VERSION "14.1.0"

NS_ :

BS_:

BU_: CUSTOMER_ECU PACMOD

//////////////////////////////////
//                              //
//  Message Definition Section  //
//                              //
//////////////////////////////////
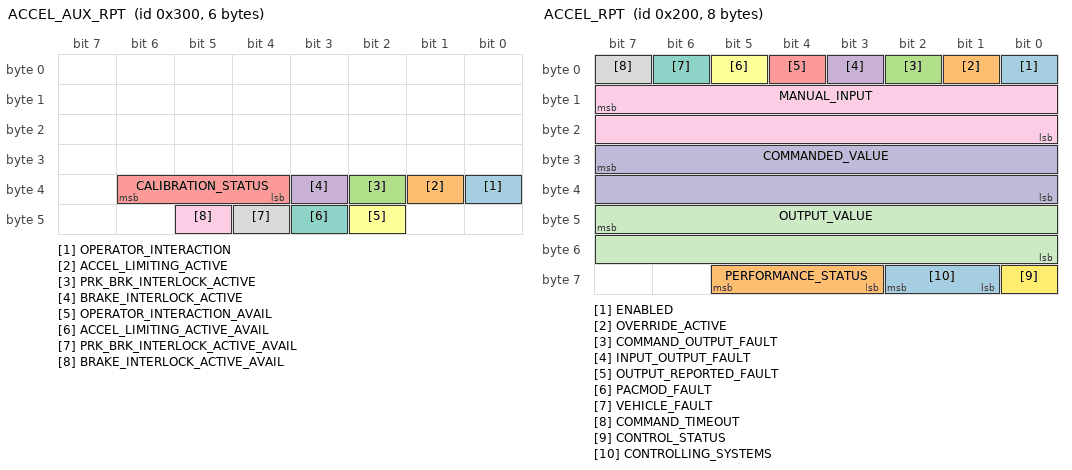
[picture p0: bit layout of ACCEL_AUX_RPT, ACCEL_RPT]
BO_ 768 ACCEL_AUX_RPT: 6 PACMOD
 SG_ OPERATOR_INTERACTION : 32|1@0+ (1,0) [0|1] ""  CUSTOMER_ECU
 SG_ ACCEL_LIMITING_ACTIVE : 33|1@0+ (1,0) [0|1] ""  CUSTOMER_ECU
 SG_ PRK_BRK_INTERLOCK_ACTIVE : 34|1@0+ (1,0) [0|1] ""  CUSTOMER_ECU
 SG_ BRAKE_INTERLOCK_ACTIVE : 35|1@0+ (1,0) [0|1] ""  CUSTOMER_ECU
 SG_ CALIBRATION_STATUS : 38|3@0+ (1,0) [0|3] ""  CUSTOMER_ECU
 SG_ OPERATOR_INTERACTION_AVAIL : 42|1@0+ (1,0) [0|1] ""  CUSTOMER_ECU
 SG_ ACCEL_LIMITING_ACTIVE_AVAIL : 43|1@0+ (1,0) [0|1] ""  CUSTOMER_ECU
 SG_ PRK_BRK_INTERLOCK_ACTIVE_AVAIL : 44|1@0+ (1,0) [0|1] ""  CUSTOMER_ECU
 SG_ BRAKE_INTERLOCK_ACTIVE_AVAIL : 45|1@0+ (1,0) [0|1] ""  CUSTOMER_ECU

BO_ 256 ACCEL_CMD: 3 CUSTOMER_ECU
 SG_ ENABLE : 0|1@0+ (1,0) [0|1] ""  PACMOD
 SG_ IGNORE_OVERRIDES : 1|1@0+ (1,0) [0|1] ""  PACMOD
 SG_ CLEAR_OVERRIDE : 2|1@0+ (1,0) [0|1] ""  PACMOD
 SG_ ACCEL_CMD : 15|16@0+ (0.001,0) [0|1] "ratio"  PACMOD

BO_ 513 ACCEL_CMD_LIMIT_RPT: 4 PACMOD
 SG_ ACCEL_CMD_LIMIT : 7|16@0+ (0.001,0) [0|1] "ratio"  CUSTOMER_ECU
 SG_ LIMITED_ACCEL_CMD : 23|16@0+ (0.001,0) [0|1] "ratio"  CUSTOMER_ECU

BO_ 1090 ACCEL_PEDAL_POSITION_VOLTAGE_RPT: 8 PACMOD
 SG_ PACMOD_VOLTAGE_IN_1 : 7|16@0+ (0.001,0) [0|65] "V"  CUSTOMER_ECU
 SG_ PACMOD_VOLTAGE_IN_2 : 23|16@0+ (0.001,0) [0|65] "V"  CUSTOMER_ECU
 SG_ PACMOD_VOLTAGE_OUT_1 : 39|16@0+ (0.001,0) [0|65] "V"  CUSTOMER_ECU
 SG_ PACMOD_VOLTAGE_OUT_2 : 55|16@0+ (0.001,0) [0|65] "V"  CUSTOMER_ECU

BO_ 512 ACCEL_RPT: 8 PACMOD
 SG_ ENABLED : 0|1@0+ (1,0) [0|1] ""  CUSTOMER_ECU
 SG_ OVERRIDE_ACTIVE : 1|1@0+ (1,0) [0|1] ""  CUSTOMER_ECU
 SG_ COMMAND_OUTPUT_FAULT : 2|1@0+ (1,0) [0|1] ""  CUSTOMER_ECU
 SG_ INPUT_OUTPUT_FAULT : 3|1@0+ (1,0) [0|1] ""  CUSTOMER_ECU
 SG_ OUTPUT_REPORTED_FAULT : 4|1@0+ (1,0) [0|1] ""  CUSTOMER_ECU
 SG_ PACMOD_FAULT : 5|1@0+ (1,0) [0|1] ""  CUSTOMER_ECU
 SG_ VEHICLE_FAULT : 6|1@0+ (1,0) [0|1] ""  CUSTOMER_ECU
 SG_ COMMAND_TIMEOUT : 7|1@0+ (1,0) [0|1] ""  CUSTOMER_ECU
 SG_ MANUAL_INPUT : 15|16@0+ (0.001,0) [0|1] "ratio"  CUSTOMER_ECU
 SG_ COMMANDED_VALUE : 31|16@0+ (0.001,0) [0|1] "ratio"  CUSTOMER_ECU
 SG_ OUTPUT_VALUE : 47|16@0+ (0.001,0) [0|1] "ratio"  CUSTOMER_ECU
 SG_ CONTROL_STATUS : 56|1@0+ (1,0) [0|1] ""  CUSTOMER_ECU
 SG_ CONTROLLING_SYSTEMS : 58|2@0+ (1,0) [0|3] ""  CUSTOMER_ECU
 SG_ PERFORMANCE_STATUS : 61|3@0+ (1,0) [0|4] ""  CUSTOMER_ECU

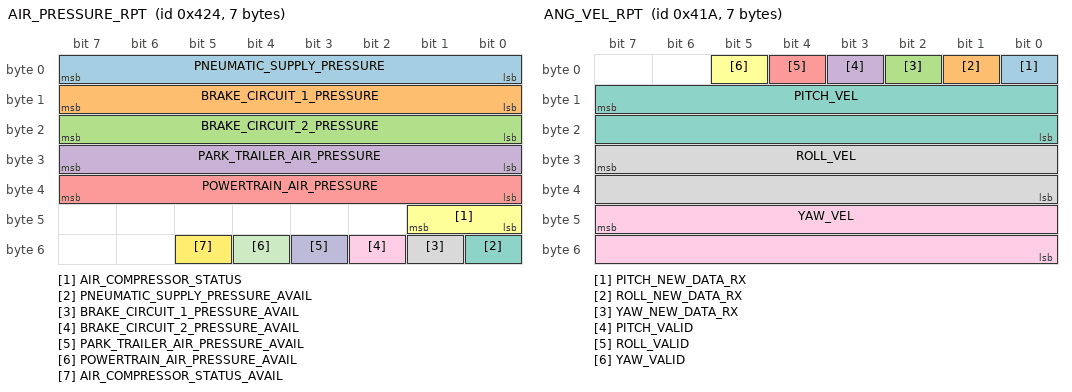
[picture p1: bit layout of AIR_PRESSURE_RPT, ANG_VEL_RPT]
BO_ 1060 AIR_PRESSURE_RPT: 7 PACMOD
 SG_ PNEUMATIC_SUPPLY_PRESSURE : 7|8@0+ (8,0) [0|2000] "kPa"  CUSTOMER_ECU
 SG_ BRAKE_CIRCUIT_1_PRESSURE : 15|8@0+ (8,0) [0|2000] "kPa"  CUSTOMER_ECU
 SG_ BRAKE_CIRCUIT_2_PRESSURE : 23|8@0+ (8,0) [0|2000] "kPa"  CUSTOMER_ECU
 SG_ PARK_TRAILER_AIR_PRESSURE : 31|8@0+ (8,0) [0|2000] "kPa"  CUSTOMER_ECU
 SG_ POWERTRAIN_AIR_PRESSURE : 39|8@0+ (8,0) [0|2000] "kPa"  CUSTOMER_ECU
 SG_ AIR_COMPRESSOR_STATUS : 41|2@0+ (1,0) [0|3] ""  CUSTOMER_ECU
 SG_ PNEUMATIC_SUPPLY_PRESSURE_AVAIL : 48|1@0+ (1,0) [0|1] ""  CUSTOMER_ECU
 SG_ BRAKE_CIRCUIT_1_PRESSURE_AVAIL : 49|1@0+ (1,0) [0|1] ""  CUSTOMER_ECU
 SG_ BRAKE_CIRCUIT_2_PRESSURE_AVAIL : 50|1@0+ (1,0) [0|1] ""  CUSTOMER_ECU
 SG_ PARK_TRAILER_AIR_PRESSURE_AVAIL : 51|1@0+ (1,0) [0|1] ""  CUSTOMER_ECU
 SG_ POWERTRAIN_AIR_PRESSURE_AVAIL : 52|1@0+ (1,0) [0|1] ""  CUSTOMER_ECU
 SG_ AIR_COMPRESSOR_STATUS_AVAIL : 53|1@0+ (1,0) [0|1] ""  CUSTOMER_ECU

BO_ 1094 AMBIENT_CONDITION_RPT: 2 PACMOD
 SG_ INTERIOR_AMBIENT_TEMP : 7|8@0+ (0.5,0) [-40|82.5] "C"  CUSTOMER_ECU
 SG_ INTERIOR_AMBIENT_TEMP_WARNING : 9|2@0+ (1,0) [0|3] ""  CUSTOMER_ECU

BO_ 1050 ANG_VEL_RPT: 7 PACMOD
 SG_ PITCH_NEW_DATA_RX : 0|1@0+ (1,0) [0|1] ""  CUSTOMER_ECU
 SG_ ROLL_NEW_DATA_RX : 1|1@0+ (1,0) [0|1] ""  CUSTOMER_ECU
 SG_ YAW_NEW_DATA_RX : 2|1@0+ (1,0) [0|1] ""  CUSTOMER_ECU
 SG_ PITCH_VALID : 3|1@0+ (1,0) [0|1] ""  CUSTOMER_ECU
 SG_ ROLL_VALID : 4|1@0+ (1,0) [0|1] ""  CUSTOMER_ECU
 SG_ YAW_VALID : 5|1@0+ (1,0) [0|1] ""  CUSTOMER_ECU
 SG_ PITCH_VEL : 15|16@0- (0.001,0) [-32.768|32.767] "rad/s"  CUSTOMER_ECU
 SG_ ROLL_VEL : 31|16@0- (0.001,0) [-32.768|32.767] "rad/s"  CUSTOMER_ECU
 SG_ YAW_VEL : 47|16@0- (0.001,0) [-32.768|32.767] "rad/s"  CUSTOMER_ECU

BO_ 1077 AUTOMS_MAN_SWITCH_RPT: 1 PACMOD
 SG_ AUTOMS_MAN_OPCTRL : 1|2@0+ (1,0) [0|2] ""  CUSTOMER_ECU
 SG_ AUTOMS_MAN_EXTCTRL : 3|2@0+ (1,0) [0|2] ""  CUSTOMER_ECU
 SG_ AUTOMS_MAN_OPCTRL_AVAIL : 4|1@0+ (1,0) [0|1] ""  CUSTOMER_ECU
 SG_ AUTOMS_MAN_EXTCTRL_AVAIL : 5|1@0+ (1,0) [0|1] ""  CUSTOMER_ECU

BO_ 1070 BATTERY_VOLTAGE_LEVEL_RPT_1: 2 PACMOD
 SG_ BATTERY_VOLTAGE_1 : 7|8@0+ (0.2,0) [0|50] "V"  CUSTOMER_ECU
 SG_ BATTERY_VOLTAGE_2 : 15|8@0+ (0.2,0) [0|50] "V"  CUSTOMER_ECU

BO_ 1081 BATTERY_VOLTAGE_LEVEL_RPT_2: 2 PACMOD
 SG_ BATTERY_VOLTAGE_1 : 7|8@0+ (0.2,0) [0|50] "V"  CUSTOMER_ECU
 SG_ BATTERY_VOLTAGE_2 : 15|8@0+ (0.2,0) [0|50] "V"  CUSTOMER_ECU

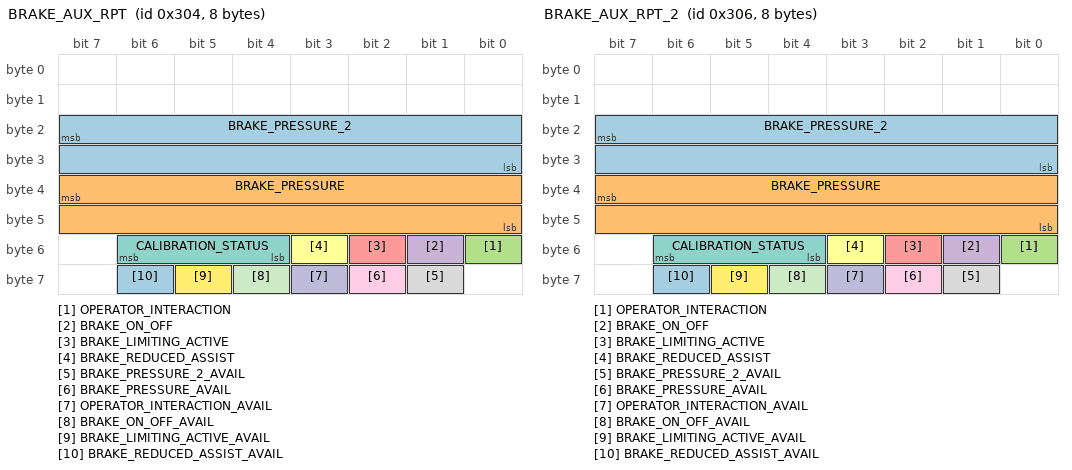
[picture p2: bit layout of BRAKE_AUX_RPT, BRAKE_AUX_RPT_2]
BO_ 772 BRAKE_AUX_RPT: 8 PACMOD
 SG_ BRAKE_PRESSURE_2 : 23|16@0+ (0.0001,0) [0|2] "ratio"  CUSTOMER_ECU
 SG_ BRAKE_PRESSURE : 39|16@0+ (0.0001,0) [0|2] "ratio"  CUSTOMER_ECU
 SG_ OPERATOR_INTERACTION : 48|1@0+ (1,0) [0|1] ""  CUSTOMER_ECU
 SG_ BRAKE_ON_OFF : 49|1@0+ (1,0) [0|1] ""  CUSTOMER_ECU
 SG_ BRAKE_LIMITING_ACTIVE : 50|1@0+ (1,0) [0|1] ""  CUSTOMER_ECU
 SG_ BRAKE_REDUCED_ASSIST : 51|1@0+ (1,0) [0|1] ""  CUSTOMER_ECU
 SG_ CALIBRATION_STATUS : 54|3@0+ (1,0) [0|3] ""  CUSTOMER_ECU
 SG_ BRAKE_PRESSURE_2_AVAIL : 57|1@0+ (1,0) [0|1] ""  CUSTOMER_ECU
 SG_ BRAKE_PRESSURE_AVAIL : 58|1@0+ (1,0) [0|1] ""  CUSTOMER_ECU
 SG_ OPERATOR_INTERACTION_AVAIL : 59|1@0+ (1,0) [0|1] ""  CUSTOMER_ECU
 SG_ BRAKE_ON_OFF_AVAIL : 60|1@0+ (1,0) [0|1] ""  CUSTOMER_ECU
 SG_ BRAKE_LIMITING_ACTIVE_AVAIL : 61|1@0+ (1,0) [0|1] ""  CUSTOMER_ECU
 SG_ BRAKE_REDUCED_ASSIST_AVAIL : 62|1@0+ (1,0) [0|1] ""  CUSTOMER_ECU

BO_ 774 BRAKE_AUX_RPT_2: 8 PACMOD
 SG_ BRAKE_PRESSURE_2 : 23|16@0+ (0.0001,0) [0|2] "ratio"  CUSTOMER_ECU
 SG_ BRAKE_PRESSURE : 39|16@0+ (0.0001,0) [0|2] "ratio"  CUSTOMER_ECU
 SG_ OPERATOR_INTERACTION : 48|1@0+ (1,0) [0|1] ""  CUSTOMER_ECU
 SG_ BRAKE_ON_OFF : 49|1@0+ (1,0) [0|1] ""  CUSTOMER_ECU
 SG_ BRAKE_LIMITING_ACTIVE : 50|1@0+ (1,0) [0|1] ""  CUSTOMER_ECU
 SG_ BRAKE_REDUCED_ASSIST : 51|1@0+ (1,0) [0|1] ""  CUSTOMER_ECU
 SG_ CALIBRATION_STATUS : 54|3@0+ (1,0) [0|3] ""  CUSTOMER_ECU
 SG_ BRAKE_PRESSURE_2_AVAIL : 57|1@0+ (1,0) [0|1] ""  CUSTOMER_ECU
 SG_ BRAKE_PRESSURE_AVAIL : 58|1@0+ (1,0) [0|1] ""  CUSTOMER_ECU
 SG_ OPERATOR_INTERACTION_AVAIL : 59|1@0+ (1,0) [0|1] ""  CUSTOMER_ECU
 SG_ BRAKE_ON_OFF_AVAIL : 60|1@0+ (1,0) [0|1] ""  CUSTOMER_ECU
 SG_ BRAKE_LIMITING_ACTIVE_AVAIL : 61|1@0+ (1,0) [0|1] ""  CUSTOMER_ECU
 SG_ BRAKE_REDUCED_ASSIST_AVAIL : 62|1@0+ (1,0) [0|1] ""  CUSTOMER_ECU

BO_ 260 BRAKE_CMD: 3 CUSTOMER_ECU
 SG_ ENABLE : 0|1@0+ (1,0) [0|1] ""  PACMOD
 SG_ IGNORE_OVERRIDES : 1|1@0+ (1,0) [0|1] ""  PACMOD
 SG_ CLEAR_OVERRIDE : 2|1@0+ (1,0) [0|1] ""  PACMOD
 SG_ BRAKE_CMD : 15|16@0+ (0.001,0) [0|1] "ratio"  PACMOD

BO_ 517 BRAKE_CMD_LIMIT_RPT: 4 PACMOD
 SG_ BRAKE_CMD_LIMIT : 7|16@0+ (0.001,0) [0|1] "ratio"  CUSTOMER_ECU
 SG_ LIMITED_BRAKE_CMD : 23|16@0+ (0.001,0) [0|1] "ratio"  CUSTOMER_ECU

BO_ 824 BRAKE_DECEL_AUX_RPT: 3 PACMOD
 SG_ XBR_ACTIVE_CONTROL_MODE : 3|4@0+ (1,0) [0|2] ""  CUSTOMER_ECU
 SG_ XBR_SYSTEM_STATE : 5|2@0+ (1,0) [0|3] ""  CUSTOMER_ECU
 SG_ FOUNDATION_BRAKE_USE : 7|2@0+ (1,0) [0|2] ""  CUSTOMER_ECU
 SG_ HILL_HOLDER_MODE : 10|3@0+ (1,0) [0|2] ""  CUSTOMER_ECU
 SG_ XBR_ACTIVE_CONTROL_MODE_AVAIL : 16|1@0+ (1,0) [0|1] ""  CUSTOMER_ECU
 SG_ XBR_SYSTEM_STATE_AVAIL : 17|1@0+ (1,0) [0|1] ""  CUSTOMER_ECU
 SG_ FOUNDATION_BRAKE_USE_AVAIL : 18|1@0+ (1,0) [0|1] ""  CUSTOMER_ECU
 SG_ HILL_HOLDER_MODE_AVAIL : 19|1@0+ (1,0) [0|1] ""  CUSTOMER_ECU

BO_ 316 BRAKE_DECEL_CMD: 4 CUSTOMER_ECU
 SG_ ENABLE : 0|1@0+ (1,0) [0|1] ""  PACMOD
 SG_ IGNORE_OVERRIDES : 1|1@0+ (1,0) [0|1] ""  PACMOD
 SG_ CLEAR_OVERRIDE : 2|1@0+ (1,0) [0|1] ""  PACMOD
 SG_ BRAKE_DECEL_CMD : 15|16@0+ (0.001,0) [0|10] "m/s^2"  PACMOD
 SG_ XBR_EBI_MODE : 25|2@0+ (1,0) [0|2] ""  PACMOD
 SG_ XBR_PRIORITY : 27|2@0+ (1,0) [0|3] ""  PACMOD
 SG_ XBR_CONTROL_MODE : 29|2@0+ (1,0) [0|2] ""  PACMOD

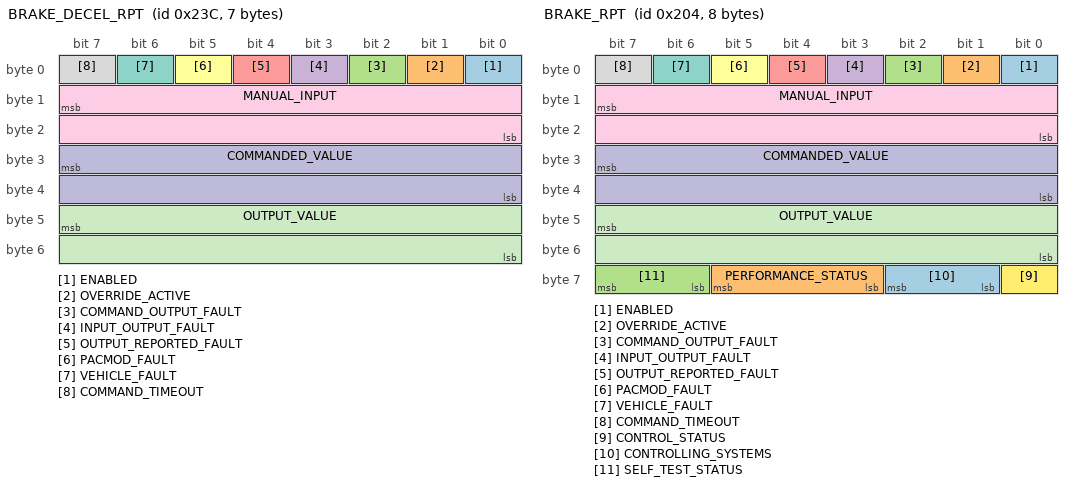
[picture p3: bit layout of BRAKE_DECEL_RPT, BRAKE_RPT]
BO_ 572 BRAKE_DECEL_RPT: 7 PACMOD
 SG_ ENABLED : 0|1@0+ (1,0) [0|1] ""  CUSTOMER_ECU
 SG_ OVERRIDE_ACTIVE : 1|1@0+ (1,0) [0|1] ""  CUSTOMER_ECU
 SG_ COMMAND_OUTPUT_FAULT : 2|1@0+ (1,0) [0|1] ""  CUSTOMER_ECU
 SG_ INPUT_OUTPUT_FAULT : 3|1@0+ (1,0) [0|1] ""  CUSTOMER_ECU
 SG_ OUTPUT_REPORTED_FAULT : 4|1@0+ (1,0) [0|1] ""  CUSTOMER_ECU
 SG_ PACMOD_FAULT : 5|1@0+ (1,0) [0|1] ""  CUSTOMER_ECU
 SG_ VEHICLE_FAULT : 6|1@0+ (1,0) [0|1] ""  CUSTOMER_ECU
 SG_ COMMAND_TIMEOUT : 7|1@0+ (1,0) [0|1] ""  CUSTOMER_ECU
 SG_ MANUAL_INPUT : 15|16@0+ (0.001,0) [0|10] "m/s^2"  CUSTOMER_ECU
 SG_ COMMANDED_VALUE : 31|16@0+ (0.001,0) [0|10] "m/s^2"  CUSTOMER_ECU
 SG_ OUTPUT_VALUE : 47|16@0+ (0.001,0) [0|10] "m/s^2"  CUSTOMER_ECU

BO_ 1091 BRAKE_MC_VOLTAGE_RPT: 8 PACMOD
 SG_ PACMOD_VOLTAGE_IN_1 : 7|16@0+ (0.001,0) [0|65] "V"  CUSTOMER_ECU
 SG_ PACMOD_VOLTAGE_IN_2 : 23|16@0+ (0.001,0) [0|65] "V"  CUSTOMER_ECU
 SG_ PACMOD_VOLTAGE_OUT_1 : 39|16@0+ (0.001,0) [0|65] "V"  CUSTOMER_ECU
 SG_ PACMOD_VOLTAGE_OUT_2 : 55|16@0+ (0.001,0) [0|65] "V"  CUSTOMER_ECU

BO_ 1025 BRAKE_MOTOR_RPT_1: 8 PACMOD
 SG_ MOTOR_CURRENT : 7|32@0- (0.001,0) [-2048.0|2048.0] "amps"  CUSTOMER_ECU
 SG_ SHAFT_POSITION : 39|32@0- (0.001,0) [-2048.0|2048.0] "radians"  CUSTOMER_ECU

BO_ 1026 BRAKE_MOTOR_RPT_2: 8 PACMOD
 SG_ ENCODER_TEMPERATURE : 7|16@0- (1,0) [-40|210] "deg_C"  CUSTOMER_ECU
 SG_ MOTOR_TEMPERATURE : 23|16@0- (1,0) [-40|210] "deg_C"  CUSTOMER_ECU
 SG_ ANGULAR_SPEED : 39|32@0- (0.001,0) [-12868.0|12868.0] "rad/s"  CUSTOMER_ECU

BO_ 1027 BRAKE_MOTOR_RPT_3: 8 PACMOD
 SG_ TORQUE_OUTPUT : 7|32@0- (0.001,0) [-2048.0|2048.0] "N-m"  CUSTOMER_ECU
 SG_ TORQUE_INPUT : 39|32@0- (0.001,0) [-2048.0|2048.0] "N-m"  CUSTOMER_ECU

BO_ 1092 BRAKE_PEDAL_POSITION_VOLTAGE_RPT: 8 PACMOD
 SG_ PACMOD_VOLTAGE_IN_1 : 7|16@0+ (0.001,0) [0|65] "V"  CUSTOMER_ECU
 SG_ PACMOD_VOLTAGE_IN_2 : 23|16@0+ (0.001,0) [0|65] "V"  CUSTOMER_ECU
 SG_ PACMOD_VOLTAGE_OUT_1 : 39|16@0+ (0.001,0) [0|65] "V"  CUSTOMER_ECU
 SG_ PACMOD_VOLTAGE_OUT_2 : 55|16@0+ (0.001,0) [0|65] "V"  CUSTOMER_ECU

BO_ 516 BRAKE_RPT: 8 PACMOD
 SG_ ENABLED : 0|1@0+ (1,0) [0|1] ""  CUSTOMER_ECU
 SG_ OVERRIDE_ACTIVE : 1|1@0+ (1,0) [0|1] ""  CUSTOMER_ECU
 SG_ COMMAND_OUTPUT_FAULT : 2|1@0+ (1,0) [0|1] ""  CUSTOMER_ECU
 SG_ INPUT_OUTPUT_FAULT : 3|1@0+ (1,0) [0|1] ""  CUSTOMER_ECU
 SG_ OUTPUT_REPORTED_FAULT : 4|1@0+ (1,0) [0|1] ""  CUSTOMER_ECU
 SG_ PACMOD_FAULT : 5|1@0+ (1,0) [0|1] ""  CUSTOMER_ECU
 SG_ VEHICLE_FAULT : 6|1@0+ (1,0) [0|1] ""  CUSTOMER_ECU
 SG_ COMMAND_TIMEOUT : 7|1@0+ (1,0) [0|1] ""  CUSTOMER_ECU
 SG_ MANUAL_INPUT : 15|16@0+ (0.001,0) [0|1] "ratio"  CUSTOMER_ECU
 SG_ COMMANDED_VALUE : 31|16@0+ (0.001,0) [0|1] "ratio"  CUSTOMER_ECU
 SG_ OUTPUT_VALUE : 47|16@0+ (0.001,0) [0|1] "ratio"  CUSTOMER_ECU
 SG_ CONTROL_STATUS : 56|1@0+ (1,0) [0|1] ""  CUSTOMER_ECU
 SG_ CONTROLLING_SYSTEMS : 58|2@0+ (1,0) [0|3] ""  CUSTOMER_ECU
 SG_ PERFORMANCE_STATUS : 61|3@0+ (1,0) [0|4] ""  CUSTOMER_ECU
 SG_ SELF_TEST_STATUS : 63|2@0+ (1,0) [0|3] ""  CUSTOMER_ECU

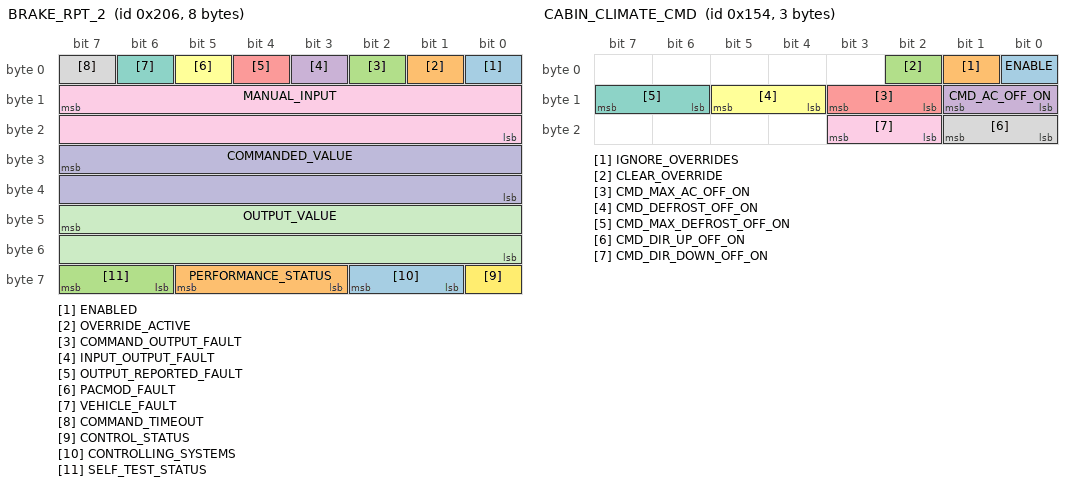
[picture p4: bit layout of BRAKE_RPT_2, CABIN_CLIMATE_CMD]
BO_ 518 BRAKE_RPT_2: 8 PACMOD
 SG_ ENABLED : 0|1@0+ (1,0) [0|1] ""  CUSTOMER_ECU
 SG_ OVERRIDE_ACTIVE : 1|1@0+ (1,0) [0|1] ""  CUSTOMER_ECU
 SG_ COMMAND_OUTPUT_FAULT : 2|1@0+ (1,0) [0|1] ""  CUSTOMER_ECU
 SG_ INPUT_OUTPUT_FAULT : 3|1@0+ (1,0) [0|1] ""  CUSTOMER_ECU
 SG_ OUTPUT_REPORTED_FAULT : 4|1@0+ (1,0) [0|1] ""  CUSTOMER_ECU
 SG_ PACMOD_FAULT : 5|1@0+ (1,0) [0|1] ""  CUSTOMER_ECU
 SG_ VEHICLE_FAULT : 6|1@0+ (1,0) [0|1] ""  CUSTOMER_ECU
 SG_ COMMAND_TIMEOUT : 7|1@0+ (1,0) [0|1] ""  CUSTOMER_ECU
 SG_ MANUAL_INPUT : 15|16@0+ (0.001,0) [0|1] "ratio"  CUSTOMER_ECU
 SG_ COMMANDED_VALUE : 31|16@0+ (0.001,0) [0|1] "ratio"  CUSTOMER_ECU
 SG_ OUTPUT_VALUE : 47|16@0+ (0.001,0) [0|1] "ratio"  CUSTOMER_ECU
 SG_ CONTROL_STATUS : 56|1@0+ (1,0) [0|1] ""  CUSTOMER_ECU
 SG_ CONTROLLING_SYSTEMS : 58|2@0+ (1,0) [0|3] ""  CUSTOMER_ECU
 SG_ PERFORMANCE_STATUS : 61|3@0+ (1,0) [0|4] ""  CUSTOMER_ECU
 SG_ SELF_TEST_STATUS : 63|2@0+ (1,0) [0|3] ""  CUSTOMER_ECU

BO_ 340 CABIN_CLIMATE_CMD: 3 CUSTOMER_ECU
 SG_ ENABLE : 0|1@0+ (1,0) [0|1] ""  PACMOD
 SG_ IGNORE_OVERRIDES : 1|1@0+ (1,0) [0|1] ""  PACMOD
 SG_ CLEAR_OVERRIDE : 2|1@0+ (1,0) [0|1] ""  PACMOD
 SG_ CMD_AC_OFF_ON : 9|2@0+ (1,0) [0|1] ""  PACMOD
 SG_ CMD_MAX_AC_OFF_ON : 11|2@0+ (1,0) [0|1] ""  PACMOD
 SG_ CMD_DEFROST_OFF_ON : 13|2@0+ (1,0) [0|1] ""  PACMOD
 SG_ CMD_MAX_DEFROST_OFF_ON : 15|2@0+ (1,0) [0|1] ""  PACMOD
 SG_ CMD_DIR_UP_OFF_ON : 17|2@0+ (1,0) [0|1] ""  PACMOD
 SG_ CMD_DIR_DOWN_OFF_ON : 19|2@0+ (1,0) [0|1] ""  PACMOD

BO_ 596 CABIN_CLIMATE_RPT: 7 PACMOD
 SG_ ENABLED : 0|1@0+ (1,0) [0|1] ""  CUSTOMER_ECU
 SG_ OVERRIDE_ACTIVE : 1|1@0+ (1,0) [0|1] ""  CUSTOMER_ECU
 SG_ COMMAND_OUTPUT_FAULT : 2|1@0+ (1,0) [0|1] ""  CUSTOMER_ECU
 SG_ INPUT_OUTPUT_FAULT : 3|1@0+ (1,0) [0|1] ""  CUSTOMER_ECU
 SG_ OUTPUT_REPORTED_FAULT : 4|1@0+ (1,0) [0|1] ""  CUSTOMER_ECU
 SG_ PACMOD_FAULT : 5|1@0+ (1,0) [0|1] ""  CUSTOMER_ECU
 SG_ VEHICLE_FAULT : 6|1@0+ (1,0) [0|1] ""  CUSTOMER_ECU
 SG_ COMMAND_TIMEOUT : 7|1@0+ (1,0) [0|1] ""  CUSTOMER_ECU
 SG_ MAN_AC_OFF_ON : 9|2@0+ (1,0) [0|3] ""  CUSTOMER_ECU
 SG_ MAN_MAX_AC_OFF_ON : 11|2@0+ (1,0) [0|3] ""  CUSTOMER_ECU
 SG_ MAN_DEFROST_OFF_ON : 13|2@0+ (1,0) [0|3] ""  CUSTOMER_ECU
 SG_ MAN_MAX_DEFROST_OFF_ON : 15|2@0+ (1,0) [0|3] ""  CUSTOMER_ECU
 SG_ MAN_DIR_UP_OFF_ON : 17|2@0+ (1,0) [0|3] ""  CUSTOMER_ECU
 SG_ MAN_DIR_DOWN_OFF_ON : 19|2@0+ (1,0) [0|3] ""  CUSTOMER_ECU
 SG_ CMD_AC_OFF_ON : 25|2@0+ (1,0) [0|3] ""  CUSTOMER_ECU
 SG_ CMD_MAX_AC_OFF_ON : 27|2@0+ (1,0) [0|3] ""  CUSTOMER_ECU
 SG_ CMD_DEFROST_OFF_ON : 29|2@0+ (1,0) [0|3] ""  CUSTOMER_ECU
 SG_ CMD_MAX_DEFROST_OFF_ON : 31|2@0+ (1,0) [0|3] ""  CUSTOMER_ECU
 SG_ CMD_DIR_UP_OFF_ON : 33|2@0+ (1,0) [0|3] ""  CUSTOMER_ECU
 SG_ CMD_DIR_DOWN_OFF_ON : 35|2@0+ (1,0) [0|3] ""  CUSTOMER_ECU
 SG_ OUT_AC_OFF_ON : 41|2@0+ (1,0) [0|3] ""  CUSTOMER_ECU
 SG_ OUT_MAX_AC_OFF_ON : 43|2@0+ (1,0) [0|3] ""  CUSTOMER_ECU
 SG_ OUT_DEFROST_OFF_ON : 45|2@0+ (1,0) [0|3] ""  CUSTOMER_ECU
 SG_ OUT_MAX_DEFROST_OFF_ON : 47|2@0+ (1,0) [0|3] ""  CUSTOMER_ECU
 SG_ OUT_DIR_UP_OFF_ON : 49|2@0+ (1,0) [0|3] ""  CUSTOMER_ECU
 SG_ OUT_DIR_DOWN_OFF_ON : 51|2@0+ (1,0) [0|3] ""  CUSTOMER_ECU

BO_ 336 CABIN_FAN_SPEED_CMD: 2 CUSTOMER_ECU
 SG_ ENABLE : 0|1@0+ (1,0) [0|1] ""  PACMOD
 SG_ IGNORE_OVERRIDES : 1|1@0+ (1,0) [0|1] ""  PACMOD
 SG_ CLEAR_OVERRIDE : 2|1@0+ (1,0) [0|1] ""  PACMOD
 SG_ CABIN_FAN_SPEED_CMD : 15|8@0+ (1,0) [0|10] ""  PACMOD

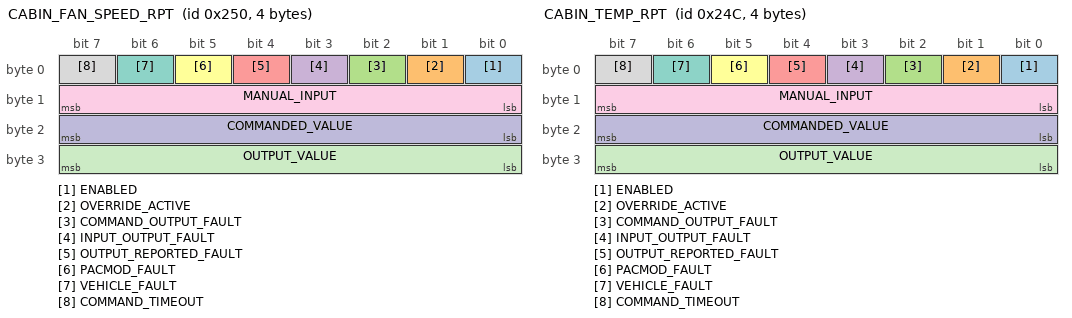
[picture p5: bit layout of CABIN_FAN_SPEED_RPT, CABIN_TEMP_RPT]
BO_ 592 CABIN_FAN_SPEED_RPT: 4 PACMOD
 SG_ ENABLED : 0|1@0+ (1,0) [0|1] ""  CUSTOMER_ECU
 SG_ OVERRIDE_ACTIVE : 1|1@0+ (1,0) [0|1] ""  CUSTOMER_ECU
 SG_ COMMAND_OUTPUT_FAULT : 2|1@0+ (1,0) [0|1] ""  CUSTOMER_ECU
 SG_ INPUT_OUTPUT_FAULT : 3|1@0+ (1,0) [0|1] ""  CUSTOMER_ECU
 SG_ OUTPUT_REPORTED_FAULT : 4|1@0+ (1,0) [0|1] ""  CUSTOMER_ECU
 SG_ PACMOD_FAULT : 5|1@0+ (1,0) [0|1] ""  CUSTOMER_ECU
 SG_ VEHICLE_FAULT : 6|1@0+ (1,0) [0|1] ""  CUSTOMER_ECU
 SG_ COMMAND_TIMEOUT : 7|1@0+ (1,0) [0|1] ""  CUSTOMER_ECU
 SG_ MANUAL_INPUT : 15|8@0+ (1,0) [0|255] ""  CUSTOMER_ECU
 SG_ COMMANDED_VALUE : 23|8@0+ (1,0) [0|255] ""  CUSTOMER_ECU
 SG_ OUTPUT_VALUE : 31|8@0+ (1,0) [0|255] ""  CUSTOMER_ECU

BO_ 332 CABIN_TEMP_CMD: 2 CUSTOMER_ECU
 SG_ ENABLE : 0|1@0+ (1,0) [0|1] ""  PACMOD
 SG_ IGNORE_OVERRIDES : 1|1@0+ (1,0) [0|1] ""  PACMOD
 SG_ CLEAR_OVERRIDE : 2|1@0+ (1,0) [0|1] ""  PACMOD
 SG_ CABIN_TEMP_CMD : 15|8@0+ (0.1,10) [10|35] "deg_C"  PACMOD

BO_ 588 CABIN_TEMP_RPT: 4 PACMOD
 SG_ ENABLED : 0|1@0+ (1,0) [0|1] ""  CUSTOMER_ECU
 SG_ OVERRIDE_ACTIVE : 1|1@0+ (1,0) [0|1] ""  CUSTOMER_ECU
 SG_ COMMAND_OUTPUT_FAULT : 2|1@0+ (1,0) [0|1] ""  CUSTOMER_ECU
 SG_ INPUT_OUTPUT_FAULT : 3|1@0+ (1,0) [0|1] ""  CUSTOMER_ECU
 SG_ OUTPUT_REPORTED_FAULT : 4|1@0+ (1,0) [0|1] ""  CUSTOMER_ECU
 SG_ PACMOD_FAULT : 5|1@0+ (1,0) [0|1] ""  CUSTOMER_ECU
 SG_ VEHICLE_FAULT : 6|1@0+ (1,0) [0|1] ""  CUSTOMER_ECU
 SG_ COMMAND_TIMEOUT : 7|1@0+ (1,0) [0|1] ""  CUSTOMER_ECU
 SG_ MANUAL_INPUT : 15|8@0+ (0.1,10) [10|35] "deg_C"  CUSTOMER_ECU
 SG_ COMMANDED_VALUE : 23|8@0+ (0.1,10) [10|35] "deg_C"  CUSTOMER_ECU
 SG_ OUTPUT_VALUE : 31|8@0+ (0.1,10) [10|35] "deg_C"  CUSTOMER_ECU

BO_ 1100 COMPONENT_AUX_RPT_00: 1 PACMOD
 SG_ LOCATION_CODE : 3|4@0+ (1,0) [0|15] "" CUSTOMER_ECU
 SG_ KEY_SWITCH_STATUS : 5|2@0+ (1,0) [0|3] "" CUSTOMER_ECU

BO_ 1101 COMPONENT_AUX_RPT_01: 1 PACMOD
 SG_ LOCATION_CODE : 3|4@0+ (1,0) [0|15] "" CUSTOMER_ECU
 SG_ KEY_SWITCH_STATUS : 5|2@0+ (1,0) [0|3] "" CUSTOMER_ECU

BO_ 1102 COMPONENT_AUX_RPT_02: 1 PACMOD
 SG_ LOCATION_CODE : 3|4@0+ (1,0) [0|15] "" CUSTOMER_ECU
 SG_ KEY_SWITCH_STATUS : 5|2@0+ (1,0) [0|3] "" CUSTOMER_ECU

BO_ 1103 COMPONENT_AUX_RPT_03: 1 PACMOD
 SG_ LOCATION_CODE : 3|4@0+ (1,0) [0|15] "" CUSTOMER_ECU
 SG_ KEY_SWITCH_STATUS : 5|2@0+ (1,0) [0|3] "" CUSTOMER_ECU

BO_ 1104 COMPONENT_AUX_RPT_04: 1 PACMOD
 SG_ LOCATION_CODE : 3|4@0+ (1,0) [0|15] "" CUSTOMER_ECU
 SG_ KEY_SWITCH_STATUS : 5|2@0+ (1,0) [0|3] "" CUSTOMER_ECU

BO_ 1105 COMPONENT_AUX_RPT_05: 1 PACMOD
 SG_ LOCATION_CODE : 3|4@0+ (1,0) [0|15] "" CUSTOMER_ECU
 SG_ KEY_SWITCH_STATUS : 5|2@0+ (1,0) [0|3] "" CUSTOMER_ECU

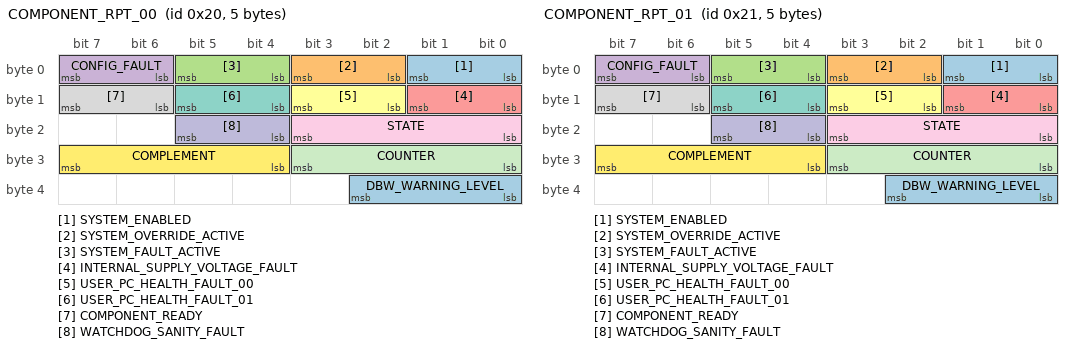
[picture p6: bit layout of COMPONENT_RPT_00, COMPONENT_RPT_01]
BO_ 32 COMPONENT_RPT_00: 5 PACMOD
 SG_ SYSTEM_ENABLED : 1|2@0+ (1,0) [0|3] "" CUSTOMER_ECU
 SG_ SYSTEM_OVERRIDE_ACTIVE : 3|2@0+ (1,0) [0|3] "" CUSTOMER_ECU
 SG_ SYSTEM_FAULT_ACTIVE : 5|2@0+ (1,0) [0|3] "" CUSTOMER_ECU
 SG_ CONFIG_FAULT : 7|2@0+ (1,0) [0|3] "" CUSTOMER_ECU
 SG_ INTERNAL_SUPPLY_VOLTAGE_FAULT : 9|2@0+ (1,0) [0|3] "" CUSTOMER_ECU
 SG_ USER_PC_HEALTH_FAULT_00 : 11|2@0+ (1,0) [0|3] "" CUSTOMER_ECU
 SG_ USER_PC_HEALTH_FAULT_01 : 13|2@0+ (1,0) [0|3] "" CUSTOMER_ECU
 SG_ COMPONENT_READY : 15|2@0+ (1,0) [0|3] "" CUSTOMER_ECU
 SG_ STATE : 19|4@0+ (1,0) [0|15] "" CUSTOMER_ECU
 SG_ WATCHDOG_SANITY_FAULT : 21|2@0+ (1,0) [0|3] "" CUSTOMER_ECU
 SG_ COUNTER : 27|4@0+ (1,0) [0|15] "" CUSTOMER_ECU
 SG_ COMPLEMENT : 31|4@0+ (1,0) [0|15] "" CUSTOMER_ECU
 SG_ DBW_WARNING_LEVEL : 34|3@0+ (1,0) [0|3] "" CUSTOMER_ECU

BO_ 33 COMPONENT_RPT_01: 5 PACMOD
 SG_ SYSTEM_ENABLED : 1|2@0+ (1,0) [0|3] "" CUSTOMER_ECU
 SG_ SYSTEM_OVERRIDE_ACTIVE : 3|2@0+ (1,0) [0|3] "" CUSTOMER_ECU
 SG_ SYSTEM_FAULT_ACTIVE : 5|2@0+ (1,0) [0|3] "" CUSTOMER_ECU
 SG_ CONFIG_FAULT : 7|2@0+ (1,0) [0|3] "" CUSTOMER_ECU
 SG_ INTERNAL_SUPPLY_VOLTAGE_FAULT : 9|2@0+ (1,0) [0|3] "" CUSTOMER_ECU
 SG_ USER_PC_HEALTH_FAULT_00 : 11|2@0+ (1,0) [0|3] "" CUSTOMER_ECU
 SG_ USER_PC_HEALTH_FAULT_01 : 13|2@0+ (1,0) [0|3] "" CUSTOMER_ECU
 SG_ COMPONENT_READY : 15|2@0+ (1,0) [0|3] "" CUSTOMER_ECU
 SG_ STATE : 19|4@0+ (1,0) [0|15] "" CUSTOMER_ECU
 SG_ WATCHDOG_SANITY_FAULT : 21|2@0+ (1,0) [0|3] "" CUSTOMER_ECU
 SG_ COUNTER : 27|4@0+ (1,0) [0|15] "" CUSTOMER_ECU
 SG_ COMPLEMENT : 31|4@0+ (1,0) [0|15] "" CUSTOMER_ECU
 SG_ DBW_WARNING_LEVEL : 34|3@0+ (1,0) [0|3] "" CUSTOMER_ECU

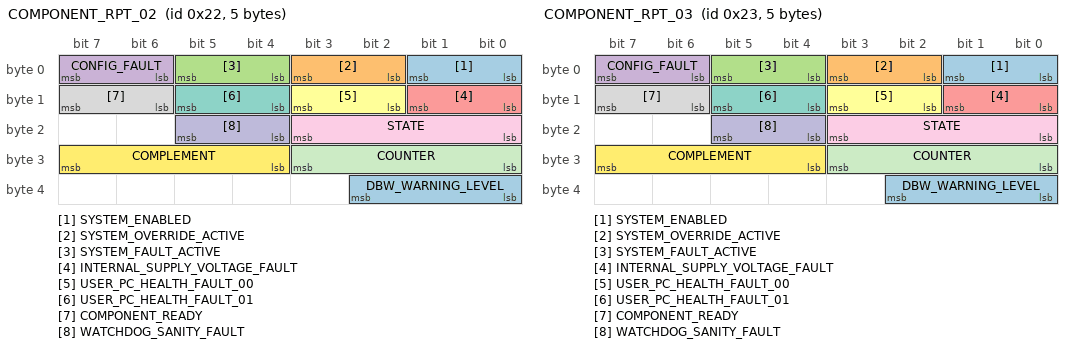
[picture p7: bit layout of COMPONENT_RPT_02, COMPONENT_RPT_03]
BO_ 34 COMPONENT_RPT_02: 5 PACMOD
 SG_ SYSTEM_ENABLED : 1|2@0+ (1,0) [0|3] "" CUSTOMER_ECU
 SG_ SYSTEM_OVERRIDE_ACTIVE : 3|2@0+ (1,0) [0|3] "" CUSTOMER_ECU
 SG_ SYSTEM_FAULT_ACTIVE : 5|2@0+ (1,0) [0|3] "" CUSTOMER_ECU
 SG_ CONFIG_FAULT : 7|2@0+ (1,0) [0|3] "" CUSTOMER_ECU
 SG_ INTERNAL_SUPPLY_VOLTAGE_FAULT : 9|2@0+ (1,0) [0|3] "" CUSTOMER_ECU
 SG_ USER_PC_HEALTH_FAULT_00 : 11|2@0+ (1,0) [0|3] "" CUSTOMER_ECU
 SG_ USER_PC_HEALTH_FAULT_01 : 13|2@0+ (1,0) [0|3] "" CUSTOMER_ECU
 SG_ COMPONENT_READY : 15|2@0+ (1,0) [0|3] "" CUSTOMER_ECU
 SG_ STATE : 19|4@0+ (1,0) [0|15] "" CUSTOMER_ECU
 SG_ WATCHDOG_SANITY_FAULT : 21|2@0+ (1,0) [0|3] "" CUSTOMER_ECU
 SG_ COUNTER : 27|4@0+ (1,0) [0|15] "" CUSTOMER_ECU
 SG_ COMPLEMENT : 31|4@0+ (1,0) [0|15] "" CUSTOMER_ECU
 SG_ DBW_WARNING_LEVEL : 34|3@0+ (1,0) [0|3] "" CUSTOMER_ECU

BO_ 35 COMPONENT_RPT_03: 5 PACMOD
 SG_ SYSTEM_ENABLED : 1|2@0+ (1,0) [0|3] "" CUSTOMER_ECU
 SG_ SYSTEM_OVERRIDE_ACTIVE : 3|2@0+ (1,0) [0|3] "" CUSTOMER_ECU
 SG_ SYSTEM_FAULT_ACTIVE : 5|2@0+ (1,0) [0|3] "" CUSTOMER_ECU
 SG_ CONFIG_FAULT : 7|2@0+ (1,0) [0|3] "" CUSTOMER_ECU
 SG_ INTERNAL_SUPPLY_VOLTAGE_FAULT : 9|2@0+ (1,0) [0|3] "" CUSTOMER_ECU
 SG_ USER_PC_HEALTH_FAULT_00 : 11|2@0+ (1,0) [0|3] "" CUSTOMER_ECU
 SG_ USER_PC_HEALTH_FAULT_01 : 13|2@0+ (1,0) [0|3] "" CUSTOMER_ECU
 SG_ COMPONENT_READY : 15|2@0+ (1,0) [0|3] "" CUSTOMER_ECU
 SG_ STATE : 19|4@0+ (1,0) [0|15] "" CUSTOMER_ECU
 SG_ WATCHDOG_SANITY_FAULT : 21|2@0+ (1,0) [0|3] "" CUSTOMER_ECU
 SG_ COUNTER : 27|4@0+ (1,0) [0|15] "" CUSTOMER_ECU
 SG_ COMPLEMENT : 31|4@0+ (1,0) [0|15] "" CUSTOMER_ECU
 SG_ DBW_WARNING_LEVEL : 34|3@0+ (1,0) [0|3] "" CUSTOMER_ECU

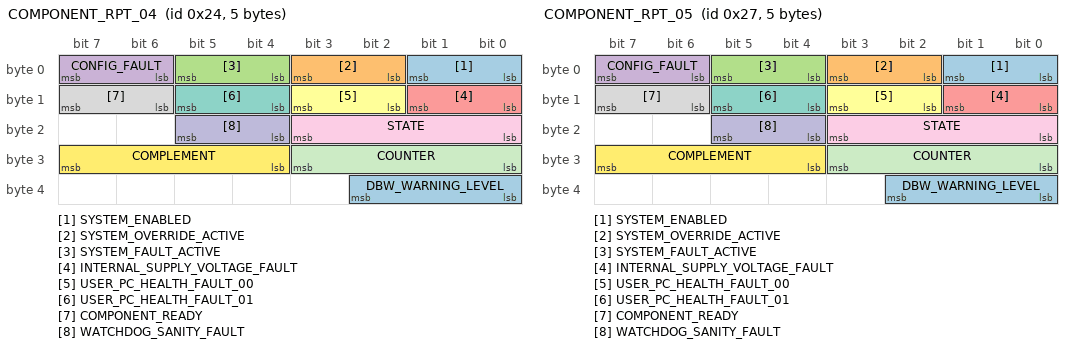
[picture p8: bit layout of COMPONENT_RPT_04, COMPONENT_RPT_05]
BO_ 36 COMPONENT_RPT_04: 5 PACMOD
 SG_ SYSTEM_ENABLED : 1|2@0+ (1,0) [0|3] "" CUSTOMER_ECU
 SG_ SYSTEM_OVERRIDE_ACTIVE : 3|2@0+ (1,0) [0|3] "" CUSTOMER_ECU
 SG_ SYSTEM_FAULT_ACTIVE : 5|2@0+ (1,0) [0|3] "" CUSTOMER_ECU
 SG_ CONFIG_FAULT : 7|2@0+ (1,0) [0|3] "" CUSTOMER_ECU
 SG_ INTERNAL_SUPPLY_VOLTAGE_FAULT : 9|2@0+ (1,0) [0|3] "" CUSTOMER_ECU
 SG_ USER_PC_HEALTH_FAULT_00 : 11|2@0+ (1,0) [0|3] "" CUSTOMER_ECU
 SG_ USER_PC_HEALTH_FAULT_01 : 13|2@0+ (1,0) [0|3] "" CUSTOMER_ECU
 SG_ COMPONENT_READY : 15|2@0+ (1,0) [0|3] "" CUSTOMER_ECU
 SG_ STATE : 19|4@0+ (1,0) [0|15] "" CUSTOMER_ECU
 SG_ WATCHDOG_SANITY_FAULT : 21|2@0+ (1,0) [0|3] "" CUSTOMER_ECU
 SG_ COUNTER : 27|4@0+ (1,0) [0|15] "" CUSTOMER_ECU
 SG_ COMPLEMENT : 31|4@0+ (1,0) [0|15] "" CUSTOMER_ECU
 SG_ DBW_WARNING_LEVEL : 34|3@0+ (1,0) [0|3] "" CUSTOMER_ECU

BO_ 39 COMPONENT_RPT_05: 5 PACMOD
 SG_ SYSTEM_ENABLED : 1|2@0+ (1,0) [0|3] "" CUSTOMER_ECU
 SG_ SYSTEM_OVERRIDE_ACTIVE : 3|2@0+ (1,0) [0|3] "" CUSTOMER_ECU
 SG_ SYSTEM_FAULT_ACTIVE : 5|2@0+ (1,0) [0|3] "" CUSTOMER_ECU
 SG_ CONFIG_FAULT : 7|2@0+ (1,0) [0|3] "" CUSTOMER_ECU
 SG_ INTERNAL_SUPPLY_VOLTAGE_FAULT : 9|2@0+ (1,0) [0|3] "" CUSTOMER_ECU
 SG_ USER_PC_HEALTH_FAULT_00 : 11|2@0+ (1,0) [0|3] "" CUSTOMER_ECU
 SG_ USER_PC_HEALTH_FAULT_01 : 13|2@0+ (1,0) [0|3] "" CUSTOMER_ECU
 SG_ COMPONENT_READY : 15|2@0+ (1,0) [0|3] "" CUSTOMER_ECU
 SG_ STATE : 19|4@0+ (1,0) [0|15] "" CUSTOMER_ECU
 SG_ WATCHDOG_SANITY_FAULT : 21|2@0+ (1,0) [0|3] "" CUSTOMER_ECU
 SG_ COUNTER : 27|4@0+ (1,0) [0|15] "" CUSTOMER_ECU
 SG_ COMPLEMENT : 31|4@0+ (1,0) [0|15] "" CUSTOMER_ECU
 SG_ DBW_WARNING_LEVEL : 34|3@0+ (1,0) [0|3] "" CUSTOMER_ECU

BO_ 264 CRUISE_CONTROL_BUTTONS_CMD: 2 CUSTOMER_ECU
 SG_ ENABLE : 0|1@0+ (1,0) [0|1] ""  PACMOD
 SG_ IGNORE_OVERRIDES : 1|1@0+ (1,0) [0|1] ""  PACMOD
 SG_ CLEAR_OVERRIDE : 2|1@0+ (1,0) [0|1] ""  PACMOD
 SG_ CRUISE_CONTROL_BUTTON : 15|8@0+ (1,0) [0|255] ""  PACMOD

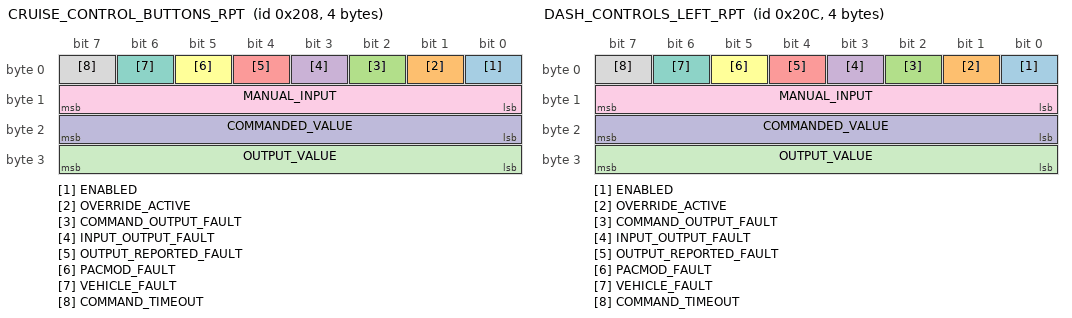
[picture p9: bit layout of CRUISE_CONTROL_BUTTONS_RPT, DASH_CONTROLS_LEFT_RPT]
BO_ 520 CRUISE_CONTROL_BUTTONS_RPT: 4 PACMOD
 SG_ ENABLED : 0|1@0+ (1,0) [0|1] ""  CUSTOMER_ECU
 SG_ OVERRIDE_ACTIVE : 1|1@0+ (1,0) [0|1] ""  CUSTOMER_ECU
 SG_ COMMAND_OUTPUT_FAULT : 2|1@0+ (1,0) [0|1] ""  CUSTOMER_ECU
 SG_ INPUT_OUTPUT_FAULT : 3|1@0+ (1,0) [0|1] ""  CUSTOMER_ECU
 SG_ OUTPUT_REPORTED_FAULT : 4|1@0+ (1,0) [0|1] ""  CUSTOMER_ECU
 SG_ PACMOD_FAULT : 5|1@0+ (1,0) [0|1] ""  CUSTOMER_ECU
 SG_ VEHICLE_FAULT : 6|1@0+ (1,0) [0|1] ""  CUSTOMER_ECU
 SG_ COMMAND_TIMEOUT : 7|1@0+ (1,0) [0|1] ""  CUSTOMER_ECU
 SG_ MANUAL_INPUT : 15|8@0+ (1,0) [0|255] ""  CUSTOMER_ECU
 SG_ COMMANDED_VALUE : 23|8@0+ (1,0) [0|255] ""  CUSTOMER_ECU
 SG_ OUTPUT_VALUE : 31|8@0+ (1,0) [0|255] ""  CUSTOMER_ECU

BO_ 268 DASH_CONTROLS_LEFT_CMD: 2 CUSTOMER_ECU
 SG_ ENABLE : 0|1@0+ (1,0) [0|1] ""  PACMOD
 SG_ IGNORE_OVERRIDES : 1|1@0+ (1,0) [0|1] ""  PACMOD
 SG_ CLEAR_OVERRIDE : 2|1@0+ (1,0) [0|1] ""  PACMOD
 SG_ DASH_CONTROLS_BUTTON : 15|8@0+ (1,0) [0|255] ""  PACMOD

BO_ 524 DASH_CONTROLS_LEFT_RPT: 4 PACMOD
 SG_ ENABLED : 0|1@0+ (1,0) [0|1] ""  CUSTOMER_ECU
 SG_ OVERRIDE_ACTIVE : 1|1@0+ (1,0) [0|1] ""  CUSTOMER_ECU
 SG_ COMMAND_OUTPUT_FAULT : 2|1@0+ (1,0) [0|1] ""  CUSTOMER_ECU
 SG_ INPUT_OUTPUT_FAULT : 3|1@0+ (1,0) [0|1] ""  CUSTOMER_ECU
 SG_ OUTPUT_REPORTED_FAULT : 4|1@0+ (1,0) [0|1] ""  CUSTOMER_ECU
 SG_ PACMOD_FAULT : 5|1@0+ (1,0) [0|1] ""  CUSTOMER_ECU
 SG_ VEHICLE_FAULT : 6|1@0+ (1,0) [0|1] ""  CUSTOMER_ECU
 SG_ COMMAND_TIMEOUT : 7|1@0+ (1,0) [0|1] ""  CUSTOMER_ECU
 SG_ MANUAL_INPUT : 15|8@0+ (1,0) [0|255] ""  CUSTOMER_ECU
 SG_ COMMANDED_VALUE : 23|8@0+ (1,0) [0|255] ""  CUSTOMER_ECU
 SG_ OUTPUT_VALUE : 31|8@0+ (1,0) [0|255] ""  CUSTOMER_ECU

BO_ 272 DASH_CONTROLS_RIGHT_CMD: 2 CUSTOMER_ECU
 SG_ ENABLE : 0|1@0+ (1,0) [0|1] ""  PACMOD
 SG_ IGNORE_OVERRIDES : 1|1@0+ (1,0) [0|1] ""  PACMOD
 SG_ CLEAR_OVERRIDE : 2|1@0+ (1,0) [0|1] ""  PACMOD
 SG_ DASH_CONTROLS_BUTTON : 15|8@0+ (1,0) [0|255] ""  PACMOD

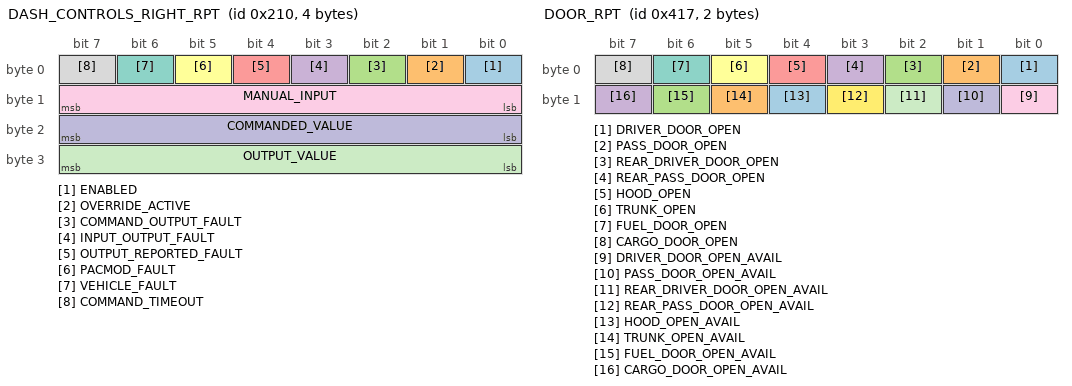
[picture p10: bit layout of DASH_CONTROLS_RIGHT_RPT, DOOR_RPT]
BO_ 528 DASH_CONTROLS_RIGHT_RPT: 4 PACMOD
 SG_ ENABLED : 0|1@0+ (1,0) [0|1] ""  CUSTOMER_ECU
 SG_ OVERRIDE_ACTIVE : 1|1@0+ (1,0) [0|1] ""  CUSTOMER_ECU
 SG_ COMMAND_OUTPUT_FAULT : 2|1@0+ (1,0) [0|1] ""  CUSTOMER_ECU
 SG_ INPUT_OUTPUT_FAULT : 3|1@0+ (1,0) [0|1] ""  CUSTOMER_ECU
 SG_ OUTPUT_REPORTED_FAULT : 4|1@0+ (1,0) [0|1] ""  CUSTOMER_ECU
 SG_ PACMOD_FAULT : 5|1@0+ (1,0) [0|1] ""  CUSTOMER_ECU
 SG_ VEHICLE_FAULT : 6|1@0+ (1,0) [0|1] ""  CUSTOMER_ECU
 SG_ COMMAND_TIMEOUT : 7|1@0+ (1,0) [0|1] ""  CUSTOMER_ECU
 SG_ MANUAL_INPUT : 15|8@0+ (1,0) [0|255] ""  CUSTOMER_ECU
 SG_ COMMANDED_VALUE : 23|8@0+ (1,0) [0|255] ""  CUSTOMER_ECU
 SG_ OUTPUT_VALUE : 31|8@0+ (1,0) [0|255] ""  CUSTOMER_ECU

BO_ 1039 DATE_TIME_RPT: 6 PACMOD
 SG_ DATE_YEAR : 7|8@0+ (1,2000) [2000|2255] "yr"  CUSTOMER_ECU
 SG_ DATE_MONTH : 15|8@0+ (1,1) [1|12] "mon"  CUSTOMER_ECU
 SG_ DATE_DAY : 23|8@0+ (1,1) [1|31] "dy"  CUSTOMER_ECU
 SG_ TIME_HOUR : 31|8@0+ (1,0) [0|23] "hr"  CUSTOMER_ECU
 SG_ TIME_MINUTE : 39|8@0+ (1,0) [0|60] "min"  CUSTOMER_ECU
 SG_ TIME_SECOND : 47|8@0+ (1,0) [0|60] "sec"  CUSTOMER_ECU

BO_ 40 DBW_HEALTH_RPT_00: 3 PACMOD
 SG_ COUNTER : 7|8@0+ (1,0) [0|255] ""  CUSTOMER_ECU
 SG_ CHECKSUM : 15|8@0+ (1,0) [0|255] ""  CUSTOMER_ECU
 SG_ USER_CAN_NTWRK_INTEGRITY_FAULT : 17|2@0+ (1,0) [0|4] ""  CUSTOMER_ECU
 SG_ DBW_WARNING_LEVEL : 20|3@0+ (1,0) [0|3] ""  CUSTOMER_ECU
 SG_ SELF_TEST_STATUS : 23|3@0+ (1,0) [0|7] ""  CUSTOMER_ECU

BO_ 41 DBW_HEALTH_RPT_01: 3 PACMOD
 SG_ COUNTER : 7|8@0+ (1,0) [0|255] ""  CUSTOMER_ECU
 SG_ CHECKSUM : 15|8@0+ (1,0) [0|255] ""  CUSTOMER_ECU
 SG_ BACKUP_CAN_NTWRK_INTEGRITY_FAULT : 17|2@0+ (1,0) [0|4] ""  CUSTOMER_ECU
 SG_ DBW_WARNING_LEVEL : 20|3@0+ (1,0) [0|3] ""  CUSTOMER_ECU
 SG_ SELF_TEST_STATUS : 23|3@0+ (1,0) [0|7] ""  CUSTOMER_ECU

BO_ 1041 DETECTED_OBJECT_RPT: 6 PACMOD
 SG_ FRONT_OBJECT_DISTANCE_LOW_RES : 7|24@0+ (0.001,0) [0|16777.215] "m"  CUSTOMER_ECU
 SG_ FRONT_OBJECT_DISTANCE_HIGH_RES : 31|24@0+ (0.001,0) [0|16777.215] "m"  CUSTOMER_ECU

BO_ 372 DIFFERENTIAL_LOCKS_CMD: 2 CUSTOMER_ECU
 SG_ ENABLE : 0|1@0+ (1,0) [0|1] ""  PACMOD
 SG_ IGNORE_OVERRIDES : 1|1@0+ (1,0) [0|1] ""  PACMOD
 SG_ CLEAR_OVERRIDE : 2|1@0+ (1,0) [0|1] ""  PACMOD
 SG_ FRONT_LOCK_CMD : 9|2@0+ (1,0) [0|3] ""  PACMOD
 SG_ CENTER_LOCK_CMD : 11|2@0+ (1,0) [0|3] ""  PACMOD
 SG_ REAR_LOCK_CMD : 13|2@0+ (1,0) [0|3] ""  PACMOD

BO_ 628 DIFFERENTIAL_LOCKS_RPT: 4 PACMOD
 SG_ ENABLED : 0|1@0+ (1,0) [0|1] ""  CUSTOMER_ECU
 SG_ OVERRIDE_ACTIVE : 1|1@0+ (1,0) [0|1] ""  CUSTOMER_ECU
 SG_ COMMAND_OUTPUT_FAULT : 2|1@0+ (1,0) [0|1] ""  CUSTOMER_ECU
 SG_ INPUT_OUTPUT_FAULT : 3|1@0+ (1,0) [0|1] ""  CUSTOMER_ECU
 SG_ OUTPUT_REPORTED_FAULT : 4|1@0+ (1,0) [0|1] ""  CUSTOMER_ECU
 SG_ PACMOD_FAULT : 5|1@0+ (1,0) [0|1] ""  CUSTOMER_ECU
 SG_ VEHICLE_FAULT : 6|1@0+ (1,0) [0|1] ""  CUSTOMER_ECU
 SG_ COMMAND_TIMEOUT : 7|1@0+ (1,0) [0|1] ""  CUSTOMER_ECU
 SG_ MAN_FRONT_LOCK : 9|2@0+ (1,0) [0|3] ""  CUSTOMER_ECU
 SG_ MAN_CENTER_LOCK : 11|2@0+ (1,0) [0|3] ""  CUSTOMER_ECU
 SG_ MAN_REAR_LOCK : 13|2@0+ (1,0) [0|3] ""  CUSTOMER_ECU
 SG_ CMD_FRONT_LOCK : 17|2@0+ (1,0) [0|3] ""  CUSTOMER_ECU
 SG_ CMD_CENTER_LOCK : 19|2@0+ (1,0) [0|3] ""  CUSTOMER_ECU
 SG_ CMD_REAR_LOCK : 21|2@0+ (1,0) [0|3] ""  CUSTOMER_ECU
 SG_ OUT_FRONT_LOCK : 25|2@0+ (1,0) [0|3] ""  CUSTOMER_ECU
 SG_ OUT_CENTER_LOCK : 27|2@0+ (1,0) [0|3] ""  CUSTOMER_ECU
 SG_ OUT_REAR_LOCK : 29|2@0+ (1,0) [0|3] ""  CUSTOMER_ECU

BO_ 1047 DOOR_RPT: 2 PACMOD
 SG_ DRIVER_DOOR_OPEN : 0|1@0+ (1,0) [0|1] ""  CUSTOMER_ECU
 SG_ PASS_DOOR_OPEN : 1|1@0+ (1,0) [0|1] ""  CUSTOMER_ECU
 SG_ REAR_DRIVER_DOOR_OPEN : 2|1@0+ (1,0) [0|1] ""  CUSTOMER_ECU
 SG_ REAR_PASS_DOOR_OPEN : 3|1@0+ (1,0) [0|1] ""  CUSTOMER_ECU
 SG_ HOOD_OPEN : 4|1@0+ (1,0) [0|1] ""  CUSTOMER_ECU
 SG_ TRUNK_OPEN : 5|1@0+ (1,0) [0|1] ""  CUSTOMER_ECU
 SG_ FUEL_DOOR_OPEN : 6|1@0+ (1,0) [0|1] ""  CUSTOMER_ECU
 SG_ CARGO_DOOR_OPEN : 7|1@0+ (1,0) [0|1] ""  CUSTOMER_ECU
 SG_ DRIVER_DOOR_OPEN_AVAIL : 8|1@0+ (1,0) [0|1] ""  CUSTOMER_ECU
 SG_ PASS_DOOR_OPEN_AVAIL : 9|1@0+ (1,0) [0|1] ""  CUSTOMER_ECU
 SG_ REAR_DRIVER_DOOR_OPEN_AVAIL : 10|1@0+ (1,0) [0|1] ""  CUSTOMER_ECU
 SG_ REAR_PASS_DOOR_OPEN_AVAIL : 11|1@0+ (1,0) [0|1] ""  CUSTOMER_ECU
 SG_ HOOD_OPEN_AVAIL : 12|1@0+ (1,0) [0|1] ""  CUSTOMER_ECU
 SG_ TRUNK_OPEN_AVAIL : 13|1@0+ (1,0) [0|1] ""  CUSTOMER_ECU
 SG_ FUEL_DOOR_OPEN_AVAIL : 14|1@0+ (1,0) [0|1] ""  CUSTOMER_ECU
 SG_ CARGO_DOOR_OPEN_AVAIL : 15|1@0+ (1,0) [0|1] ""  CUSTOMER_ECU

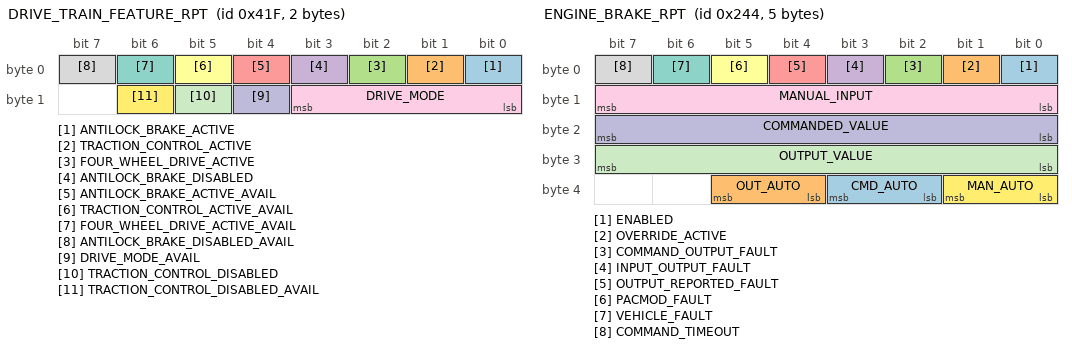
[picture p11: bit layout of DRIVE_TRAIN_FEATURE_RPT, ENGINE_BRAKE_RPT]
BO_ 1055 DRIVE_TRAIN_FEATURE_RPT: 2 PACMOD
 SG_ ANTILOCK_BRAKE_ACTIVE : 0|1@0+ (1,0) [0|1] ""  CUSTOMER_ECU
 SG_ TRACTION_CONTROL_ACTIVE : 1|1@0+ (1,0) [0|1] ""  CUSTOMER_ECU
 SG_ FOUR_WHEEL_DRIVE_ACTIVE : 2|1@0+ (1,0) [0|1] ""  CUSTOMER_ECU
 SG_ ANTILOCK_BRAKE_DISABLED : 3|1@0+ (1,0) [0|1] ""  CUSTOMER_ECU
 SG_ ANTILOCK_BRAKE_ACTIVE_AVAIL : 4|1@0+ (1,0) [0|1] ""  CUSTOMER_ECU
 SG_ TRACTION_CONTROL_ACTIVE_AVAIL : 5|1@0+ (1,0) [0|1] ""  CUSTOMER_ECU
 SG_ FOUR_WHEEL_DRIVE_ACTIVE_AVAIL : 6|1@0+ (1,0) [0|1] ""  CUSTOMER_ECU
 SG_ ANTILOCK_BRAKE_DISABLED_AVAIL : 7|1@0+ (1,0) [0|1] ""  CUSTOMER_ECU
 SG_ DRIVE_MODE : 11|4@0+ (1,0) [0|2] ""  CUSTOMER_ECU
 SG_ DRIVE_MODE_AVAIL : 12|1@0+ (1,0) [0|1] ""  CUSTOMER_ECU
 SG_ TRACTION_CONTROL_DISABLED : 13|1@0+ (1,0) [0|1] ""  CUSTOMER_ECU
 SG_ TRACTION_CONTROL_DISABLED_AVAIL : 14|1@0+ (1,0) [0|1] ""  CUSTOMER_ECU

BO_ 324 ENGINE_BRAKE_CMD: 3 CUSTOMER_ECU
 SG_ ENABLE : 0|1@0+ (1,0) [0|1] ""  PACMOD
 SG_ IGNORE_OVERRIDES : 1|1@0+ (1,0) [0|1] ""  PACMOD
 SG_ CLEAR_OVERRIDE : 2|1@0+ (1,0) [0|1] ""  PACMOD
 SG_ ENGINE_BRAKE_CMD : 15|8@0+ (1,0) [0|5] ""  PACMOD
 SG_ AUTO_CMD : 17|2@0+ (1,0) [0|1] ""  PACMOD

BO_ 836 ENGINE_BRAKE_AUX_RPT: 4  PACMOD
 SG_ ENGINE_BRAKE_STATUS : 1|2@0+ (1,0) [0|3] ""  CUSTOMER_ECU
 SG_ ACTUAL_ENGINE_BRK_TORQUE : 15|8@0+ (1,-125) [-125|125] "%"  CUSTOMER_ECU
 SG_ INTENDED_ENGINE_BRK_TORQUE : 23|8@0+ (1,-125) [-125|125] "%"  CUSTOMER_ECU
 SG_ ENGINE_BRAKE_STATUS_AVAIL : 24|1@0+ (1,0) [0|1] ""  CUSTOMER_ECU
 SG_ ACTUAL_ENGINE_BRK_TORQUE_AVAIL : 25|1@0+ (1,0) [0|1] ""  CUSTOMER_ECU
 SG_ INTENDED_ENGINE_BRK_TORQUE_AVAIL : 26|1@0+ (1,0) [0|1] ""  CUSTOMER_ECU

BO_ 580 ENGINE_BRAKE_RPT: 5 PACMOD
 SG_ ENABLED : 0|1@0+ (1,0) [0|1] ""  CUSTOMER_ECU
 SG_ OVERRIDE_ACTIVE : 1|1@0+ (1,0) [0|1] ""  CUSTOMER_ECU
 SG_ COMMAND_OUTPUT_FAULT : 2|1@0+ (1,0) [0|1] ""  CUSTOMER_ECU
 SG_ INPUT_OUTPUT_FAULT : 3|1@0+ (1,0) [0|1] ""  CUSTOMER_ECU
 SG_ OUTPUT_REPORTED_FAULT : 4|1@0+ (1,0) [0|1] ""  CUSTOMER_ECU
 SG_ PACMOD_FAULT : 5|1@0+ (1,0) [0|1] ""  CUSTOMER_ECU
 SG_ VEHICLE_FAULT : 6|1@0+ (1,0) [0|1] ""  CUSTOMER_ECU
 SG_ COMMAND_TIMEOUT : 7|1@0+ (1,0) [0|1] ""  CUSTOMER_ECU
 SG_ MANUAL_INPUT : 15|8@0+ (1,0) [0|255] ""  CUSTOMER_ECU
 SG_ COMMANDED_VALUE : 23|8@0+ (1,0) [0|255] ""  CUSTOMER_ECU
 SG_ OUTPUT_VALUE : 31|8@0+ (1,0) [0|255] ""  CUSTOMER_ECU
 SG_ MAN_AUTO : 33|2@0+ (1,0) [0|3] ""  CUSTOMER_ECU
 SG_ CMD_AUTO : 35|2@0+ (1,0) [0|3] ""  CUSTOMER_ECU
 SG_ OUT_AUTO : 37|2@0+ (1,0) [0|3] ""  CUSTOMER_ECU

BO_ 360 ENGINE_CMD: 2 CUSTOMER_ECU
 SG_ ENABLE : 0|1@0+ (1,0) [0|1] ""  PACMOD
 SG_ IGNORE_OVERRIDES : 1|1@0+ (1,0) [0|1] ""  PACMOD
 SG_ CLEAR_OVERRIDE : 2|1@0+ (1,0) [0|1] ""  PACMOD
 SG_ ENGINE_CMD : 15|8@0+ (1,0) [0|5] ""  PACMOD

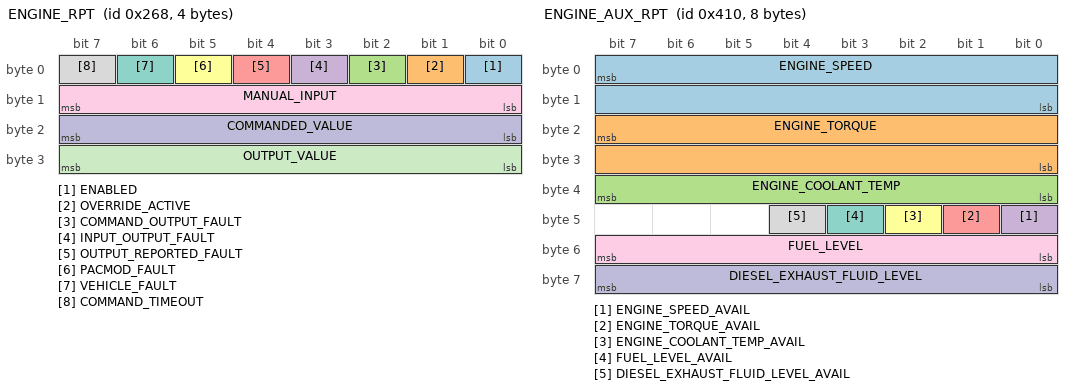
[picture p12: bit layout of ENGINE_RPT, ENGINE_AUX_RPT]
BO_ 616 ENGINE_RPT: 4 PACMOD
 SG_ ENABLED : 0|1@0+ (1,0) [0|1] ""  CUSTOMER_ECU
 SG_ OVERRIDE_ACTIVE : 1|1@0+ (1,0) [0|1] ""  CUSTOMER_ECU
 SG_ COMMAND_OUTPUT_FAULT : 2|1@0+ (1,0) [0|1] ""  CUSTOMER_ECU
 SG_ INPUT_OUTPUT_FAULT : 3|1@0+ (1,0) [0|1] ""  CUSTOMER_ECU
 SG_ OUTPUT_REPORTED_FAULT : 4|1@0+ (1,0) [0|1] ""  CUSTOMER_ECU
 SG_ PACMOD_FAULT : 5|1@0+ (1,0) [0|1] ""  CUSTOMER_ECU
 SG_ VEHICLE_FAULT : 6|1@0+ (1,0) [0|1] ""  CUSTOMER_ECU
 SG_ COMMAND_TIMEOUT : 7|1@0+ (1,0) [0|1] ""  CUSTOMER_ECU
 SG_ MANUAL_INPUT : 15|8@0+ (1,0) [0|255] ""  CUSTOMER_ECU
 SG_ COMMANDED_VALUE : 23|8@0+ (1,0) [0|255] ""  CUSTOMER_ECU
 SG_ OUTPUT_VALUE : 31|8@0+ (1,0) [0|255] ""  CUSTOMER_ECU

BO_ 1040 ENGINE_AUX_RPT: 8 PACMOD
 SG_ ENGINE_SPEED : 7|16@0+ (0.25,0) [0|16382.5] "rpm" CUSTOMER_ECU
 SG_ ENGINE_TORQUE : 23|16@0+ (0.0625,0) [0|4095.625] "N-m" CUSTOMER_ECU
 SG_ ENGINE_COOLANT_TEMP : 39|8@0+ (1,-40) [-40|210] "deg_C" CUSTOMER_ECU
 SG_ ENGINE_SPEED_AVAIL : 40|1@0+ (1,0) [0|1] "" CUSTOMER_ECU
 SG_ ENGINE_TORQUE_AVAIL : 41|1@0+ (1,0) [0|1] "" CUSTOMER_ECU
 SG_ ENGINE_COOLANT_TEMP_AVAIL : 42|1@0+ (1,0) [0|1] "" CUSTOMER_ECU
 SG_ FUEL_LEVEL_AVAIL : 43|1@0+ (1,0) [0|1] "" CUSTOMER_ECU
 SG_ DIESEL_EXHAUST_FLUID_LEVEL_AVAIL : 44|1@0+ (1,0) [0|1] "" CUSTOMER_ECU
 SG_ FUEL_LEVEL : 55|8@0+ (0.005,0) [0|1] "ratio" CUSTOMER_ECU
 SG_ DIESEL_EXHAUST_FLUID_LEVEL : 63|8@0+ (0.005,0) [0|1] "ratio" CUSTOMER_ECU

BO_ 1061 ENGINE_AUX_RPT_2: 5  PACMOD
 SG_ FUEL_RATE : 7|16@0+ (0.05,0) [0|3212.75] "L/h"  CUSTOMER_ECU
 SG_ FUEL_RATE_AVAIL : 16|1@0+ (1,0) [0|1] ""  CUSTOMER_ECU
 SG_ OIL_LEVEL_AVAIL : 17|1@0+ (1,0) [0|1] ""  CUSTOMER_ECU
 SG_ OIL_PRESSURE_AVAIL : 18|1@0+ (1,0) [0|1] ""  CUSTOMER_ECU
 SG_ OIL_LEVEL : 31|8@0+ (0.004,0) [0|1] "ratio"  CUSTOMER_ECU
 SG_ OIL_PRESSURE : 39|8@0+ (4,0) [0|1000] "kPa"  CUSTOMER_ECU

BO_ 1063 ENGINE_LOAD_FACTOR_RPT: 6 PACMOD
 SG_ DRVR_DEMANDED_ENG_TORQUE : 7|8@0+ (1,-125) [-125|125] "%"  CUSTOMER_ECU
 SG_ ACTUAL_ENGINE_TORQUE : 15|8@0+ (1,-125) [-125|125] "%"  CUSTOMER_ECU
 SG_ ENG_LOAD_AT_CURRENT_SPEED : 23|8@0+ (1,0) [0|250] "%"  CUSTOMER_ECU
 SG_ REFERENCE_ENGINE_TORQUE : 31|16@0+ (1,0) [0|64255] "Nm"  CUSTOMER_ECU
 SG_ DRVR_DEMANDED_ENG_TORQUE_AVAIL : 40|1@0+ (1,0) [0|1] ""  CUSTOMER_ECU
 SG_ ACTUAL_ENGINE_TORQUE_AVAIL : 41|1@0+ (1,0) [0|1] ""  CUSTOMER_ECU
 SG_ ENG_LOAD_AT_CURRENT_SPEED_AVAIL : 42|1@0+ (1,0) [0|1] ""  CUSTOMER_ECU
 SG_ REFERENCE_ENGINE_TORQUE_AVAIL : 43|1@0+ (1,0) [0|1] ""  CUSTOMER_ECU

BO_ 1052 ESTOP_RPT: 1 PACMOD
 SG_ ESTOP : 0|1@0+ (1,0) [0|1] ""  CUSTOMER_ECU
 SG_ ESTOP_FAULT : 1|1@0+ (1,0) [0|1] ""  CUSTOMER_ECU

BO_ 325 EXHAUST_BRAKE_CMD: 2 CUSTOMER_ECU
 SG_ ENABLE : 0|1@0+ (1,0) [0|1] ""  PACMOD
 SG_ IGNORE_OVERRIDES : 1|1@0+ (1,0) [0|1] ""  PACMOD
 SG_ CLEAR_OVERRIDE : 2|1@0+ (1,0) [0|1] ""  PACMOD
 SG_ EXHAUST_BRAKE_CMD : 15|8@0+ (1,0) [0|3] ""  PACMOD

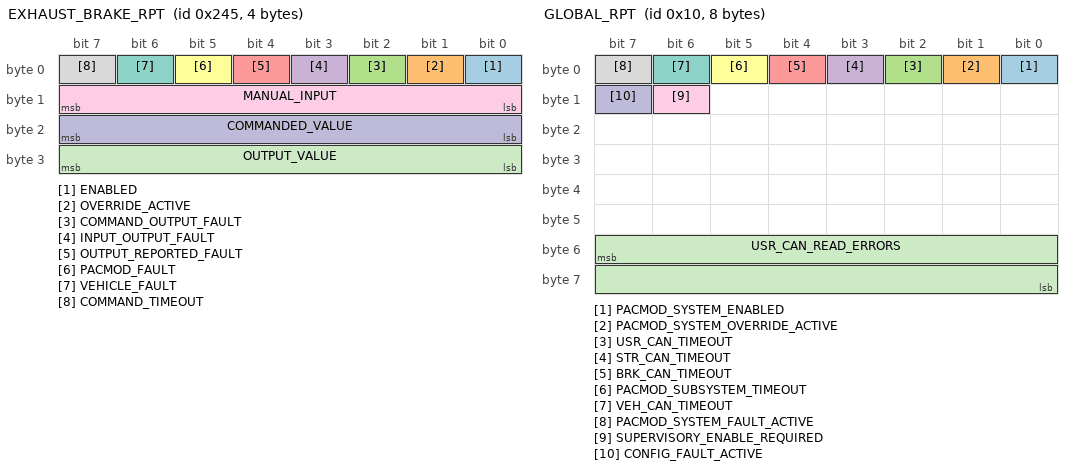
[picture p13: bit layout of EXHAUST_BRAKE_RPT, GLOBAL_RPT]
BO_ 581 EXHAUST_BRAKE_RPT: 4 PACMOD
 SG_ ENABLED : 0|1@0+ (1,0) [0|1] ""  CUSTOMER_ECU
 SG_ OVERRIDE_ACTIVE : 1|1@0+ (1,0) [0|1] ""  CUSTOMER_ECU
 SG_ COMMAND_OUTPUT_FAULT : 2|1@0+ (1,0) [0|1] ""  CUSTOMER_ECU
 SG_ INPUT_OUTPUT_FAULT : 3|1@0+ (1,0) [0|1] ""  CUSTOMER_ECU
 SG_ OUTPUT_REPORTED_FAULT : 4|1@0+ (1,0) [0|1] ""  CUSTOMER_ECU
 SG_ PACMOD_FAULT : 5|1@0+ (1,0) [0|1] ""  CUSTOMER_ECU
 SG_ VEHICLE_FAULT : 6|1@0+ (1,0) [0|1] ""  CUSTOMER_ECU
 SG_ COMMAND_TIMEOUT : 7|1@0+ (1,0) [0|1] ""  CUSTOMER_ECU
 SG_ MANUAL_INPUT : 15|8@0+ (1,0) [0|255] ""  CUSTOMER_ECU
 SG_ COMMANDED_VALUE : 23|8@0+ (1,0) [0|255] ""  CUSTOMER_ECU
 SG_ OUTPUT_VALUE : 31|8@0+ (1,0) [0|255] ""  CUSTOMER_ECU

BO_ 1042 FIRE_SUPPRESSION_RPT: 1 PACMOD
 SG_ FIRE_SUPPRESSION_ALARM_STATUS : 3|4@0+ (1,0) [0|1] ""  CUSTOMER_ECU

BO_ 128 GLOBAL_CMD: 2 CUSTOMER_ECU
 SG_ CLEAR_FAULTS : 0|1@0+ (1,0) [0|1] ""  PACMOD
 SG_ SANITY_CHECK_REQUIRED : 1|1@0+ (1,0) [0|1] ""  PACMOD
 SG_ CLEAR_OVERRIDES : 2|1@0+ (1,0) [0|1] ""  PACMOD
 SG_ DEVELOPMENT_MODE_REQUEST : 3|1@0+ (1,0) [0|1] ""  PACMOD
 SG_ COUNTER : 11|4@0+ (1,0) [0|15] ""  PACMOD
 SG_ COMPLEMENT : 15|4@0+ (1,0) [0|15] ""  PACMOD

BO_ 16 GLOBAL_RPT: 8 PACMOD
 SG_ PACMOD_SYSTEM_ENABLED : 0|1@0+ (1,0) [0|1] ""  CUSTOMER_ECU
 SG_ PACMOD_SYSTEM_OVERRIDE_ACTIVE : 1|1@0+ (1,0) [0|1] ""  CUSTOMER_ECU
 SG_ USR_CAN_TIMEOUT : 2|1@0+ (1,0) [0|1] ""  CUSTOMER_ECU
 SG_ STR_CAN_TIMEOUT : 3|1@0+ (1,0) [0|1] ""  CUSTOMER_ECU
 SG_ BRK_CAN_TIMEOUT : 4|1@0+ (1,0) [0|1] ""  CUSTOMER_ECU
 SG_ PACMOD_SUBSYSTEM_TIMEOUT : 5|1@0+ (1,0) [0|1] ""  CUSTOMER_ECU
 SG_ VEH_CAN_TIMEOUT : 6|1@0+ (1,0) [0|1] ""  CUSTOMER_ECU
 SG_ PACMOD_SYSTEM_FAULT_ACTIVE : 7|1@0+ (1,0) [0|1] ""  CUSTOMER_ECU
 SG_ SUPERVISORY_ENABLE_REQUIRED : 14|1@0+ (1,0) [0|1] ""  CUSTOMER_ECU
 SG_ CONFIG_FAULT_ACTIVE : 15|1@0+ (1,0) [0|1] ""  CUSTOMER_ECU
 SG_ USR_CAN_READ_ERRORS : 55|16@0+ (1,0) [0|65535] ""  CUSTOMER_ECU

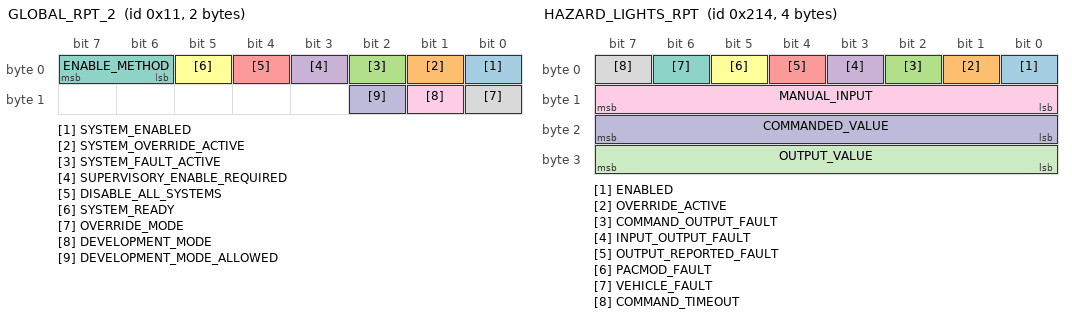
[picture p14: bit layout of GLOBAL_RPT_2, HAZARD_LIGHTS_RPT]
BO_ 17 GLOBAL_RPT_2: 2 PACMOD
 SG_ SYSTEM_ENABLED : 0|1@0+ (1,0) [0|1] ""  CUSTOMER_ECU
 SG_ SYSTEM_OVERRIDE_ACTIVE : 1|1@0+ (1,0) [0|1] ""  CUSTOMER_ECU
 SG_ SYSTEM_FAULT_ACTIVE : 2|1@0+ (1,0) [0|1] ""  CUSTOMER_ECU
 SG_ SUPERVISORY_ENABLE_REQUIRED : 3|1@0+ (1,0) [0|1] ""  CUSTOMER_ECU
 SG_ DISABLE_ALL_SYSTEMS  : 4|1@0+ (1,0) [0|1] ""  CUSTOMER_ECU
 SG_ SYSTEM_READY  : 5|1@0+ (1,0) [0|1] ""  CUSTOMER_ECU
 SG_ ENABLE_METHOD  : 7|2@0+ (1,0) [0|3] ""  CUSTOMER_ECU
 SG_ OVERRIDE_MODE  : 8|1@0+ (1,0) [0|1] ""  CUSTOMER_ECU
 SG_ DEVELOPMENT_MODE : 9|1@0+ (1,0) [0|1] ""  CUSTOMER_ECU
 SG_ DEVELOPMENT_MODE_ALLOWED : 10|1@0+ (1,0) [0|1] ""  CUSTOMER_ECU

BO_ 1082 GNSS_TIME: 6 CUSTOMER_ECU
 SG_ GNSS_TIMESTAMP : 7|48@0+ (1,0) [0|281474976710655] "ms"  PACMOD

BO_ 276 HAZARD_LIGHTS_CMD: 2 CUSTOMER_ECU
 SG_ ENABLE : 0|1@0+ (1,0) [0|1] ""  PACMOD
 SG_ IGNORE_OVERRIDES : 1|1@0+ (1,0) [0|1] ""  PACMOD
 SG_ CLEAR_OVERRIDE : 2|1@0+ (1,0) [0|1] ""  PACMOD
 SG_ HAZARD_LIGHTS_CMD : 8|1@0+ (1,0) [0|1] ""  PACMOD

BO_ 532 HAZARD_LIGHTS_RPT: 4 PACMOD
 SG_ ENABLED : 0|1@0+ (1,0) [0|1] ""  CUSTOMER_ECU
 SG_ OVERRIDE_ACTIVE : 1|1@0+ (1,0) [0|1] ""  CUSTOMER_ECU
 SG_ COMMAND_OUTPUT_FAULT : 2|1@0+ (1,0) [0|1] ""  CUSTOMER_ECU
 SG_ INPUT_OUTPUT_FAULT : 3|1@0+ (1,0) [0|1] ""  CUSTOMER_ECU
 SG_ OUTPUT_REPORTED_FAULT : 4|1@0+ (1,0) [0|1] ""  CUSTOMER_ECU
 SG_ PACMOD_FAULT : 5|1@0+ (1,0) [0|1] ""  CUSTOMER_ECU
 SG_ VEHICLE_FAULT : 6|1@0+ (1,0) [0|1] ""  CUSTOMER_ECU
 SG_ COMMAND_TIMEOUT : 7|1@0+ (1,0) [0|1] ""  CUSTOMER_ECU
 SG_ MANUAL_INPUT : 15|8@0+ (1,0) [0|255] ""  CUSTOMER_ECU
 SG_ COMMANDED_VALUE : 23|8@0+ (1,0) [0|255] ""  CUSTOMER_ECU
 SG_ OUTPUT_VALUE : 31|8@0+ (1,0) [0|255] ""  CUSTOMER_ECU

BO_ 792 HEADLIGHT_AUX_RPT: 3 PACMOD
 SG_ HEADLIGHTS_ON : 0|1@0+ (1,0) [0|1] ""  CUSTOMER_ECU
 SG_ HEADLIGHTS_ON_BRIGHT : 1|1@0+ (1,0) [0|1] ""  CUSTOMER_ECU
 SG_ FOG_LIGHTS_ON : 2|1@0+ (1,0) [0|1] ""  CUSTOMER_ECU
 SG_ HEADLIGHTS_MODE : 15|8@0+ (1,0) [0|3] ""  CUSTOMER_ECU
 SG_ HEADLIGHTS_ON_AVAIL : 16|1@0+ (1,0) [0|1] ""  CUSTOMER_ECU
 SG_ HEADLIGHTS_ON_BRIGHT_AVAIL : 17|1@0+ (1,0) [0|1] ""  CUSTOMER_ECU
 SG_ FOG_LIGHTS_ON_AVAIL : 18|1@0+ (1,0) [0|1] ""  CUSTOMER_ECU
 SG_ HEADLIGHTS_MODE_AVAIL : 19|1@0+ (1,0) [0|1] ""  CUSTOMER_ECU

BO_ 280 HEADLIGHT_CMD: 2 CUSTOMER_ECU
 SG_ ENABLE : 0|1@0+ (1,0) [0|1] ""  PACMOD
 SG_ IGNORE_OVERRIDES : 1|1@0+ (1,0) [0|1] ""  PACMOD
 SG_ CLEAR_OVERRIDE : 2|1@0+ (1,0) [0|1] ""  PACMOD
 SG_ HEADLIGHT_CMD : 15|8@0+ (1,0) [0|2] ""  PACMOD

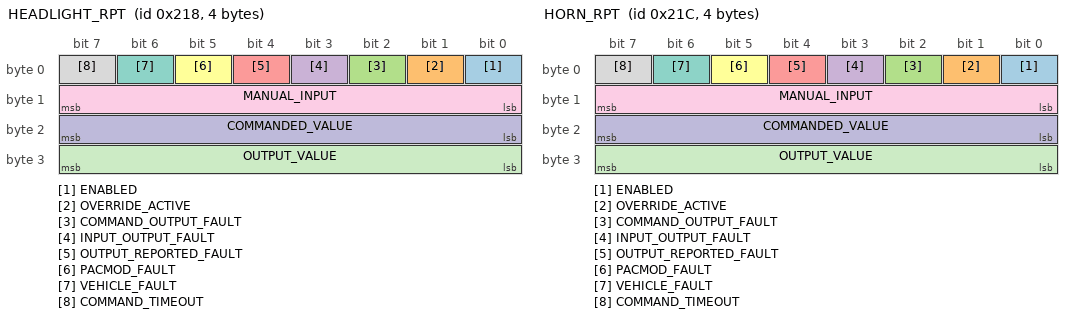
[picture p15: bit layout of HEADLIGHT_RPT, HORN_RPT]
BO_ 536 HEADLIGHT_RPT: 4 PACMOD
 SG_ ENABLED : 0|1@0+ (1,0) [0|1] ""  CUSTOMER_ECU
 SG_ OVERRIDE_ACTIVE : 1|1@0+ (1,0) [0|1] ""  CUSTOMER_ECU
 SG_ COMMAND_OUTPUT_FAULT : 2|1@0+ (1,0) [0|1] ""  CUSTOMER_ECU
 SG_ INPUT_OUTPUT_FAULT : 3|1@0+ (1,0) [0|1] ""  CUSTOMER_ECU
 SG_ OUTPUT_REPORTED_FAULT : 4|1@0+ (1,0) [0|1] ""  CUSTOMER_ECU
 SG_ PACMOD_FAULT : 5|1@0+ (1,0) [0|1] ""  CUSTOMER_ECU
 SG_ VEHICLE_FAULT : 6|1@0+ (1,0) [0|1] ""  CUSTOMER_ECU
 SG_ COMMAND_TIMEOUT : 7|1@0+ (1,0) [0|1] ""  CUSTOMER_ECU
 SG_ MANUAL_INPUT : 15|8@0+ (1,0) [0|255] ""  CUSTOMER_ECU
 SG_ COMMANDED_VALUE : 23|8@0+ (1,0) [0|255] ""  CUSTOMER_ECU
 SG_ OUTPUT_VALUE : 31|8@0+ (1,0) [0|255] ""  CUSTOMER_ECU

BO_ 284 HORN_CMD: 2 CUSTOMER_ECU
 SG_ ENABLE : 0|1@0+ (1,0) [0|1] ""  PACMOD
 SG_ IGNORE_OVERRIDES : 1|1@0+ (1,0) [0|1] ""  PACMOD
 SG_ CLEAR_OVERRIDE : 2|1@0+ (1,0) [0|1] ""  PACMOD
 SG_ HORN_CMD : 8|1@0+ (1,0) [0|1] ""  PACMOD

BO_ 540 HORN_RPT: 4 PACMOD
 SG_ ENABLED : 0|1@0+ (1,0) [0|1] ""  CUSTOMER_ECU
 SG_ OVERRIDE_ACTIVE : 1|1@0+ (1,0) [0|1] ""  CUSTOMER_ECU
 SG_ COMMAND_OUTPUT_FAULT : 2|1@0+ (1,0) [0|1] ""  CUSTOMER_ECU
 SG_ INPUT_OUTPUT_FAULT : 3|1@0+ (1,0) [0|1] ""  CUSTOMER_ECU
 SG_ OUTPUT_REPORTED_FAULT : 4|1@0+ (1,0) [0|1] ""  CUSTOMER_ECU
 SG_ PACMOD_FAULT : 5|1@0+ (1,0) [0|1] ""  CUSTOMER_ECU
 SG_ VEHICLE_FAULT : 6|1@0+ (1,0) [0|1] ""  CUSTOMER_ECU
 SG_ COMMAND_TIMEOUT : 7|1@0+ (1,0) [0|1] ""  CUSTOMER_ECU
 SG_ MANUAL_INPUT : 15|8@0+ (1,0) [0|255] ""  CUSTOMER_ECU
 SG_ COMMANDED_VALUE : 23|8@0+ (1,0) [0|255] ""  CUSTOMER_ECU
 SG_ OUTPUT_VALUE : 31|8@0+ (1,0) [0|255] ""  CUSTOMER_ECU

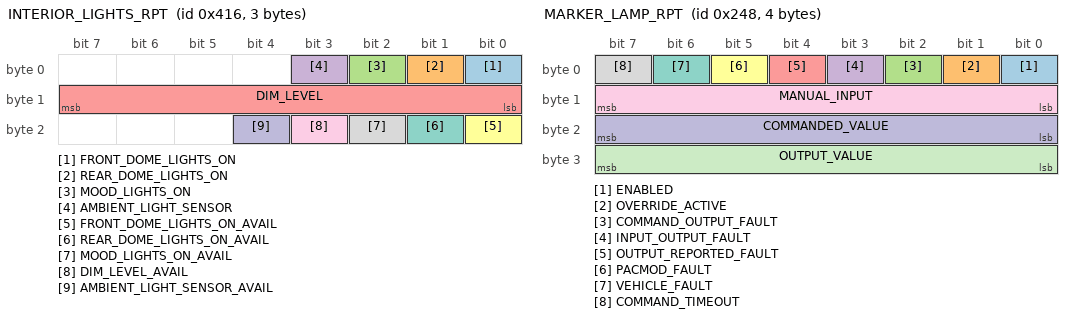
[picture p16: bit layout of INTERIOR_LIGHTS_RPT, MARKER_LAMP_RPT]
BO_ 1046 INTERIOR_LIGHTS_RPT: 3 PACMOD
 SG_ FRONT_DOME_LIGHTS_ON : 0|1@0+ (1,0) [0|1] ""  CUSTOMER_ECU
 SG_ REAR_DOME_LIGHTS_ON : 1|1@0+ (1,0) [0|1] ""  CUSTOMER_ECU
 SG_ MOOD_LIGHTS_ON : 2|1@0+ (1,0) [0|1] ""  CUSTOMER_ECU
 SG_ AMBIENT_LIGHT_SENSOR : 3|1@0+ (1,0) [0|1] ""  CUSTOMER_ECU
 SG_ DIM_LEVEL : 15|8@0+ (1,0) [0|24] ""  CUSTOMER_ECU
 SG_ FRONT_DOME_LIGHTS_ON_AVAIL : 16|1@0+ (1,0) [0|1] ""  CUSTOMER_ECU
 SG_ REAR_DOME_LIGHTS_ON_AVAIL : 17|1@0+ (1,0) [0|1] ""  CUSTOMER_ECU
 SG_ MOOD_LIGHTS_ON_AVAIL : 18|1@0+ (1,0) [0|1] ""  CUSTOMER_ECU
 SG_ DIM_LEVEL_AVAIL : 19|1@0+ (1,0) [0|1] ""  CUSTOMER_ECU
 SG_ AMBIENT_LIGHT_SENSOR_AVAIL : 20|1@0+ (1,0) [0|1] ""  CUSTOMER_ECU

BO_ 1038 LAT_LON_HEADING_RPT: 8 PACMOD
 SG_ LATITUDE_DEGREES : 7|8@0- (1,0) [-128|127] "deg"  CUSTOMER_ECU
 SG_ LATITUDE_MINUTES : 15|8@0- (1,0) [-128|127] "min"  CUSTOMER_ECU
 SG_ LATITUDE_SECONDS : 23|8@0- (1,0) [-128|127] "sec"  CUSTOMER_ECU
 SG_ LONGITUDE_DEGREES : 31|8@0- (1,0) [-128|127] "deg"  CUSTOMER_ECU
 SG_ LONGITUDE_MINUTES : 39|8@0- (1,0) [-128|127] "min"  CUSTOMER_ECU
 SG_ LONGITUDE_SECONDS : 47|8@0- (1,0) [-128|127] "sec"  CUSTOMER_ECU
 SG_ HEADING : 55|16@0- (0.01,0) [-327.68|327.67] "deg"  CUSTOMER_ECU

BO_ 1049 LINEAR_ACCEL_RPT: 7 PACMOD
 SG_ LATERAL_NEW_DATA_RX : 0|1@0+ (1,0) [0|1] ""  CUSTOMER_ECU
 SG_ LONGITUDINAL_NEW_DATA_RX : 1|1@0+ (1,0) [0|1] ""  CUSTOMER_ECU
 SG_ VERTICAL_NEW_DATA_RX : 2|1@0+ (1,0) [0|1] ""  CUSTOMER_ECU
 SG_ LATERAL_VALID : 3|1@0+ (1,0) [0|1] ""  CUSTOMER_ECU
 SG_ LONGITUDINAL_VALID : 4|1@0+ (1,0) [0|1] ""  CUSTOMER_ECU
 SG_ VERTICAL_VALID : 5|1@0+ (1,0) [0|1] ""  CUSTOMER_ECU
 SG_ LATERAL_ACCEL : 15|16@0- (0.01,0) [-327.68|327.67] "m/s^2"  CUSTOMER_ECU
 SG_ LONGITUDINAL_ACCEL : 31|16@0- (0.01,0) [-327.68|327.67] "m/s^2"  CUSTOMER_ECU
 SG_ VERTICAL_ACCEL : 47|16@0- (0.01,0) [-327.68|327.67] "m/s^2"  CUSTOMER_ECU

BO_ 328 MARKER_LAMP_CMD: 2 CUSTOMER_ECU
 SG_ ENABLE : 0|1@0+ (1,0) [0|1] ""  PACMOD
 SG_ IGNORE_OVERRIDES : 1|1@0+ (1,0) [0|1] ""  PACMOD
 SG_ CLEAR_OVERRIDE : 2|1@0+ (1,0) [0|1] ""  PACMOD
 SG_ MARKER_LAMP_CMD : 8|1@0+ (1,0) [0|1] ""  PACMOD

BO_ 584 MARKER_LAMP_RPT: 4 PACMOD
 SG_ ENABLED : 0|1@0+ (1,0) [0|1] ""  CUSTOMER_ECU
 SG_ OVERRIDE_ACTIVE : 1|1@0+ (1,0) [0|1] ""  CUSTOMER_ECU
 SG_ COMMAND_OUTPUT_FAULT : 2|1@0+ (1,0) [0|1] ""  CUSTOMER_ECU
 SG_ INPUT_OUTPUT_FAULT : 3|1@0+ (1,0) [0|1] ""  CUSTOMER_ECU
 SG_ OUTPUT_REPORTED_FAULT : 4|1@0+ (1,0) [0|1] ""  CUSTOMER_ECU
 SG_ PACMOD_FAULT : 5|1@0+ (1,0) [0|1] ""  CUSTOMER_ECU
 SG_ VEHICLE_FAULT : 6|1@0+ (1,0) [0|1] ""  CUSTOMER_ECU
 SG_ COMMAND_TIMEOUT : 7|1@0+ (1,0) [0|1] ""  CUSTOMER_ECU
 SG_ MANUAL_INPUT : 15|8@0+ (1,0) [0|255] ""  CUSTOMER_ECU
 SG_ COMMANDED_VALUE : 23|8@0+ (1,0) [0|255] ""  CUSTOMER_ECU
 SG_ OUTPUT_VALUE : 31|8@0+ (1,0) [0|255] ""  CUSTOMER_ECU

BO_ 288 MEDIA_CONTROLS_CMD: 2 CUSTOMER_ECU
 SG_ ENABLE : 0|1@0+ (1,0) [0|1] ""  PACMOD
 SG_ IGNORE_OVERRIDES : 1|1@0+ (1,0) [0|1] ""  PACMOD
 SG_ CLEAR_OVERRIDE : 2|1@0+ (1,0) [0|1] ""  PACMOD
 SG_ MEDIA_CONTROLS_CMD : 15|8@0+ (1,0) [0|255] ""  PACMOD

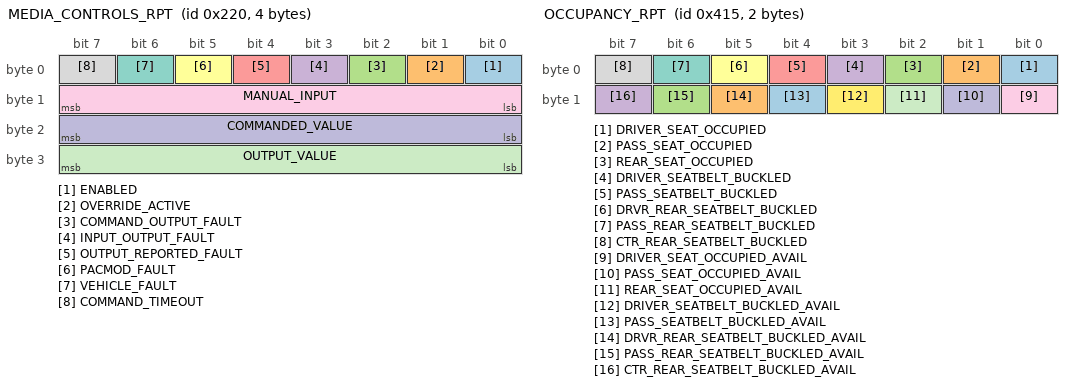
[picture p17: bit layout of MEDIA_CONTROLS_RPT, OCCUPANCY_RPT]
BO_ 544 MEDIA_CONTROLS_RPT: 4 PACMOD
 SG_ ENABLED : 0|1@0+ (1,0) [0|1] ""  CUSTOMER_ECU
 SG_ OVERRIDE_ACTIVE : 1|1@0+ (1,0) [0|1] ""  CUSTOMER_ECU
 SG_ COMMAND_OUTPUT_FAULT : 2|1@0+ (1,0) [0|1] ""  CUSTOMER_ECU
 SG_ INPUT_OUTPUT_FAULT : 3|1@0+ (1,0) [0|1] ""  CUSTOMER_ECU
 SG_ OUTPUT_REPORTED_FAULT : 4|1@0+ (1,0) [0|1] ""  CUSTOMER_ECU
 SG_ PACMOD_FAULT : 5|1@0+ (1,0) [0|1] ""  CUSTOMER_ECU
 SG_ VEHICLE_FAULT : 6|1@0+ (1,0) [0|1] ""  CUSTOMER_ECU
 SG_ COMMAND_TIMEOUT : 7|1@0+ (1,0) [0|1] ""  CUSTOMER_ECU
 SG_ MANUAL_INPUT : 15|8@0+ (1,0) [0|255] ""  CUSTOMER_ECU
 SG_ COMMANDED_VALUE : 23|8@0+ (1,0) [0|255] ""  CUSTOMER_ECU
 SG_ OUTPUT_VALUE : 31|8@0+ (1,0) [0|255] ""  CUSTOMER_ECU

BO_ 1051 NOTIFICATION_CMD: 1 CUSTOMER_ECU
 SG_ BUZZER_MUTE : 0|1@0+ (1,0) [0|1] ""  PACMOD
 SG_ UNDERDASH_LIGHTS_WHITE : 1|1@0+ (1,0) [0|1] ""  PACMOD

BO_ 1059 NOTIFICATION_RPT: 1 PACMOD
 SG_ BUZZER_STATUS : 1|2@0+ (1,0) [0|2] ""  CUSTOMER_ECU
 SG_ LIGHT_STATUS : 3|2@0+ (1,0) [0|2] ""  CUSTOMER_ECU
 SG_ LIGHT_COLOR : 7|4@0+ (1,0) [1|10] ""  CUSTOMER_ECU

BO_ 1045 OCCUPANCY_RPT: 2 PACMOD
 SG_ DRIVER_SEAT_OCCUPIED : 0|1@0+ (1,0) [0|1] ""  CUSTOMER_ECU
 SG_ PASS_SEAT_OCCUPIED : 1|1@0+ (1,0) [0|1] ""  CUSTOMER_ECU
 SG_ REAR_SEAT_OCCUPIED : 2|1@0+ (1,0) [0|1] ""  CUSTOMER_ECU
 SG_ DRIVER_SEATBELT_BUCKLED : 3|1@0+ (1,0) [0|1] ""  CUSTOMER_ECU
 SG_ PASS_SEATBELT_BUCKLED : 4|1@0+ (1,0) [0|1] ""  CUSTOMER_ECU
 SG_ DRVR_REAR_SEATBELT_BUCKLED : 5|1@0+ (1,0) [0|1] ""  CUSTOMER_ECU
 SG_ PASS_REAR_SEATBELT_BUCKLED : 6|1@0+ (1,0) [0|1] ""  CUSTOMER_ECU
 SG_ CTR_REAR_SEATBELT_BUCKLED : 7|1@0+ (1,0) [0|1] ""  CUSTOMER_ECU
 SG_ DRIVER_SEAT_OCCUPIED_AVAIL : 8|1@0+ (1,0) [0|1] ""  CUSTOMER_ECU
 SG_ PASS_SEAT_OCCUPIED_AVAIL : 9|1@0+ (1,0) [0|1] ""  CUSTOMER_ECU
 SG_ REAR_SEAT_OCCUPIED_AVAIL : 10|1@0+ (1,0) [0|1] ""  CUSTOMER_ECU
 SG_ DRIVER_SEATBELT_BUCKLED_AVAIL : 11|1@0+ (1,0) [0|1] ""  CUSTOMER_ECU
 SG_ PASS_SEATBELT_BUCKLED_AVAIL : 12|1@0+ (1,0) [0|1] ""  CUSTOMER_ECU
 SG_ DRVR_REAR_SEATBELT_BUCKLED_AVAIL : 13|1@0+ (1,0) [0|1] ""  CUSTOMER_ECU
 SG_ PASS_REAR_SEATBELT_BUCKLED_AVAIL : 14|1@0+ (1,0) [0|1] ""  CUSTOMER_ECU
 SG_ CTR_REAR_SEATBELT_BUCKLED_AVAIL : 15|1@0+ (1,0) [0|1] ""  CUSTOMER_ECU

BO_ 804 PARKING_BRAKE_AUX_RPT: 2 PACMOD
 SG_ PARKING_BRAKE_STATUS : 1|2@0+ (1,0) [0|2] ""  CUSTOMER_ECU
 SG_ PARKING_BRAKE_STATUS_AVAIL : 8|1@0+ (1,0) [0|1] ""  CUSTOMER_ECU

BO_ 292 PARKING_BRAKE_CMD: 2 CUSTOMER_ECU
 SG_ ENABLE : 0|1@0+ (1,0) [0|1] ""  PACMOD
 SG_ IGNORE_OVERRIDES : 1|1@0+ (1,0) [0|1] ""  PACMOD
 SG_ CLEAR_OVERRIDE : 2|1@0+ (1,0) [0|1] ""  PACMOD
 SG_ PARKING_BRAKE_CMD : 8|1@0+ (1,0) [0|1] ""  PACMOD

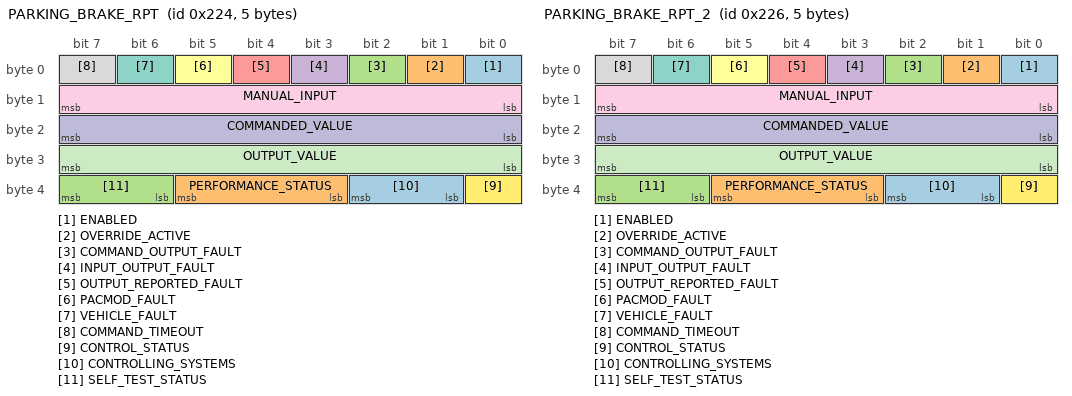
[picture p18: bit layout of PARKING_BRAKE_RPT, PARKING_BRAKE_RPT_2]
BO_ 548 PARKING_BRAKE_RPT: 5 PACMOD
 SG_ ENABLED : 0|1@0+ (1,0) [0|1] ""  CUSTOMER_ECU
 SG_ OVERRIDE_ACTIVE : 1|1@0+ (1,0) [0|1] ""  CUSTOMER_ECU
 SG_ COMMAND_OUTPUT_FAULT : 2|1@0+ (1,0) [0|1] ""  CUSTOMER_ECU
 SG_ INPUT_OUTPUT_FAULT : 3|1@0+ (1,0) [0|1] ""  CUSTOMER_ECU
 SG_ OUTPUT_REPORTED_FAULT : 4|1@0+ (1,0) [0|1] ""  CUSTOMER_ECU
 SG_ PACMOD_FAULT : 5|1@0+ (1,0) [0|1] ""  CUSTOMER_ECU
 SG_ VEHICLE_FAULT : 6|1@0+ (1,0) [0|1] ""  CUSTOMER_ECU
 SG_ COMMAND_TIMEOUT : 7|1@0+ (1,0) [0|1] ""  CUSTOMER_ECU
 SG_ MANUAL_INPUT : 15|8@0+ (1,0) [0|255] ""  CUSTOMER_ECU
 SG_ COMMANDED_VALUE : 23|8@0+ (1,0) [0|255] ""  CUSTOMER_ECU
 SG_ OUTPUT_VALUE : 31|8@0+ (1,0) [0|255] ""  CUSTOMER_ECU
 SG_ CONTROL_STATUS : 32|1@0+ (1,0) [0|1] ""  CUSTOMER_ECU
 SG_ CONTROLLING_SYSTEMS : 34|2@0+ (1,0) [0|3] ""  CUSTOMER_ECU
 SG_ PERFORMANCE_STATUS : 37|3@0+ (1,0) [0|4] ""  CUSTOMER_ECU
 SG_ SELF_TEST_STATUS : 39|2@0+ (1,0) [0|3] ""  CUSTOMER_ECU

BO_ 550 PARKING_BRAKE_RPT_2: 5 PACMOD
 SG_ ENABLED : 0|1@0+ (1,0) [0|1] ""  CUSTOMER_ECU
 SG_ OVERRIDE_ACTIVE : 1|1@0+ (1,0) [0|1] ""  CUSTOMER_ECU
 SG_ COMMAND_OUTPUT_FAULT : 2|1@0+ (1,0) [0|1] ""  CUSTOMER_ECU
 SG_ INPUT_OUTPUT_FAULT : 3|1@0+ (1,0) [0|1] ""  CUSTOMER_ECU
 SG_ OUTPUT_REPORTED_FAULT : 4|1@0+ (1,0) [0|1] ""  CUSTOMER_ECU
 SG_ PACMOD_FAULT : 5|1@0+ (1,0) [0|1] ""  CUSTOMER_ECU
 SG_ VEHICLE_FAULT : 6|1@0+ (1,0) [0|1] ""  CUSTOMER_ECU
 SG_ COMMAND_TIMEOUT : 7|1@0+ (1,0) [0|1] ""  CUSTOMER_ECU
 SG_ MANUAL_INPUT : 15|8@0+ (1,0) [0|255] ""  CUSTOMER_ECU
 SG_ COMMANDED_VALUE : 23|8@0+ (1,0) [0|255] ""  CUSTOMER_ECU
 SG_ OUTPUT_VALUE : 31|8@0+ (1,0) [0|255] ""  CUSTOMER_ECU
 SG_ CONTROL_STATUS : 32|1@0+ (1,0) [0|1] ""  CUSTOMER_ECU
 SG_ CONTROLLING_SYSTEMS : 34|2@0+ (1,0) [0|3] ""  CUSTOMER_ECU
 SG_ PERFORMANCE_STATUS : 37|3@0+ (1,0) [0|4] ""  CUSTOMER_ECU
 SG_ SELF_TEST_STATUS : 39|2@0+ (1,0) [0|3] ""  CUSTOMER_ECU

BO_ 348 POWER_TAKE_OFF_CMD: 2 CUSTOMER_ECU
 SG_ ENABLE : 0|1@0+ (1,0) [0|1] ""  PACMOD
 SG_ IGNORE_OVERRIDES : 1|1@0+ (1,0) [0|1] ""  PACMOD
 SG_ CLEAR_OVERRIDE : 2|1@0+ (1,0) [0|1] ""  PACMOD
 SG_ POWER_TAKE_OFF_CMD : 15|8@0+ (1,0) [0|1] ""  PACMOD

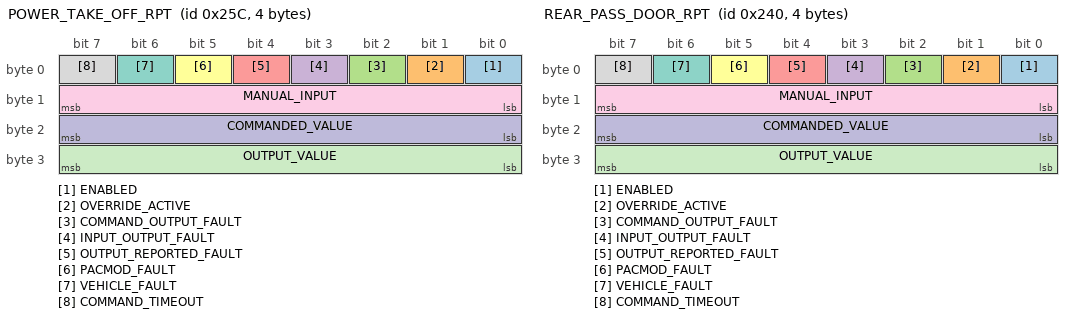
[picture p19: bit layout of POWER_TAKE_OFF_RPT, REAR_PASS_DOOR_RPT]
BO_ 604 POWER_TAKE_OFF_RPT: 4 PACMOD
 SG_ ENABLED : 0|1@0+ (1,0) [0|1] ""  CUSTOMER_ECU
 SG_ OVERRIDE_ACTIVE : 1|1@0+ (1,0) [0|1] ""  CUSTOMER_ECU
 SG_ COMMAND_OUTPUT_FAULT : 2|1@0+ (1,0) [0|1] ""  CUSTOMER_ECU
 SG_ INPUT_OUTPUT_FAULT : 3|1@0+ (1,0) [0|1] ""  CUSTOMER_ECU
 SG_ OUTPUT_REPORTED_FAULT : 4|1@0+ (1,0) [0|1] ""  CUSTOMER_ECU
 SG_ PACMOD_FAULT : 5|1@0+ (1,0) [0|1] ""  CUSTOMER_ECU
 SG_ VEHICLE_FAULT : 6|1@0+ (1,0) [0|1] ""  CUSTOMER_ECU
 SG_ COMMAND_TIMEOUT : 7|1@0+ (1,0) [0|1] ""  CUSTOMER_ECU
 SG_ MANUAL_INPUT : 15|8@0+ (1,0) [0|255] ""  CUSTOMER_ECU
 SG_ COMMANDED_VALUE : 23|8@0+ (1,0) [0|255] ""  CUSTOMER_ECU
 SG_ OUTPUT_VALUE : 31|8@0+ (1,0) [0|255] ""  CUSTOMER_ECU

BO_ 1048 REAR_LIGHTS_RPT: 2 PACMOD
 SG_ BRAKE_LIGHTS_ON : 0|1@0+ (1,0) [0|1] ""  CUSTOMER_ECU
 SG_ REVERSE_LIGHTS_ON : 1|1@0+ (1,0) [0|1] ""  CUSTOMER_ECU
 SG_ BRAKE_LIGHTS_ON_AVAIL : 8|1@0+ (1,0) [0|1] ""  CUSTOMER_ECU
 SG_ REVERSE_LIGHTS_ON_AVAIL : 9|1@0+ (1,0) [0|1] ""  CUSTOMER_ECU

BO_ 320 REAR_PASS_DOOR_CMD: 2 CUSTOMER_ECU
 SG_ ENABLE : 0|1@0+ (1,0) [0|1] ""  PACMOD
 SG_ IGNORE_OVERRIDES : 1|1@0+ (1,0) [0|1] ""  PACMOD
 SG_ CLEAR_OVERRIDE : 2|1@0+ (1,0) [0|1] ""  PACMOD
 SG_ REAR_PASS_DOOR_CMD : 15|8@0+ (1,0) [0|2] ""  PACMOD

BO_ 576 REAR_PASS_DOOR_RPT: 4 PACMOD
 SG_ ENABLED : 0|1@0+ (1,0) [0|1] ""  CUSTOMER_ECU
 SG_ OVERRIDE_ACTIVE : 1|1@0+ (1,0) [0|1] ""  CUSTOMER_ECU
 SG_ COMMAND_OUTPUT_FAULT : 2|1@0+ (1,0) [0|1] ""  CUSTOMER_ECU
 SG_ INPUT_OUTPUT_FAULT : 3|1@0+ (1,0) [0|1] ""  CUSTOMER_ECU
 SG_ OUTPUT_REPORTED_FAULT : 4|1@0+ (1,0) [0|1] ""  CUSTOMER_ECU
 SG_ PACMOD_FAULT : 5|1@0+ (1,0) [0|1] ""  CUSTOMER_ECU
 SG_ VEHICLE_FAULT : 6|1@0+ (1,0) [0|1] ""  CUSTOMER_ECU
 SG_ COMMAND_TIMEOUT : 7|1@0+ (1,0) [0|1] ""  CUSTOMER_ECU
 SG_ MANUAL_INPUT : 15|8@0+ (1,0) [0|255] ""  CUSTOMER_ECU
 SG_ COMMANDED_VALUE : 23|8@0+ (1,0) [0|255] ""  CUSTOMER_ECU
 SG_ OUTPUT_VALUE : 31|8@0+ (1,0) [0|255] ""  CUSTOMER_ECU

BO_ 1076 REMOTE_STOP_RPT: 4 PACMOD
 SG_ REMOTE_STOP_COMMAND : 7|8@0+ (1,0) [0|2] ""  CUSTOMER_ECU
 SG_ REMOTE_STOP_SENDER_ID : 15|16@0+ (1,0) [0|65535] ""  CUSTOMER_ECU
 SG_ REMOTE_STOP_TIMEOUT : 24|1@0+ (1,0) [0|1] ""  CUSTOMER_ECU
 SG_ REMOTE_STOP_FAULT : 25|1@0+ (1,0) [0|1] ""  CUSTOMER_ECU
 SG_ REMOTE_STOP_MODE_CHANGE_ALLOWED : 26|1@0+ (1,0) [0|1] ""  CUSTOMER_ECU

BO_ 193 SAFETY_BRAKE_CMD: 1 CUSTOMER_ECU
 SG_ SAFETY_BRAKE_CMD : 0|1@0+ (1,0) [0|1] ""  PACMOD

BO_ 65 SAFETY_BRAKE_RPT: 1 PACMOD
 SG_ COMMANDED_VALUE : 0|1@0+ (1,0) [0|1] ""  CUSTOMER_ECU
 SG_ OUTPUT_VALUE : 2|2@0+ (1,0) [0|3] ""  CUSTOMER_ECU
 SG_ COMMAND_REPORTED_FAULT : 3|1@0+ (1,0) [0|1] ""  CUSTOMER_ECU
 SG_ COMMAND_TIMEOUT : 4|1@0+ (1,0) [0|1] ""  CUSTOMER_ECU
 SG_ COMMAND_PERMITTED : 5|1@0+ (1,0) [0|1] ""  CUSTOMER_ECU
 SG_ REPORTED_FAULT : 6|1@0+ (1,0) [0|1] ""  CUSTOMER_ECU

BO_ 192 SAFETY_FUNC_CMD: 1 CUSTOMER_ECU
 SG_ COMMAND : 3|4@0+ (1,0) [0|5] ""  PACMOD

BO_ 1056 SAFETY_FUNC_CRITICAL_STOP_RPT: 3  PACMOD
 SG_ AUTOMS_MAN_OPCTRL_FAULT : 0|1@0+ (1,0) [0|1] ""  CUSTOMER_ECU
 SG_ REMOTE_STOP_FAULT : 1|1@0+ (1,0) [0|1] ""  CUSTOMER_ECU
 SG_ SAFETY_BRAKE_OPCTRL_OFF : 2|1@0+ (1,0) [0|1] ""  CUSTOMER_ECU
 SG_ SAFETY_BRAKE_CMD_TIMEOUT : 3|1@0+ (1,0) [0|1] ""  CUSTOMER_ECU
 SG_ SAFETY_FUNC_CMD_TIMEOUT : 4|1@0+ (1,0) [0|1] ""  CUSTOMER_ECU
 SG_ SAFETY_FUNC_CRITICAL_STOP_1_CMD : 5|1@0+ (1,0) [0|1] ""  CUSTOMER_ECU
 SG_ SAFETY_FUNC_CRITICAL_STOP_2_CMD : 6|1@0+ (1,0) [0|1] ""  CUSTOMER_ECU
 SG_ SAFETY_FUNC_NONE_CMD : 7|1@0+ (1,0) [0|1] ""  CUSTOMER_ECU
 SG_ PACMOD_SYSTEM_TIMEOUT : 8|1@0+ (1,0) [0|1] ""  CUSTOMER_ECU
 SG_ PACMOD_SYSTEM_FAULT : 9|1@0+ (1,0) [0|1] ""  CUSTOMER_ECU
 SG_ PACMOD_SYSTEM_NOT_ACTIVE : 10|1@0+ (1,0) [0|1] ""  CUSTOMER_ECU
 SG_ VEHICLE_REPORT_TIMEOUT : 11|1@0+ (1,0) [0|1] ""  CUSTOMER_ECU
 SG_ VEHICLE_REPORT_FAULT : 12|1@0+ (1,0) [0|1] ""  CUSTOMER_ECU
 SG_ LOW_ENGINE_RPM : 13|1@0+ (1,0) [0|1] ""  CUSTOMER_ECU
 SG_ PRI_SAFETY_BRAKE_SIGNAL_1_FAULT : 14|1@0+ (1,0) [0|1] ""  CUSTOMER_ECU
 SG_ PRI_SAFETY_BRAKE_SIGNAL_2_FAULT : 15|1@0+ (1,0) [0|1] ""  CUSTOMER_ECU
 SG_ SEC_SAFETY_BRAKE_SIGNAL_1_FAULT : 16|1@0+ (1,0) [0|1] ""  CUSTOMER_ECU
 SG_ SEC_SAFETY_BRAKE_SIGNAL_2_FAULT : 17|1@0+ (1,0) [0|1] ""  CUSTOMER_ECU
 SG_ PRIMARY_PROCESSOR_FAULT : 18|1@0+ (1,0) [0|1] ""  CUSTOMER_ECU
 SG_ SECONDARY_PROCESSOR_FAULT : 19|1@0+ (1,0) [0|1] ""  CUSTOMER_ECU
 SG_ REMOTE_STOP_CMD : 20|1@0+ (1,0) [0|1] ""  CUSTOMER_ECU
 SG_ PRI_SAFETY_BRAKE_PRESSURE_FAULT : 21|1@0+ (1,0) [0|1] ""  CUSTOMER_ECU

///////////////////////////////////
//                               //
// Network Node Comment Section  //
//                               //
///////////////////////////////////
CM_ BU_ PACMOD "AutonomouStuff PACMod";

///////////////////////////////
//                           //
//  Message Comment Section  //
//                           //
///////////////////////////////
// GLOBAL_RPT MESSAGE COMMENT
CM_ BO_ 16 "Not for new development.";

//////////////////////////////
//                          //
//  Signal Comment Section  //
//                          //
//////////////////////////////
// ACCEL_AUX_RPT COMMENTS
CM_ SG_ 768 OPERATOR_INTERACTION "OPERATOR_INTERACTION shall have the value of 1 if the driver is moving, changing, or otherwise touching the operator control(s) that relates to this signal to an extent that is detectable. Otherwise, the value shall be 0.";
CM_ SG_ 768 ACCEL_LIMITING_ACTIVE "ACCEL_LIMITING_ACTIVE shall have the value of 1 if a limiting function is reducing an excessive command.  Otherwise, the value shall be 0.";
CM_ SG_ 768 PRK_BRK_INTERLOCK_ACTIVE "PARK_BRAKE_INTERLOCK_ACTIVE shall have the value of 1 if an active parking brake prevents or reduces the command. Otherwise, the value shall be 0.";
CM_ SG_ 768 BRAKE_INTERLOCK_ACTIVE "BRAKE_INTERLOCK_ACTIVE shall have the value of 1 if an active brake prevents or reduces the command. Otherwise, the value shall be 0.";
CM_ SG_ 768 CALIBRATION_STATUS "CALIBRATION_STATUS shall indicate the status of a calibration of this system. If this system has more than one calibration, then those calibrations are INACTIVE.";
CM_ SG_ 768 OPERATOR_INTERACTION_AVAIL "PACMod sets this value as a function of which vehicle platform is under test and, therefore, this value does not change during operation.";
CM_ SG_ 768 ACCEL_LIMITING_ACTIVE_AVAIL "PACMod sets this value as a function of which vehicle platform is under test and, therefore, this value does not change during operation.";
CM_ SG_ 768 PRK_BRK_INTERLOCK_ACTIVE_AVAIL "PACMod sets this value as a function of which vehicle platform is under test and, therefore, this value does not change during operation.";
CM_ SG_ 768 BRAKE_INTERLOCK_ACTIVE_AVAIL "PACMod sets this value as a function of which vehicle platform is under test and, therefore, this value does not change during operation.";

// ACCEL_CMD COMMENTS
CM_ SG_ 256 ACCEL_CMD "Ratio of full-scale value of signal from 0 to 1 (i.e. percent from 0 to 1).";

// ACCEL_CMD_LIMIT_RPT COMMENTS
CM_ SG_ 513 ACCEL_CMD_LIMIT "The ACCEL_CMD_LIMIT shall have the value of the limit imposed on the command associated with this system. Ratio of full-scale value of signal from 0 to 1 (i.e. percent from 0 to 1).";
CM_ SG_ 513 LIMITED_ACCEL_CMD "The LIMITED_ACCEL_CMD shall have the value of command associated with this system constrained by the ACCEL_CMD_LIMIT. Ratio of full-scale value of signal from 0 to 1 (i.e. percent from 0 to 1).";

// ACCEL_RPT COMMENTS
CM_ SG_ 512 MANUAL_INPUT "Ratio of full-scale value of signal from 0 to 1 (i.e. percent from 0 to 1).";
CM_ SG_ 512 COMMANDED_VALUE "Ratio of full-scale value of signal from 0 to 1 (i.e. percent from 0 to 1).";
CM_ SG_ 512 OUTPUT_VALUE "Ratio of full-scale value of signal from 0 to 1 (i.e. percent from 0 to 1).";
CM_ SG_ 512 CONTROLLING_SYSTEMS "Number of systems in control.";

// AIR_PRESSURE_RPT COMMENTS
CM_ SG_ 1060 PNEUMATIC_SUPPLY_PRESSURE_AVAIL "PACMod sets this value as a function of which vehicle platform is under test and, therefore, this value does not change during operation.";
CM_ SG_ 1060 BRAKE_CIRCUIT_1_PRESSURE_AVAIL "PACMod sets this value as a function of which vehicle platform is under test and, therefore, this value does not change during operation.";
CM_ SG_ 1060 BRAKE_CIRCUIT_2_PRESSURE_AVAIL "PACMod sets this value as a function of which vehicle platform is under test and, therefore, this value does not change during operation.";
CM_ SG_ 1060 PARK_TRAILER_AIR_PRESSURE_AVAIL "PACMod sets this value as a function of which vehicle platform is under test and, therefore, this value does not change during operation.";
CM_ SG_ 1060 POWERTRAIN_AIR_PRESSURE_AVAIL "PACMod sets this value as a function of which vehicle platform is under test and, therefore, this value does not change during operation.";
CM_ SG_ 1060 AIR_COMPRESSOR_STATUS_AVAIL "PACMod sets this value as a function of which vehicle platform is under test and, therefore, this value does not change during operation.";

// ANG_VEL_RPT COMMENTS
CM_ SG_ 1050 PITCH_VEL "Pitch is positive according to right hand rule with the axis pointing to the left as the vehicle goes forward.";
CM_ SG_ 1050 ROLL_VEL "Roll is positive according to right hand rule with the axis pointing forward.";
CM_ SG_ 1050 YAW_VEL "Yaw is positive according to right hand rule with the axis pointing up.";

// BRAKE_AUX_RPT COMMENTS
CM_ SG_ 772 BRAKE_PRESSURE_2 "Ratio of full-scale value of signal from 0 to 1 (i.e. percent from 0 to 1) possible exceeding 1.";
CM_ SG_ 772 BRAKE_PRESSURE "Ratio of full-scale value of signal from 0 to 1 (i.e. percent from 0 to 1) possible exceeding 1.";
CM_ SG_ 772 OPERATOR_INTERACTION "OPERATOR_INTERACTION shall have the value of 1 if the driver is moving, changing, or otherwise touching the operator control(s) that relates to this signal to an extent that is detectable. Otherwise, the value shall be 0.";
CM_ SG_ 772 BRAKE_LIMITING_ACTIVE "BRAKE_LIMITING_ACTIVE shall have the value of 1 if a limiting function is reducing an excessive command.  Otherwise, the value shall be 0.";
CM_ SG_ 772 BRAKE_REDUCED_ASSIST "BRAKE_REDUCED_ASSIST shall have the value of 1 if Brake System is in a reduced assist mode. Otherwise, the value shall be 0.";
CM_ SG_ 772 CALIBRATION_STATUS "CALIBRATION_STATUS shall indicate the status of a calibration of this system. If this system has more than one calibration, then those calibrations are INACTIVE.";
CM_ SG_ 772 BRAKE_ON_OFF_AVAIL "PACMod sets this value as a function of which vehicle platform is under test and, therefore, this value does not change during operation.";
CM_ SG_ 772 OPERATOR_INTERACTION_AVAIL "PACMod sets this value as a function of which vehicle platform is under test and, therefore, this value does not change during operation.";
CM_ SG_ 772 BRAKE_PRESSURE_2_AVAIL "PACMod sets this value as a function of which vehicle platform is under test and, therefore, this value does not change during operation.";
CM_ SG_ 772 BRAKE_PRESSURE_AVAIL "PACMod sets this value as a function of which vehicle platform is under test and, therefore, this value does not change during operation.";
CM_ SG_ 772 BRAKE_LIMITING_ACTIVE_AVAIL "PACMod sets this value as a function of which vehicle platform is under test and, therefore, this value does not change during operation.";
CM_ SG_ 772 BRAKE_REDUCED_ASSIST_AVAIL "PACMod sets this value as a function of which vehicle platform is under test and, therefore, this value does not change during operation.";

// BRAKE_AUX_RPT_2 COMMENTS
CM_ SG_ 774 BRAKE_PRESSURE_2 "Ratio of full-scale value of signal from 0 to 1 (i.e. percent from 0 to 1) possible exceeding 1.";
CM_ SG_ 774 BRAKE_PRESSURE "Ratio of full-scale value of signal from 0 to 1 (i.e. percent from 0 to 1) possible exceeding 1.";
CM_ SG_ 774 OPERATOR_INTERACTION "OPERATOR_INTERACTION shall have the value of 1 if the driver is moving, changing, or otherwise touching the operator control(s) that relates to this signal to an extent that is detectable. Otherwise, the value shall be 0.";
CM_ SG_ 774 BRAKE_LIMITING_ACTIVE "BRAKE_LIMITING_ACTIVE shall have the value of 1 if a limiting function is reducing an excessive command.  Otherwise, the value shall be 0.";
CM_ SG_ 774 BRAKE_REDUCED_ASSIST "BRAKE_REDUCED_ASSIST shall have the value of 1 if Brake System is in a reduced assist mode. Otherwise, the value shall be 0.";
CM_ SG_ 774 CALIBRATION_STATUS "CALIBRATION_STATUS shall indicate the status of a calibration of this system. If this system has more than one calibration, then those calibrations are INACTIVE.";
CM_ SG_ 774 BRAKE_ON_OFF_AVAIL "PACMod sets this value as a function of which vehicle platform is under test and, therefore, this value does not change during operation.";
CM_ SG_ 774 OPERATOR_INTERACTION_AVAIL "PACMod sets this value as a function of which vehicle platform is under test and, therefore, this value does not change during operation.";
CM_ SG_ 774 BRAKE_PRESSURE_2_AVAIL "PACMod sets this value as a function of which vehicle platform is under test and, therefore, this value does not change during operation.";
CM_ SG_ 774 BRAKE_PRESSURE_AVAIL "PACMod sets this value as a function of which vehicle platform is under test and, therefore, this value does not change during operation.";
CM_ SG_ 774 BRAKE_LIMITING_ACTIVE_AVAIL "PACMod sets this value as a function of which vehicle platform is under test and, therefore, this value does not change during operation.";
CM_ SG_ 774 BRAKE_REDUCED_ASSIST_AVAIL "PACMod sets this value as a function of which vehicle platform is under test and, therefore, this value does not change during operation.";

// BRAKE_CMD COMMENTS
CM_ SG_ 260 BRAKE_CMD "Ratio of full-scale value of signal from 0 to 1 (i.e. percent from 0 to 1).";

// BRAKE_CMD_LIMIT_RPT COMMENTS
CM_ SG_ 517 BRAKE_CMD_LIMIT "The BRAKE_CMD_LIMIT shall have the value of the limit imposed on the command associated with this system. Ratio of full-scale value of signal from 0 to 1 (i.e. percent from 0 to 1).";
CM_ SG_ 517 LIMITED_BRAKE_CMD "The LIMITED_BRAKE_CMD shall have the value of command associated with this system constrained by the BRAKE_CMD_LIMIT. Ratio of full-scale value of signal from 0 to 1 (i.e. percent from 0 to 1).";

// BRAKE_DECEL_AUX_RPT COMMENTS
CM_ SG_ 824 XBR_ACTIVE_CONTROL_MODE_AVAIL "PACMod sets this value as a function of which vehicle platform is under test and, therefore, this value does not change during operation.";
CM_ SG_ 824 XBR_SYSTEM_STATE_AVAIL "PACMod sets this value as a function of which vehicle platform is under test and, therefore, this value does not change during operation.";
CM_ SG_ 824 FOUNDATION_BRAKE_USE_AVAIL "PACMod sets this value as a function of which vehicle platform is under test and, therefore, this value does not change during operation.";
CM_ SG_ 824 HILL_HOLDER_MODE_AVAIL "PACMod sets this value as a function of which vehicle platform is under test and, therefore, this value does not change during operation.";

// BRAKE_MOTOR_RPT_1 COMMENTS
CM_ SG_ 1025 MOTOR_CURRENT "As reported by the motor.";
CM_ SG_ 1025 SHAFT_POSITION "As reported by the motor.";

// BRAKE_MOTOR_RPT_2 COMMENTS
CM_ SG_ 1026 ANGULAR_SPEED "As reported by the motor.";

// BRAKE_MOTOR_RPT_3 COMMENTS
CM_ SG_ 1027 TORQUE_OUTPUT "As reported by the motor.";
CM_ SG_ 1027 TORQUE_INPUT "As reported by the motor.";

// BRAKE_RPT COMMENTS
CM_ SG_ 516 MANUAL_INPUT "Ratio of full-scale value of signal from 0 to 1 (i.e. percent from 0 to 1).";
CM_ SG_ 516 COMMANDED_VALUE "Ratio of full-scale value of signal from 0 to 1 (i.e. percent from 0 to 1).";
CM_ SG_ 516 OUTPUT_VALUE "Ratio of full-scale value of signal from 0 to 1 (i.e. percent from 0 to 1).";
CM_ SG_ 516 CONTROLLING_SYSTEMS "Number of systems in control.";

// BRAKE_RPT_2 COMMENTS
CM_ SG_ 518 MANUAL_INPUT "Ratio of full-scale value of signal from 0 to 1 (i.e. percent from 0 to 1).";
CM_ SG_ 518 COMMANDED_VALUE "Ratio of full-scale value of signal from 0 to 1 (i.e. percent from 0 to 1).";
CM_ SG_ 518 OUTPUT_VALUE "Ratio of full-scale value of signal from 0 to 1 (i.e. percent from 0 to 1).";
CM_ SG_ 518 CONTROLLING_SYSTEMS "Number of systems in control.";

// COMPONENT_AUX_RPT_00 COMMENTS
CM_ SG_ 1100 LOCATION_CODE "This value reports the location of the ECU in the by-wire harness. The ECU assesses this value at startup, and this value does not change during operation.";

// COMPONENT_AUX_RPT_01 COMMENTS
CM_ SG_ 1101 LOCATION_CODE "This value reports the location of the ECU in the by-wire harness. The ECU assesses this value at startup, and this value does not change during operation.";

// COMPONENT_AUX_RPT_02 COMMENTS
CM_ SG_ 1102 LOCATION_CODE "This value reports the location of the ECU in the by-wire harness. The ECU assesses this value at startup, and this value does not change during operation.";

// COMPONENT_AUX_RPT_03 COMMENTS
CM_ SG_ 1103 LOCATION_CODE "This value reports the location of the ECU in the by-wire harness. The ECU assesses this value at startup, and this value does not change during operation.";

// COMPONENT_AUX_RPT_04 COMMENTS
CM_ SG_ 1104 LOCATION_CODE "This value reports the location of the ECU in the by-wire harness. The ECU assesses this value at startup, and this value does not change during operation.";

// COMPONENT_AUX_RPT_05 COMMENTS
CM_ SG_ 1105 LOCATION_CODE "This value reports the location of the ECU in the by-wire harness. The ECU assesses this value at startup, and this value does not change during operation.";

// COMPONENT_RPT_00 COMMENTS
CM_ SG_ 32 COUNTER "Counter shall have the value of 0 with the first message transmission.  It shall increase by 1 with each subsequent message transmission up to and including the value of 0xF.  The next message transmission shall be 0, and this pattern shall repeat.";
CM_ SG_ 32 COMPLEMENT "The COMPLEMENT shall be the complement of the COUNTER.  For example, if COUNTER is 0x1011, then the COMPLEMENT is 0x0100." ;
CM_ SG_ 32 WATCHDOG_SANITY_FAULT "This value relates to problems with the COUNTER and COMPLIMENT signals in the component report received from the watchdog component." ;
CM_ SG_ 32 COMPONENT_READY "This value will indicate whether this component is ready for by-wire control." ;
CM_ SG_ 32 SYSTEM_ENABLED "One or more systems are enabled.";
CM_ SG_ 32 SYSTEM_OVERRIDE_ACTIVE "One or more overrides are active.";
CM_ SG_ 32 SYSTEM_FAULT_ACTIVE "One or more faults are active.";
CM_ SG_ 32 USER_PC_HEALTH_FAULT_00 "This value indicates the integrity and execution of code on the USER_PC.";
CM_ SG_ 32 USER_PC_HEALTH_FAULT_01 "This value indicates the integrity and execution of code on the USER_PC.";
CM_ SG_ 32 STATE "This value indicates the current state of the local state machine.";
CM_ SG_ 32 DBW_WARNING_LEVEL "The value 0 is no warning. The value increases from 0 to 3 with the severity of the failure. Values 4-7 are reserved. See the user guide for the exact definition.";

// COMPONENT_RPT_01 COMMENTS
CM_ SG_ 33 COUNTER "Counter shall have the value of 0 with the first message transmission.  It shall increase by 1 with each subsequent message transmission up to and including the value of 0xF.  The next message transmission shall be 0, and this pattern shall repeat.";
CM_ SG_ 33 COMPLEMENT "The COMPLEMENT shall be the complement of the COUNTER.  For example, if COUNTER is 0x1011, then the COMPLEMENT is 0x0100." ;
CM_ SG_ 33 WATCHDOG_SANITY_FAULT "This value relates to problems with the COUNTER and COMPLIMENT signals in the component report received from the watchdog component." ;
CM_ SG_ 33 COMPONENT_READY "This value will indicate whether this component is ready for by-wire control." ;
CM_ SG_ 33 SYSTEM_ENABLED "One or more systems are enabled.";
CM_ SG_ 33 SYSTEM_OVERRIDE_ACTIVE "One or more overrides are active.";
CM_ SG_ 33 SYSTEM_FAULT_ACTIVE "One or more faults are active.";
CM_ SG_ 33 USER_PC_HEALTH_FAULT_00 "This value indicates the integrity and execution of code on the USER_PC.";
CM_ SG_ 33 USER_PC_HEALTH_FAULT_01 "This value indicates the integrity and execution of code on the USER_PC.";
CM_ SG_ 33 STATE "This value indicates the current state of the local state machine.";
CM_ SG_ 33 DBW_WARNING_LEVEL "The value 0 is no warning. The value increases from 0 to 3 with the severity of the failure. Values 4-7 are reserved. See the user guide for the exact definition.";

// COMPONENT_RPT_02 COMMENTS
CM_ SG_ 34 COUNTER "Counter shall have the value of 0 with the first message transmission.  It shall increase by 1 with each subsequent message transmission up to and including the value of 0xF.  The next message transmission shall be 0, and this pattern shall repeat.";
CM_ SG_ 34 COMPLEMENT "The COMPLEMENT shall be the complement of the COUNTER.  For example, if COUNTER is 0x1011, then the COMPLEMENT is 0x0100." ;
CM_ SG_ 34 WATCHDOG_SANITY_FAULT "This value relates to problems with the COUNTER and COMPLIMENT signals in the component report received from the watchdog component." ;
CM_ SG_ 34 COMPONENT_READY "This value will indicate whether this component is ready for by-wire control." ;
CM_ SG_ 34 SYSTEM_ENABLED "One or more systems are enabled.";
CM_ SG_ 34 SYSTEM_OVERRIDE_ACTIVE "One or more overrides are active.";
CM_ SG_ 34 SYSTEM_FAULT_ACTIVE "One or more faults are active.";
CM_ SG_ 34 USER_PC_HEALTH_FAULT_00 "This value indicates the integrity and execution of code on the USER_PC.";
CM_ SG_ 34 USER_PC_HEALTH_FAULT_01 "This value indicates the integrity and execution of code on the USER_PC.";
CM_ SG_ 34 STATE "This value indicates the current state of the local state machine.";
CM_ SG_ 34 DBW_WARNING_LEVEL "The value 0 is no warning. The value increases from 0 to 3 with the severity of the failure. Values 4-7 are reserved. See the user guide for the exact definition.";

// COMPONENT_RPT_03 COMMENTS
CM_ SG_ 35 COUNTER "Counter shall have the value of 0 with the first message transmission.  It shall increase by 1 with each subsequent message transmission up to and including the value of 0xF.  The next message transmission shall be 0, and this pattern shall repeat.";
CM_ SG_ 35 COMPLEMENT "The COMPLEMENT shall be the complement of the COUNTER.  For example, if COUNTER is 0x1011, then the COMPLEMENT is 0x0100." ;
CM_ SG_ 35 WATCHDOG_SANITY_FAULT "This value relates to problems with the COUNTER and COMPLIMENT signals in the component report received from the watchdog component." ;
CM_ SG_ 35 COMPONENT_READY "This value will indicate whether this component is ready for by-wire control." ;
CM_ SG_ 35 SYSTEM_ENABLED "One or more systems are enabled.";
CM_ SG_ 35 SYSTEM_OVERRIDE_ACTIVE "One or more overrides are active.";
CM_ SG_ 35 SYSTEM_FAULT_ACTIVE "One or more faults are active.";
CM_ SG_ 35 USER_PC_HEALTH_FAULT_00 "This value indicates the integrity and execution of code on the USER_PC.";
CM_ SG_ 35 USER_PC_HEALTH_FAULT_01 "This value indicates the integrity and execution of code on the USER_PC.";
CM_ SG_ 35 STATE "This value indicates the current state of the local state machine.";
CM_ SG_ 35 DBW_WARNING_LEVEL "The value 0 is no warning. The value increases from 0 to 3 with the severity of the failure. Values 4-7 are reserved. See the user guide for the exact definition.";

// COMPONENT_RPT_04 COMMENTS
CM_ SG_ 36 COUNTER "Counter shall have the value of 0 with the first message transmission.  It shall increase by 1 with each subsequent message transmission up to and including the value of 0xF.  The next message transmission shall be 0, and this pattern shall repeat.";
CM_ SG_ 36 COMPLEMENT "The COMPLEMENT shall be the complement of the COUNTER.  For example, if COUNTER is 0x1011, then the COMPLEMENT is 0x0100." ;
CM_ SG_ 36 WATCHDOG_SANITY_FAULT "This value relates to problems with the COUNTER and COMPLIMENT signals in the component report received from the watchdog component." ;
CM_ SG_ 36 COMPONENT_READY "This value will indicate whether this component is ready for by-wire control." ;
CM_ SG_ 36 SYSTEM_ENABLED "One or more systems are enabled.";
CM_ SG_ 36 SYSTEM_OVERRIDE_ACTIVE "One or more overrides are active.";
CM_ SG_ 36 SYSTEM_FAULT_ACTIVE "One or more faults are active.";
CM_ SG_ 36 USER_PC_HEALTH_FAULT_00 "This value indicates the integrity and execution of code on the USER_PC.";
CM_ SG_ 36 USER_PC_HEALTH_FAULT_01 "This value indicates the integrity and execution of code on the USER_PC.";
CM_ SG_ 36 STATE "This value indicates the current state of the local state machine.";
CM_ SG_ 36 DBW_WARNING_LEVEL "The value 0 is no warning. The value increases from 0 to 3 with the severity of the failure. Values 4-7 are reserved. See the user guide for the exact definition.";

// COMPONENT_RPT_05 COMMENTS
CM_ SG_ 39 COUNTER "Counter shall have the value of 0 with the first message transmission.  It shall increase by 1 with each subsequent message transmission up to and including the value of 0xF.  The next message transmission shall be 0, and this pattern shall repeat.";
CM_ SG_ 39 COMPLEMENT "The COMPLEMENT shall be the complement of the COUNTER.  For example, if COUNTER is 0x1011, then the COMPLEMENT is 0x0100.";
CM_ SG_ 39 WATCHDOG_SANITY_FAULT "This value relates to problems with the COUNTER and COMPLIMENT signals in the component report received from the watchdog component.";
CM_ SG_ 39 COMPONENT_READY "This value will indicate whether this component is ready for by-wire control.";
CM_ SG_ 39 SYSTEM_ENABLED "One or more systems are enabled.";
CM_ SG_ 39 SYSTEM_OVERRIDE_ACTIVE "One or more overrides are active.";
CM_ SG_ 39 SYSTEM_FAULT_ACTIVE "One or more faults are active.";
CM_ SG_ 39 USER_PC_HEALTH_FAULT_00 "This value indicates the integrity and execution of code on the USER_PC.";
CM_ SG_ 39 USER_PC_HEALTH_FAULT_01 "This value indicates the integrity and execution of code on the USER_PC.";
CM_ SG_ 39 STATE "This value indicates the current state of the local state machine.";
CM_ SG_ 39 DBW_WARNING_LEVEL "The value 0 is no warning. The value increases from 0 to 3 with the severity of the failure. Values 4-7 are reserved. See the user guide for the exact definition.";

// CRUISE_CONTROL_BUTTONS_CMD COMMENTS
CM_ SG_ 264 CRUISE_CONTROL_BUTTON "NONE = no button pressed, CNCL = Cancel, FURTHER* or CLOSER* = Change follow distance, SET_DEC* = set/decrement, RES_INC* = resume/increment, ON_OFF = Cruise On/Off, LIM* = Speed limiter On/Off. *Exact function varies across vehicles - See platform guide.";

// CRUISE_CONTROL_BUTTONS_RPT COMMENTS
CM_ SG_ 520 MANUAL_INPUT "NONE = no button pressed, CNCL = Cancel, FURTHER* or CLOSER* = Change follow distance, SET_DEC* = set/decrement, RES_INC* = resume/increment, ON_OFF = Cruise On/Off, LIM* = Speed limiter On/Off. *Exact function varies across vehicles - See platform guide.";
CM_ SG_ 520 COMMANDED_VALUE "NONE = no button pressed, CNCL = Cancel, FURTHER* or CLOSER* = Change follow distance, SET_DEC* = set/decrement, RES_INC* = resume/increment, ON_OFF = Cruise On/Off, LIM* = Speed limiter On/Off. *Exact function varies across vehicles - See platform guide.";
CM_ SG_ 520 OUTPUT_VALUE "NONE = no button pressed, CNCL = Cancel, FURTHER* or CLOSER* = Change follow distance, SET_DEC* = set/decrement, RES_INC* = resume/increment, ON_OFF = Cruise On/Off, LIM* = Speed limiter On/Off. *Exact function varies across vehicles - See platform guide.";

// DBW_HEALTH_RPT_00 COMMENTS
CM_ SG_ 40 COUNTER "The COUNTER shall have the value of 0 with the first message transmission. It shall increase by 1 with each subsequent message transmission up to and including the value of 0xFF. The next message transmission shall be 0, and this pattern shall repeat.";
CM_ SG_ 40 CHECKSUM "The CHECKSUM shall be the least significant byte of the sum of the message ID and the COUNTER. For example, if COUNTER is 0xFB and the message ID is 0x25, then the sum is 0x0120 and the checksum is 0x20.";
CM_ SG_ 40 DBW_WARNING_LEVEL "The value 0 is no warning. The value increases from 0 to 3 with the severity of the failure. Values 4-7 are reserved. See the user guide for the exact definition.";

// DBW_HEALTH_RPT_01 COMMENTS
CM_ SG_ 41 COUNTER "The COUNTER shall have the value of 0 with the first message transmission. It shall increase by 1 with each subsequent message transmission up to and including the value of 0xFF. The next message transmission shall be 0, and this pattern shall repeat.";
CM_ SG_ 41 CHECKSUM "The CHECKSUM shall be the least significant byte of the sum of the message ID and the COUNTER. For example, if COUNTER is 0xFB and the message ID is 0x25, then the sum is 0x0120 and the checksum is 0x20.";
CM_ SG_ 41 DBW_WARNING_LEVEL "The value 0 is no warning. The value increases from 0 to 3 with the severity of the failure. Values 4-7 are reserved. See the user guide for the exact definition.";

// DRIVE_TRAIN_FEATURE_RPT COMMENTS
CM_ SG_ 1055 ANTILOCK_BRAKE_DISABLED_AVAIL "PACMod sets this value as a function of which vehicle platform is under test and, therefore, this value does not change during operation.";
CM_ SG_ 1055 ANTILOCK_BRAKE_ACTIVE_AVAIL "PACMod sets this value as a function of which vehicle platform is under test and, therefore, this value does not change during operation.";
CM_ SG_ 1055 TRACTION_CONTROL_ACTIVE_AVAIL "PACMod sets this value as a function of which vehicle platform is under test and, therefore, this value does not change during operation.";
CM_ SG_ 1055 FOUR_WHEEL_DRIVE_ACTIVE_AVAIL "PACMod sets this value as a function of which vehicle platform is under test and, therefore, this value does not change during operation.";
CM_ SG_ 1055 DRIVE_MODE_AVAIL "PACMod sets this value as a function of which vehicle platform is under test and, therefore, this value does not change during operation.";
CM_ SG_ 1055 TRACTION_CONTROL_DISABLED_AVAIL "PACMod sets this value as a function of which vehicle platform is under test and, therefore, this value does not change during operation.";

// ENGINE_BRAKE_AUX_RPT COMMENTS
CM_ SG_ 836 ACTUAL_ENGINE_BRK_TORQUE "Less than 0 indicates the engine brake is actively braking the vehicle.";
CM_ SG_ 836 INTENDED_ENGINE_BRK_TORQUE "Less than 0 indicates the engine brake is actively braking the vehicle.";
CM_ SG_ 836 ENGINE_BRAKE_STATUS_AVAIL "PACMod sets this value as a function of which vehicle platform is under test and, therefore, this value does not change during operation.";
CM_ SG_ 836 ACTUAL_ENGINE_BRK_TORQUE_AVAIL "PACMod sets this value as a function of which vehicle platform is under test and, therefore, this value does not change during operation.";
CM_ SG_ 836 INTENDED_ENGINE_BRK_TORQUE_AVAIL "PACMod sets this value as a function of which vehicle platform is under test and, therefore, this value does not change during operation.";

// ENGINE_BRAKE_CMD COMMENTS
CM_ SG_ 324 ENGINE_BRAKE_CMD "Brake aggressiveness increases with increasing numerical values. Each operator control setting maps one-to-one with each LEVEL, starting with 1. Higher LEVELs with no match map to maximum.";
CM_ SG_ 324 AUTO_CMD "Braking aggressivness automatic while AUTO_ON.";

// ENGINE_BRAKE_RPT COMMENTS
CM_ SG_ 580 MANUAL_INPUT "Brake aggressiveness increases with increasing numerical values. Each operator control setting maps one-to-one with each LEVEL, starting with 1. Higher LEVELs with no match map to maximum.";
CM_ SG_ 580 COMMANDED_VALUE "Brake aggressiveness increases with increasing numerical values. Each operator control setting maps one-to-one with each LEVEL, starting with 1. Higher LEVELs with no match map to maximum.";
CM_ SG_ 580 OUTPUT_VALUE "Brake aggressiveness increases with increasing numerical values. Each operator control setting maps one-to-one with each LEVEL, starting with 1. Higher LEVELs with no match map to maximum.";
CM_ SG_ 580 MAN_AUTO "Braking aggressiveness automatic while AUTO_ON.";
CM_ SG_ 580 CMD_AUTO "Braking aggressiveness automatic while AUTO_ON.";
CM_ SG_ 580 OUT_AUTO "Braking aggressiveness automatic while AUTO_ON.";

// ENGINE_AUX_RPT COMMENTS
CM_ SG_ 1040 ENGINE_SPEED_AVAIL "PACMod sets this value as a function of which vehicle platform is under test and, therefore, this value does not change during operation.";
CM_ SG_ 1040 ENGINE_TORQUE_AVAIL "PACMod sets this value as a function of which vehicle platform is under test and, therefore, this value does not change during operation.";
CM_ SG_ 1040 ENGINE_COOLANT_TEMP_AVAIL "PACMod sets this value as a function of which vehicle platform is under test and, therefore, this value does not change during operation.";
CM_ SG_ 1040 FUEL_LEVEL_AVAIL "PACMod sets this value as a function of which vehicle platform is under test and, therefore, this value does not change during operation.";
CM_ SG_ 1040 FUEL_LEVEL "Ratio of full-scale value of signal from 0 to 1 (i.e. percent from 0 to 1).";
CM_ SG_ 1040 DIESEL_EXHAUST_FLUID_LEVEL_AVAIL "PACMod sets this value as a function of which vehicle platform is under test and, therefore, this value does not change during operation.";
CM_ SG_ 1040 DIESEL_EXHAUST_FLUID_LEVEL "Ratio of full-scale value of signal from 0 to 1 (i.e. percent from 0 to 1).";

// ENGINE_AUX_RPT_2 COMMENTS
CM_ SG_ 1061 FUEL_RATE_AVAIL "PACMod sets this value as a function of which vehicle platform is under test and, therefore, this value does not change during operation.";
CM_ SG_ 1061 OIL_LEVEL_AVAIL "PACMod sets this value as a function of which vehicle platform is under test and, therefore, this value does not change during operation.";
CM_ SG_ 1061 OIL_PRESSURE_AVAIL "PACMod sets this value as a function of which vehicle platform is under test and, therefore, this value does not change during operation.";
CM_ SG_ 1061 OIL_LEVEL "Ratio of full-scale value of signal from 0 to 1 (i.e. percent from 0 to 1).";

// ENGINE_LOAD_FACTOR_RPT COMMENTS
CM_ SG_ 1063 DRVR_DEMANDED_ENG_TORQUE "The requested torque output of the engine by the driver.";
CM_ SG_ 1063 ACTUAL_ENGINE_TORQUE "The calculated output torque of the engine.";
CM_ SG_ 1063 ENG_LOAD_AT_CURRENT_SPEED "The ratio of actual engine torque to maximum torque available at the current engine speed, clipped to zero torque during engine braking.";
CM_ SG_ 1063 REFERENCE_ENGINE_TORQUE "100% reference value for engine torque parameters in the ENGINE_LOAD_FACTOR_RPT.";
CM_ SG_ 1063 DRVR_DEMANDED_ENG_TORQUE_AVAIL "PACMod sets this value as a function of which vehicle platform is under test and, therefore, this value does not change during operation.";
CM_ SG_ 1063 ACTUAL_ENGINE_TORQUE_AVAIL "PACMod sets this value as a function of which vehicle platform is under test and, therefore, this value does not change during operation.";
CM_ SG_ 1063 ENG_LOAD_AT_CURRENT_SPEED_AVAIL "PACMod sets this value as a function of which vehicle platform is under test and, therefore, this value does not change during operation.";
CM_ SG_ 1063 REFERENCE_ENGINE_TORQUE_AVAIL "PACMod sets this value as a function of which vehicle platform is under test and, therefore, this value does not change during operation.";

// GLOBAL_CMD COMMENTS
CM_ SG_ 128 SANITY_CHECK_REQUIRED "When this value is REQUIRED, the COUNTER and COMPLEMENT values must be set to enable the PACMod System.";
CM_ SG_ 128 DEVELOPMENT_MODE_REQUEST "PACMod enables/disables features for development when this value is TRUE and conditions are suitable. Warning, this could include disabling safety features. It is not suitable for general use. *Exact function varies across vehicles - See platform guide.";
CM_ SG_ 128 COUNTER "Counter shall have the value of 0 with the first message transmission.  It shall increase by 1 with each subsequent message transmission up to and including the value of 0xF.  The next message transmission shall be 0, and this pattern shall repeat.";
CM_ SG_ 128 COMPLEMENT "The COMPLEMENT shall be the complement of the COUNTER.  For example, if COUNTER is 0x1011, then the COMPLEMENT is 0x0100." ;

// GLOBAL_RPT COMMENTS
CM_ SG_ 16 SUPERVISORY_ENABLE_REQUIRED "Supervisory Enablement Rules apply when SUPERVISORY_ENABLE_REQUIRED is REQUIRED.  It provides backward compatibility with prior versions of this specification that did not have the SUPERVISORY_CTRL message." ;

// GLOBAL_RPT_2 COMMENTS
CM_ SG_ 17 SYSTEM_ENABLED "One or more systems are enabled." ;
CM_ SG_ 17 SYSTEM_FAULT_ACTIVE "One or more faults are active." ;
CM_ SG_ 17 SUPERVISORY_ENABLE_REQUIRED "Supervisory Enablement Rules apply when SUPERVISORY_ENABLE_REQUIRED is REQUIRED.  It provides backward compatibility with prior versions of this specification that did not have the SUPERVISORY_CTRL message." ;
CM_ SG_ 17 DISABLE_ALL_SYSTEMS "Global Command Sanity Check Rules and System Global Disable Rules apply when SANITY_CHECK_REQUIRED is REQUIRED." ;
CM_ SG_ 17 SYSTEM_READY "System Ready Rules apply at all times." ;
CM_ SG_ 17 ENABLE_METHOD "This value reports which enable method is used. The file user_can_protocol.md lists the available enable methods." ;
CM_ SG_ 17 DEVELOPMENT_MODE "Indicates if PACMOD is currently in development mode.";
CM_ SG_ 17 DEVELOPMENT_MODE_ALLOWED "Indicates if PACMOD will allow a transition into development mode.";

// HAZARD_LIGHTS_RPT COMMENTS
CM_ SG_ 532 MANUAL_INPUT "Platforms vary on use of latched or momentary interface, see platform user guide." ;
CM_ SG_ 532 OUTPUT_VALUE "Platforms vary on use of latched or momentary interface, see platform user guide." ;

// HEADLIGHT_AUX_RPT COMMENTS
CM_ SG_ 792 HEADLIGHTS_MODE_AVAIL "PACMod sets this value as a function of which vehicle platform is under test and, therefore, this value does not change during operation.";
CM_ SG_ 792 FOG_LIGHTS_ON_AVAIL "PACMod sets this value as a function of which vehicle platform is under test and, therefore, this value does not change during operation.";
CM_ SG_ 792 HEADLIGHTS_ON_BRIGHT_AVAIL "PACMod sets this value as a function of which vehicle platform is under test and, therefore, this value does not change during operation.";
CM_ SG_ 792 HEADLIGHTS_ON_AVAIL "PACMod sets this value as a function of which vehicle platform is under test and, therefore, this value does not change during operation.";

// INTERIOR_LIGHTS_RPT COMMENTS
CM_ SG_ 1046 DIM_LEVEL "Lowest dim level assigned to DIM_LEVEL_MIN, the dimmest light. Highest dim level assigned to DIM_LEVEL_MAX, the brightest light. Dim levels in between start with DIM_LEVEL_1.";

// LINEAR_ACCEL_RPT COMMENTS
CM_ SG_ 1049 LATERAL_ACCEL "Lateral acceleration is positive in the left direction as the vehicle goes forward." ;
CM_ SG_ 1049 LONGITUDINAL_ACCEL "Longitudinal acceleration is positive in the forward direction." ;
CM_ SG_ 1049 VERTICAL_ACCEL "Vertical acceleration is positive in the upward direction." ;

// PARKING_BRAKE_RPT COMMENTS
CM_ SG_ 548 CONTROLLING_SYSTEMS "Number of systems in control.";

// PARKING_BRAKE_RPT_2 COMMENTS
CM_ SG_ 550 CONTROLLING_SYSTEMS "Number of systems in control.";

// SAFETY_FUNC_CRITICAL_STOP_RPT COMMENTS
CM_ SG_ 1056 AUTOMS_MAN_OPCTRL_FAULT "This value shall latch while the safety function is in the critical stop state.";
CM_ SG_ 1056 REMOTE_STOP_FAULT "This value shall latch while the safety function is in the critical stop state.";
CM_ SG_ 1056 SAFETY_BRAKE_OPCTRL_OFF "This value shall latch while the safety function is in the critical stop state.";
CM_ SG_ 1056 SAFETY_BRAKE_CMD_TIMEOUT "This value shall latch while the safety function is in the critical stop state.";
CM_ SG_ 1056 SAFETY_FUNC_CMD_TIMEOUT "This value shall latch while the safety function is in the critical stop state.";
CM_ SG_ 1056 SAFETY_FUNC_CRITICAL_STOP_1_CMD "This value shall latch while the safety function is in the critical stop state.";
CM_ SG_ 1056 SAFETY_FUNC_CRITICAL_STOP_2_CMD "This value shall latch while the safety function is in the critical stop state.";
CM_ SG_ 1056 SAFETY_FUNC_NONE_CMD "This value shall latch while the safety function is in the critical stop state.";
CM_ SG_ 1056 PACMOD_SYSTEM_TIMEOUT "This value shall latch while the safety function is in the critical stop state.";
CM_ SG_ 1056 PACMOD_SYSTEM_FAULT "This value shall latch while the safety function is in the critical stop state.";
CM_ SG_ 1056 PACMOD_SYSTEM_NOT_ACTIVE "This value shall latch while the safety function is in the critical stop state.";
CM_ SG_ 1056 VEHICLE_REPORT_TIMEOUT "This value shall latch while the safety function is in the critical stop state.";
CM_ SG_ 1056 VEHICLE_REPORT_FAULT "This value shall latch while the safety function is in the critical stop state.";
CM_ SG_ 1056 LOW_ENGINE_RPM "This value shall latch while the safety function is in the critical stop state.";
CM_ SG_ 1056 PRI_SAFETY_BRAKE_SIGNAL_1_FAULT "This value shall latch while the safety function is in the critical stop state. It shall be TRUE when the primary microprocessor detects a fault on signal 1.";
CM_ SG_ 1056 PRI_SAFETY_BRAKE_SIGNAL_2_FAULT "This value shall latch while the safety function is in the critical stop state. It shall be TRUE when the primary microprocessor detects a fault on signal 2.";
CM_ SG_ 1056 SEC_SAFETY_BRAKE_SIGNAL_1_FAULT "This value shall latch while the safety function is in the critical stop state. It shall be TRUE when the secondary microprocessor detects a fault on signal 1.";
CM_ SG_ 1056 SEC_SAFETY_BRAKE_SIGNAL_2_FAULT "This value shall latch while the safety function is in the critical stop state. It shall be TRUE when the secondary microprocessor detects a fault on signal 2.";
CM_ SG_ 1056 PRIMARY_PROCESSOR_FAULT "This value shall latch while the safety function is in the critical stop state.";
CM_ SG_ 1056 SECONDARY_PROCESSOR_FAULT "This value shall latch while the safety function is in the critical stop state.";
CM_ SG_ 1056 REMOTE_STOP_CMD "This value shall latch while the safety function is in the critical stop state.";
CM_ SG_ 1056 PRI_SAFETY_BRAKE_PRESSURE_FAULT "This value shall latch while the safety function is in the critical stop state. It shall be TRUE when the primary microprocessor detects disagreement between safety brake command and safety brake response.";

/////////////////////////////
//                         //
//  Attribute Definitions  //
//                         //
/////////////////////////////
BA_DEF_ BO_  "GenMsgCycleTime" INT 0 60000;
BA_DEF_ SG_  "GenSigCycleTime" INT 0 60000;
BA_DEF_ SG_  "GenSigSendType" ENUM  "Cyclic ","OnWrite ","OnWriteWithRepetition ","OnChange ","OnChangeWithRepetition ","IfActive ","IfActiveWithRepetition ","NoSigSendType";
BA_DEF_ BO_  "GenMsgSendType" ENUM  "Cyclic ","NotUsed ","NotUsed ","NotUsed ","NotUsed ","NotUsed ","NotUsed ","IfActive ","NoMsgSendType ";
BA_DEF_ BO_  "Component_Address_Type" ENUM  "NO_COMPONENT_ADDRESS","COMPONENT_ADDRESS";
BA_DEF_ BO_  "Component_Address" INT 0 255;

////////////////////////////////
//                            //
//  Attribute Default Values  //
//                            //
////////////////////////////////
BA_DEF_DEF_  "GenSigCycleTime" 33;
BA_DEF_DEF_  "GenMsgCycleTime" 33;
BA_DEF_DEF_  "GenSigSendType" "NoSigSendType";
BA_DEF_DEF_  "GenMsgSendType" "Cyclic ";
BA_DEF_DEF_  "Component_Address_Type" "NO_COMPONENT_ADDRESS";
BA_DEF_DEF_  "Component_Address" 0;

/////////////////////////////////////
//                                 //
//  Message and Signal Attributes  //
//                                 //
/////////////////////////////////////
// AIR_PRESSURE_RPT ATTRIBUTES
BA_ "GenMsgCycleTime" BO_ 1060 1000;
BA_ "GenSigCycleTime" SG_ 1060 PNEUMATIC_SUPPLY_PRESSURE 1000;
BA_ "GenSigCycleTime" SG_ 1060 BRAKE_CIRCUIT_1_PRESSURE 1000;
BA_ "GenSigCycleTime" SG_ 1060 BRAKE_CIRCUIT_2_PRESSURE 1000;
BA_ "GenSigCycleTime" SG_ 1060 PARK_TRAILER_AIR_PRESSURE 1000;
BA_ "GenSigCycleTime" SG_ 1060 POWERTRAIN_AIR_PRESSURE 1000;
BA_ "GenSigCycleTime" SG_ 1060 AIR_COMPRESSOR_STATUS 1000;
BA_ "GenSigCycleTime" SG_ 1060 PNEUMATIC_SUPPLY_PRESSURE_AVAIL 1000;
BA_ "GenSigCycleTime" SG_ 1060 BRAKE_CIRCUIT_1_PRESSURE_AVAIL 1000;
BA_ "GenSigCycleTime" SG_ 1060 BRAKE_CIRCUIT_2_PRESSURE_AVAIL 1000;
BA_ "GenSigCycleTime" SG_ 1060 PARK_TRAILER_AIR_PRESSURE_AVAIL 1000;
BA_ "GenSigCycleTime" SG_ 1060 POWERTRAIN_AIR_PRESSURE_AVAIL 1000;
BA_ "GenSigCycleTime" SG_ 1060 AIR_COMPRESSOR_STATUS_AVAIL 1000;

// AMBIENT_CONDITION_RPT ATTRIBUTES
BA_ "GenMsgCycleTime" BO_ 1094 1000;
BA_ "GenSigCycleTime" SG_ 1094 INTERIOR_AMBIENT_TEMP 1000;
BA_ "GenSigCycleTime" SG_ 1094 INTERIOR_AMBIENT_TEMP_WARNING 1000;

// AUTOMS_MAN_SWITCH_RPT ATTRIBUTES
BA_ "GenMsgCycleTime" BO_ 1077 500;
BA_ "GenSigCycleTime" SG_ 1077 AUTOMS_MAN_OPCTRL 500;
BA_ "GenSigCycleTime" SG_ 1077 AUTOMS_MAN_EXTCTRL 500;
BA_ "GenSigCycleTime" SG_ 1077 AUTOMS_MAN_OPCTRL_AVAIL 500;
BA_ "GenSigCycleTime" SG_ 1077 AUTOMS_MAN_EXTCTRL_AVAIL 500;

// BATTERY_VOLTAGE_LEVEL_RPT_1 ATTRIBUTES
BA_ "GenMsgCycleTime" BO_ 1070 250;
BA_ "GenSigCycleTime" SG_ 1070 BATTERY_VOLTAGE_1 250;
BA_ "GenSigCycleTime" SG_ 1070 BATTERY_VOLTAGE_2 250;

// BATTERY_VOLTAGE_LEVEL_RPT_2 ATTRIBUTES
BA_ "GenMsgCycleTime" BO_ 1081 250;
BA_ "GenSigCycleTime" SG_ 1081 BATTERY_VOLTAGE_1 250;
BA_ "GenSigCycleTime" SG_ 1081 BATTERY_VOLTAGE_2 250;

// CABIN_CLIMATE_CMD ATTRIBUTES
BA_ "GenMsgCycleTime" BO_ 340 1000;
BA_ "GenSigCycleTime" SG_ 340 ENABLE 1000;
BA_ "GenSigCycleTime" SG_ 340 IGNORE_OVERRIDES 1000;
BA_ "GenSigCycleTime" SG_ 340 CLEAR_OVERRIDE 1000;
BA_ "GenSigCycleTime" SG_ 340 CMD_AC_OFF_ON 1000;
BA_ "GenSigCycleTime" SG_ 340 CMD_MAX_AC_OFF_ON 1000;
BA_ "GenSigCycleTime" SG_ 340 CMD_DEFROST_OFF_ON 1000;
BA_ "GenSigCycleTime" SG_ 340 CMD_MAX_DEFROST_OFF_ON 1000;
BA_ "GenSigCycleTime" SG_ 340 CMD_DIR_UP_OFF_ON 1000;
BA_ "GenSigCycleTime" SG_ 340 CMD_DIR_DOWN_OFF_ON 1000;

// CABIN_CLIMATE_RPT ATTRIBUTES
BA_ "GenMsgCycleTime" BO_ 596 1000;
BA_ "GenSigCycleTime" SG_ 596 ENABLED 1000;
BA_ "GenSigCycleTime" SG_ 596 OVERRIDE_ACTIVE 1000;
BA_ "GenSigCycleTime" SG_ 596 COMMAND_OUTPUT_FAULT 1000;
BA_ "GenSigCycleTime" SG_ 596 INPUT_OUTPUT_FAULT 1000;
BA_ "GenSigCycleTime" SG_ 596 OUTPUT_REPORTED_FAULT 1000;
BA_ "GenSigCycleTime" SG_ 596 PACMOD_FAULT 1000;
BA_ "GenSigCycleTime" SG_ 596 VEHICLE_FAULT 1000;
BA_ "GenSigCycleTime" SG_ 596 COMMAND_TIMEOUT 1000;
BA_ "GenSigCycleTime" SG_ 596 MAN_AC_OFF_ON 1000;
BA_ "GenSigCycleTime" SG_ 596 MAN_MAX_AC_OFF_ON 1000;
BA_ "GenSigCycleTime" SG_ 596 MAN_DEFROST_OFF_ON 1000;
BA_ "GenSigCycleTime" SG_ 596 MAN_MAX_DEFROST_OFF_ON 1000;
BA_ "GenSigCycleTime" SG_ 596 MAN_DIR_UP_OFF_ON 1000;
BA_ "GenSigCycleTime" SG_ 596 MAN_DIR_DOWN_OFF_ON 1000;
BA_ "GenSigCycleTime" SG_ 596 CMD_AC_OFF_ON 1000;
BA_ "GenSigCycleTime" SG_ 596 CMD_MAX_AC_OFF_ON 1000;
BA_ "GenSigCycleTime" SG_ 596 CMD_DEFROST_OFF_ON 1000;
BA_ "GenSigCycleTime" SG_ 596 CMD_MAX_DEFROST_OFF_ON 1000;
BA_ "GenSigCycleTime" SG_ 596 CMD_DIR_UP_OFF_ON 1000;
BA_ "GenSigCycleTime" SG_ 596 CMD_DIR_DOWN_OFF_ON 1000;
BA_ "GenSigCycleTime" SG_ 596 OUT_AC_OFF_ON 1000;
BA_ "GenSigCycleTime" SG_ 596 OUT_MAX_AC_OFF_ON 1000;
BA_ "GenSigCycleTime" SG_ 596 OUT_DEFROST_OFF_ON 1000;
BA_ "GenSigCycleTime" SG_ 596 OUT_MAX_DEFROST_OFF_ON 1000;
BA_ "GenSigCycleTime" SG_ 596 OUT_DIR_UP_OFF_ON 1000;
BA_ "GenSigCycleTime" SG_ 596 OUT_DIR_DOWN_OFF_ON 1000;

// CABIN_FAN_SPEED_CMD ATTRIBUTES
BA_ "GenMsgCycleTime" BO_ 336 1000;
BA_ "GenSigCycleTime" SG_ 336 ENABLE 1000;
BA_ "GenSigCycleTime" SG_ 336 IGNORE_OVERRIDES 1000;
BA_ "GenSigCycleTime" SG_ 336 CLEAR_OVERRIDE 1000;
BA_ "GenSigCycleTime" SG_ 336 CABIN_FAN_SPEED_CMD 1000;

// CABIN_FAN_SPEED_RPT ATTRIBUTES
BA_ "GenMsgCycleTime" BO_ 592 1000;
BA_ "GenSigCycleTime" SG_ 592 ENABLED 1000;
BA_ "GenSigCycleTime" SG_ 592 OVERRIDE_ACTIVE 1000;
BA_ "GenSigCycleTime" SG_ 592 COMMAND_OUTPUT_FAULT 1000;
BA_ "GenSigCycleTime" SG_ 592 INPUT_OUTPUT_FAULT 1000;
BA_ "GenSigCycleTime" SG_ 592 OUTPUT_REPORTED_FAULT 1000;
BA_ "GenSigCycleTime" SG_ 592 PACMOD_FAULT 1000;
BA_ "GenSigCycleTime" SG_ 592 VEHICLE_FAULT 1000;
BA_ "GenSigCycleTime" SG_ 592 COMMAND_TIMEOUT 1000;
BA_ "GenSigCycleTime" SG_ 592 MANUAL_INPUT 1000;
BA_ "GenSigCycleTime" SG_ 592 COMMANDED_VALUE 1000;
BA_ "GenSigCycleTime" SG_ 592 OUTPUT_VALUE 1000;

// CABIN_TEMP_CMD ATTRIBUTES
BA_ "GenMsgCycleTime" BO_ 332 1000;
BA_ "GenSigCycleTime" SG_ 332 ENABLE 1000;
BA_ "GenSigCycleTime" SG_ 332 IGNORE_OVERRIDES 1000;
BA_ "GenSigCycleTime" SG_ 332 CLEAR_OVERRIDE 1000;
BA_ "GenSigCycleTime" SG_ 332 CABIN_TEMP_CMD 1000;

// CABIN_TEMP_RPT ATTRIBUTES
BA_ "GenMsgCycleTime" BO_ 588 1000;
BA_ "GenSigCycleTime" SG_ 588 ENABLED 1000;
BA_ "GenSigCycleTime" SG_ 588 OVERRIDE_ACTIVE 1000;
BA_ "GenSigCycleTime" SG_ 588 COMMAND_OUTPUT_FAULT 1000;
BA_ "GenSigCycleTime" SG_ 588 INPUT_OUTPUT_FAULT 1000;
BA_ "GenSigCycleTime" SG_ 588 OUTPUT_REPORTED_FAULT 1000;
BA_ "GenSigCycleTime" SG_ 588 PACMOD_FAULT 1000;
BA_ "GenSigCycleTime" SG_ 588 VEHICLE_FAULT 1000;
BA_ "GenSigCycleTime" SG_ 588 COMMAND_TIMEOUT 1000;
BA_ "GenSigCycleTime" SG_ 588 MANUAL_INPUT 1000;
BA_ "GenSigCycleTime" SG_ 588 COMMANDED_VALUE 1000;
BA_ "GenSigCycleTime" SG_ 588 OUTPUT_VALUE 1000;

// CRUISE_CONTROL_BUTTONS_CMD ATTRIBUTES
BA_ "GenMsgCycleTime" BO_ 264 100;
BA_ "GenSigCycleTime" SG_ 264 ENABLE 100;
BA_ "GenSigCycleTime" SG_ 264 IGNORE_OVERRIDES 100;
BA_ "GenSigCycleTime" SG_ 264 CLEAR_OVERRIDE 100;
BA_ "GenSigCycleTime" SG_ 264 CRUISE_CONTROL_BUTTON 100;

// CRUISE_CONTROL_BUTTONS_RPT ATTRIBUTES
BA_ "GenMsgCycleTime" BO_ 520 100;
BA_ "GenSigCycleTime" SG_ 520 ENABLED 100;
BA_ "GenSigCycleTime" SG_ 520 OVERRIDE_ACTIVE 100;
BA_ "GenSigCycleTime" SG_ 520 COMMAND_OUTPUT_FAULT 100;
BA_ "GenSigCycleTime" SG_ 520 INPUT_OUTPUT_FAULT 100;
BA_ "GenSigCycleTime" SG_ 520 OUTPUT_REPORTED_FAULT 100;
BA_ "GenSigCycleTime" SG_ 520 PACMOD_FAULT 100;
BA_ "GenSigCycleTime" SG_ 520 VEHICLE_FAULT 100;
BA_ "GenSigCycleTime" SG_ 520 COMMAND_TIMEOUT 100;
BA_ "GenSigCycleTime" SG_ 520 MANUAL_INPUT 100;
BA_ "GenSigCycleTime" SG_ 520 COMMANDED_VALUE 100;
BA_ "GenSigCycleTime" SG_ 520 OUTPUT_VALUE 100;

// COMPONENT_AUX_RPT_00 ATTRIBUTES
BA_ "Component_Address_Type" BO_ 1100 1;
BA_ "GenMsgCycleTime" BO_ 1100 1000;
BA_ "GenSigCycleTime" SG_ 1100 LOCATION_CODE 1000;
BA_ "GenSigCycleTime" SG_ 1100 KEY_SWITCH_STATUS 1000;

// COMPONENT_AUX_RPT_01 ATTRIBUTES
BA_ "Component_Address" BO_ 1101 1;
BA_ "Component_Address_Type" BO_ 1101 1;
BA_ "GenMsgCycleTime" BO_ 1101 1000;
BA_ "GenSigCycleTime" SG_ 1101 LOCATION_CODE 1000;
BA_ "GenSigCycleTime" SG_ 1101 KEY_SWITCH_STATUS 1000;

// COMPONENT_AUX_RPT_02 ATTRIBUTES
BA_ "Component_Address" BO_ 1102 2;
BA_ "Component_Address_Type" BO_ 1102 1;
BA_ "GenMsgCycleTime" BO_ 1102 1000;
BA_ "GenSigCycleTime" SG_ 1102 LOCATION_CODE 1000;
BA_ "GenSigCycleTime" SG_ 1102 KEY_SWITCH_STATUS 1000;

// COMPONENT_AUX_RPT_03 ATTRIBUTES
BA_ "Component_Address" BO_ 1103 3;
BA_ "Component_Address_Type" BO_ 1103 1;
BA_ "GenMsgCycleTime" BO_ 1103 1000;
BA_ "GenSigCycleTime" SG_ 1103 LOCATION_CODE 1000;
BA_ "GenSigCycleTime" SG_ 1103 KEY_SWITCH_STATUS 1000;

// COMPONENT_AUX_RPT_04 ATTRIBUTES
BA_ "Component_Address" BO_ 1104 4;
BA_ "Component_Address_Type" BO_ 1104 1;
BA_ "GenMsgCycleTime" BO_ 1104 1000;
BA_ "GenSigCycleTime" SG_ 1104 LOCATION_CODE 1000;
BA_ "GenSigCycleTime" SG_ 1104 KEY_SWITCH_STATUS 1000;

// COMPONENT_AUX_RPT_05 ATTRIBUTES
BA_ "Component_Address" BO_ 1105 5;
BA_ "Component_Address_Type" BO_ 1105 1;
BA_ "GenMsgCycleTime" BO_ 1105 1000;
BA_ "GenSigCycleTime" SG_ 1105 LOCATION_CODE 1000;
BA_ "GenSigCycleTime" SG_ 1105 KEY_SWITCH_STATUS 1000;

// COMPONENT_RPT_00 ATTRIBUTES
BA_ "Component_Address_Type" BO_ 32 1;

// COMPONENT_RPT_01 ATTRIBUTES
BA_ "Component_Address" BO_ 33 1;
BA_ "Component_Address_Type" BO_ 33 1;

// COMPONENT_RPT_02 ATTRIBUTES
BA_ "Component_Address" BO_ 34 2;
BA_ "Component_Address_Type" BO_ 34 1;

// COMPONENT_RPT_03 ATTRIBUTES
BA_ "Component_Address" BO_ 35 3;
BA_ "Component_Address_Type" BO_ 35 1;

// COMPONENT_RPT_04 ATTRIBUTES
BA_ "Component_Address" BO_ 36 4;
BA_ "Component_Address_Type" BO_ 36 1;

// COMPONENT_RPT_05 ATTRIBUTES
BA_ "Component_Address" BO_ 39 4;
BA_ "Component_Address_Type" BO_ 39 1;

// DIFFERENTIAL_LOCKS_CMD ATTRIBUTES
BA_ "GenMsgCycleTime" BO_ 372 100;
BA_ "GenSigCycleTime" SG_ 372 ENABLE 100;
BA_ "GenSigCycleTime" SG_ 372 IGNORE_OVERRIDES 100;
BA_ "GenSigCycleTime" SG_ 372 CLEAR_OVERRIDE 100;
BA_ "GenSigCycleTime" SG_ 372 FRONT_LOCK_CMD 100;
BA_ "GenSigCycleTime" SG_ 372 CENTER_LOCK_CMD 100;
BA_ "GenSigCycleTime" SG_ 372 REAR_LOCK_CMD 100;

// DIFFERENTIAL_LOCKS_RPT ATTRIBUTES
BA_ "GenMsgCycleTime" BO_ 628 100;
BA_ "GenSigCycleTime" SG_ 628 ENABLED 100;
BA_ "GenSigCycleTime" SG_ 628 OVERRIDE_ACTIVE 100;
BA_ "GenSigCycleTime" SG_ 628 COMMAND_OUTPUT_FAULT 100;
BA_ "GenSigCycleTime" SG_ 628 INPUT_OUTPUT_FAULT 100;
BA_ "GenSigCycleTime" SG_ 628 OUTPUT_REPORTED_FAULT 100;
BA_ "GenSigCycleTime" SG_ 628 PACMOD_FAULT 100;
BA_ "GenSigCycleTime" SG_ 628 VEHICLE_FAULT 100;
BA_ "GenSigCycleTime" SG_ 628 COMMAND_TIMEOUT 100;
BA_ "GenSigCycleTime" SG_ 628 MAN_FRONT_LOCK 100;
BA_ "GenSigCycleTime" SG_ 628 MAN_CENTER_LOCK 100;
BA_ "GenSigCycleTime" SG_ 628 MAN_REAR_LOCK 100;
BA_ "GenSigCycleTime" SG_ 628 CMD_FRONT_LOCK 100;
BA_ "GenSigCycleTime" SG_ 628 CMD_CENTER_LOCK 100;
BA_ "GenSigCycleTime" SG_ 628 CMD_REAR_LOCK 100;
BA_ "GenSigCycleTime" SG_ 628 OUT_FRONT_LOCK 100;
BA_ "GenSigCycleTime" SG_ 628 OUT_CENTER_LOCK 100;
BA_ "GenSigCycleTime" SG_ 628 OUT_REAR_LOCK 100;

// EXHAUST_BRAKE_CMD ATTRIBUTES
BA_ "GenMsgCycleTime" BO_ 325 100;
BA_ "GenSigCycleTime" SG_ 325 ENABLE 100;
BA_ "GenSigCycleTime" SG_ 325 IGNORE_OVERRIDES 100;
BA_ "GenSigCycleTime" SG_ 325 CLEAR_OVERRIDE 100;
BA_ "GenSigCycleTime" SG_ 325 EXHAUST_BRAKE_CMD 100;

// EXHAUST_BRAKE_RPT ATTRIBUTES
BA_ "GenMsgCycleTime" BO_ 581 100;
BA_ "GenSigCycleTime" SG_ 581 ENABLED 100;
BA_ "GenSigCycleTime" SG_ 581 OVERRIDE_ACTIVE 100;
BA_ "GenSigCycleTime" SG_ 581 COMMAND_OUTPUT_FAULT 100;
BA_ "GenSigCycleTime" SG_ 581 INPUT_OUTPUT_FAULT 100;
BA_ "GenSigCycleTime" SG_ 581 OUTPUT_REPORTED_FAULT 100;
BA_ "GenSigCycleTime" SG_ 581 PACMOD_FAULT 100;
BA_ "GenSigCycleTime" SG_ 581 VEHICLE_FAULT 100;
BA_ "GenSigCycleTime" SG_ 581 COMMAND_TIMEOUT 100;
BA_ "GenSigCycleTime" SG_ 581 MANUAL_INPUT 100;
BA_ "GenSigCycleTime" SG_ 581 COMMANDED_VALUE 100;
BA_ "GenSigCycleTime" SG_ 581 OUTPUT_VALUE 100;

// DASH_CONTROLS_LEFT_CMD ATTRIBUTES
BA_ "GenMsgCycleTime" BO_ 268 100;
BA_ "GenSigCycleTime" SG_ 268 ENABLE 100;
BA_ "GenSigCycleTime" SG_ 268 IGNORE_OVERRIDES 100;
BA_ "GenSigCycleTime" SG_ 268 CLEAR_OVERRIDE 100;
BA_ "GenSigCycleTime" SG_ 268 DASH_CONTROLS_BUTTON 100;

// DASH_CONTROLS_LEFT_RPT ATTRIBUTES
BA_ "GenMsgCycleTime" BO_ 524 100;
BA_ "GenSigCycleTime" SG_ 524 ENABLED 100;
BA_ "GenSigCycleTime" SG_ 524 OVERRIDE_ACTIVE 100;
BA_ "GenSigCycleTime" SG_ 524 COMMAND_OUTPUT_FAULT 100;
BA_ "GenSigCycleTime" SG_ 524 INPUT_OUTPUT_FAULT 100;
BA_ "GenSigCycleTime" SG_ 524 OUTPUT_REPORTED_FAULT 100;
BA_ "GenSigCycleTime" SG_ 524 PACMOD_FAULT 100;
BA_ "GenSigCycleTime" SG_ 524 VEHICLE_FAULT 100;
BA_ "GenSigCycleTime" SG_ 524 COMMAND_TIMEOUT 100;
BA_ "GenSigCycleTime" SG_ 524 MANUAL_INPUT 100;
BA_ "GenSigCycleTime" SG_ 524 COMMANDED_VALUE 100;
BA_ "GenSigCycleTime" SG_ 524 OUTPUT_VALUE 100;

// DASH_CONTROLS_RIGHT_CMD ATTRIBUTES
BA_ "GenMsgCycleTime" BO_ 272 100;
BA_ "GenSigCycleTime" SG_ 272 ENABLE 100;
BA_ "GenSigCycleTime" SG_ 272 IGNORE_OVERRIDES 100;
BA_ "GenSigCycleTime" SG_ 272 CLEAR_OVERRIDE 100;
BA_ "GenSigCycleTime" SG_ 272 DASH_CONTROLS_BUTTON 100;

// DASH_CONTROLS_RIGHT_RPT ATTRIBUTES
BA_ "GenMsgCycleTime" BO_ 528 100;
BA_ "GenSigCycleTime" SG_ 528 ENABLED 100;
BA_ "GenSigCycleTime" SG_ 528 OVERRIDE_ACTIVE 100;
BA_ "GenSigCycleTime" SG_ 528 COMMAND_OUTPUT_FAULT 100;
BA_ "GenSigCycleTime" SG_ 528 INPUT_OUTPUT_FAULT 100;
BA_ "GenSigCycleTime" SG_ 528 OUTPUT_REPORTED_FAULT 100;
BA_ "GenSigCycleTime" SG_ 528 PACMOD_FAULT 100;
BA_ "GenSigCycleTime" SG_ 528 VEHICLE_FAULT 100;
BA_ "GenSigCycleTime" SG_ 528 COMMAND_TIMEOUT 100;
BA_ "GenSigCycleTime" SG_ 528 MANUAL_INPUT 100;
BA_ "GenSigCycleTime" SG_ 528 COMMANDED_VALUE 100;
BA_ "GenSigCycleTime" SG_ 528 OUTPUT_VALUE 100;

// DATE_TIME_RPT ATTRIBUTES
BA_ "GenMsgCycleTime" BO_ 1039 250;
BA_ "GenSigCycleTime" SG_ 1039 DATE_YEAR 250;
BA_ "GenSigCycleTime" SG_ 1039 DATE_MONTH 250;
BA_ "GenSigCycleTime" SG_ 1039 DATE_DAY 250;
BA_ "GenSigCycleTime" SG_ 1039 TIME_HOUR 250;
BA_ "GenSigCycleTime" SG_ 1039 TIME_MINUTE 250;
BA_ "GenSigCycleTime" SG_ 1039 TIME_SECOND 250;

// DOOR_RPT ATTRIBUTES
BA_ "GenMsgCycleTime" BO_ 1047 250;
BA_ "GenSigCycleTime" SG_ 1047 DRIVER_DOOR_OPEN 250;
BA_ "GenSigCycleTime" SG_ 1047 PASS_DOOR_OPEN 250;
BA_ "GenSigCycleTime" SG_ 1047 REAR_DRIVER_DOOR_OPEN 250;
BA_ "GenSigCycleTime" SG_ 1047 REAR_PASS_DOOR_OPEN 250;
BA_ "GenSigCycleTime" SG_ 1047 HOOD_OPEN 250;
BA_ "GenSigCycleTime" SG_ 1047 TRUNK_OPEN 250;
BA_ "GenSigCycleTime" SG_ 1047 FUEL_DOOR_OPEN 250;
BA_ "GenSigCycleTime" SG_ 1047 DRIVER_DOOR_OPEN_AVAIL 250;
BA_ "GenSigCycleTime" SG_ 1047 PASS_DOOR_OPEN_AVAIL 250;
BA_ "GenSigCycleTime" SG_ 1047 REAR_DRIVER_DOOR_OPEN_AVAIL 250;
BA_ "GenSigCycleTime" SG_ 1047 REAR_PASS_DOOR_OPEN_AVAIL 250;
BA_ "GenSigCycleTime" SG_ 1047 HOOD_OPEN_AVAIL 250;
BA_ "GenSigCycleTime" SG_ 1047 TRUNK_OPEN_AVAIL 250;
BA_ "GenSigCycleTime" SG_ 1047 FUEL_DOOR_OPEN_AVAIL 250;

// DRIVE_TRAIN_FEATURE_RPT ATTRIBUTES
BA_ "GenMsgCycleTime" BO_ 1055 100;
BA_ "GenSigCycleTime" SG_ 1055 ANTILOCK_BRAKE_ACTIVE 100;
BA_ "GenSigCycleTime" SG_ 1055 TRACTION_CONTROL_ACTIVE 100;
BA_ "GenSigCycleTime" SG_ 1055 FOUR_WHEEL_DRIVE_ACTIVE 100;
BA_ "GenSigCycleTime" SG_ 1055 ANTILOCK_BRAKE_DISABLED 100;
BA_ "GenSigCycleTime" SG_ 1055 ANTILOCK_BRAKE_ACTIVE_AVAIL 100;
BA_ "GenSigCycleTime" SG_ 1055 TRACTION_CONTROL_ACTIVE_AVAIL 100;
BA_ "GenSigCycleTime" SG_ 1055 FOUR_WHEEL_DRIVE_ACTIVE_AVAIL 100;
BA_ "GenSigCycleTime" SG_ 1055 ANTILOCK_BRAKE_DISABLED_AVAIL 100;
BA_ "GenSigCycleTime" SG_ 1055 DRIVE_MODE 100;
BA_ "GenSigCycleTime" SG_ 1055 DRIVE_MODE_AVAIL 100;
BA_ "GenSigCycleTime" SG_ 1055 TRACTION_CONTROL_DISABLED 100;
BA_ "GenSigCycleTime" SG_ 1055 TRACTION_CONTROL_DISABLED_AVAIL 100;

// ENGINE_CMD ATTRIBUTES
BA_ "GenMsgCycleTime" BO_ 360 100;
BA_ "GenSigCycleTime" SG_ 360 ENABLE 100;
BA_ "GenSigCycleTime" SG_ 360 IGNORE_OVERRIDES 100;
BA_ "GenSigCycleTime" SG_ 360 CLEAR_OVERRIDE 100;
BA_ "GenSigCycleTime" SG_ 360 ENGINE_CMD 100;

// ENGINE_RPT ATTRIBUTES
BA_ "GenMsgCycleTime" BO_ 616 100;
BA_ "GenSigCycleTime" SG_ 616 ENABLED 100;
BA_ "GenSigCycleTime" SG_ 616 OVERRIDE_ACTIVE 100;
BA_ "GenSigCycleTime" SG_ 616 COMMAND_OUTPUT_FAULT 100;
BA_ "GenSigCycleTime" SG_ 616 INPUT_OUTPUT_FAULT 100;
BA_ "GenSigCycleTime" SG_ 616 OUTPUT_REPORTED_FAULT 100;
BA_ "GenSigCycleTime" SG_ 616 PACMOD_FAULT 100;
BA_ "GenSigCycleTime" SG_ 616 VEHICLE_FAULT 100;
BA_ "GenSigCycleTime" SG_ 616 COMMAND_TIMEOUT 100;
BA_ "GenSigCycleTime" SG_ 616 MANUAL_INPUT 100;
BA_ "GenSigCycleTime" SG_ 616 COMMANDED_VALUE 100;
BA_ "GenSigCycleTime" SG_ 616 OUTPUT_VALUE 100;

// FIRE_SUPPRESSION_RPT ATTRIBUTES
BA_ "GenMsgCycleTime" BO_ 1042 100;
BA_ "GenSigCycleTime" SG_ 1042 FIRE_SUPPRESSION_ALARM_STATUS 100;

// GNSS_TIME ATTRIBUTES
BA_ "GenMsgCycleTime" BO_ 1082 1000;
BA_ "GenSigCycleTime" SG_ 1082 GNSS_TIMESTAMP 1000;

// HAZARD_LIGHTS_CMD ATTRIBUTES
BA_ "GenMsgCycleTime" BO_ 276 100;
BA_ "GenSigCycleTime" SG_ 276 ENABLE 100;
BA_ "GenSigCycleTime" SG_ 276 IGNORE_OVERRIDES 100;
BA_ "GenSigCycleTime" SG_ 276 CLEAR_OVERRIDE 100;
BA_ "GenSigCycleTime" SG_ 276 HAZARD_LIGHTS_CMD 100;

// HAZARD_LIGHTS_RPT ATTRIBUTES
BA_ "GenMsgCycleTime" BO_ 532 100;
BA_ "GenSigCycleTime" SG_ 532 ENABLED 100;
BA_ "GenSigCycleTime" SG_ 532 OVERRIDE_ACTIVE 100;
BA_ "GenSigCycleTime" SG_ 532 COMMAND_OUTPUT_FAULT 100;
BA_ "GenSigCycleTime" SG_ 532 INPUT_OUTPUT_FAULT 100;
BA_ "GenSigCycleTime" SG_ 532 OUTPUT_REPORTED_FAULT 100;
BA_ "GenSigCycleTime" SG_ 532 PACMOD_FAULT 100;
BA_ "GenSigCycleTime" SG_ 532 VEHICLE_FAULT 100;
BA_ "GenSigCycleTime" SG_ 532 COMMAND_TIMEOUT 100;
BA_ "GenSigCycleTime" SG_ 532 MANUAL_INPUT 100;
BA_ "GenSigCycleTime" SG_ 532 COMMANDED_VALUE 100;
BA_ "GenSigCycleTime" SG_ 532 OUTPUT_VALUE 100;

// HEADLIGHT_AUX_RPT ATTRIBUTES
BA_ "GenMsgCycleTime" BO_ 792 100;
BA_ "GenSigCycleTime" SG_ 792 HEADLIGHTS_ON 100;
BA_ "GenSigCycleTime" SG_ 792 HEADLIGHTS_ON_BRIGHT 100;
BA_ "GenSigCycleTime" SG_ 792 FOG_LIGHTS_ON 100;
BA_ "GenSigCycleTime" SG_ 792 HEADLIGHTS_MODE 100;
BA_ "GenSigCycleTime" SG_ 792 HEADLIGHTS_ON_AVAIL 100;
BA_ "GenSigCycleTime" SG_ 792 HEADLIGHTS_ON_BRIGHT_AVAIL 100;
BA_ "GenSigCycleTime" SG_ 792 FOG_LIGHTS_ON_AVAIL 100;
BA_ "GenSigCycleTime" SG_ 792 HEADLIGHTS_MODE_AVAIL 100;

// HEADLIGHT_CMD ATTRIBUTES
BA_ "GenMsgCycleTime" BO_ 280 100;
BA_ "GenSigCycleTime" SG_ 280 ENABLE 100;
BA_ "GenSigCycleTime" SG_ 280 IGNORE_OVERRIDES 100;
BA_ "GenSigCycleTime" SG_ 280 CLEAR_OVERRIDE 100;
BA_ "GenSigCycleTime" SG_ 280 HEADLIGHT_CMD 100;

// HEADLIGHT_RPT ATTRIBUTES
BA_ "GenMsgCycleTime" BO_ 536 100;
BA_ "GenSigCycleTime" SG_ 536 ENABLED 100;
BA_ "GenSigCycleTime" SG_ 536 OVERRIDE_ACTIVE 100;
BA_ "GenSigCycleTime" SG_ 536 COMMAND_OUTPUT_FAULT 100;
BA_ "GenSigCycleTime" SG_ 536 INPUT_OUTPUT_FAULT 100;
BA_ "GenSigCycleTime" SG_ 536 OUTPUT_REPORTED_FAULT 100;
BA_ "GenSigCycleTime" SG_ 536 PACMOD_FAULT 100;
BA_ "GenSigCycleTime" SG_ 536 VEHICLE_FAULT 100;
BA_ "GenSigCycleTime" SG_ 536 COMMAND_TIMEOUT 100;
BA_ "GenSigCycleTime" SG_ 536 MANUAL_INPUT 100;
BA_ "GenSigCycleTime" SG_ 536 COMMANDED_VALUE 100;
BA_ "GenSigCycleTime" SG_ 536 OUTPUT_VALUE 100;

// HORN_CMD ATTRIBUTES
BA_ "GenMsgCycleTime" BO_ 284 100;
BA_ "GenSigCycleTime" SG_ 284 ENABLE 100;
BA_ "GenSigCycleTime" SG_ 284 IGNORE_OVERRIDES 100;
BA_ "GenSigCycleTime" SG_ 284 CLEAR_OVERRIDE 100;
BA_ "GenSigCycleTime" SG_ 284 HORN_CMD 100;

// HORN_RPT ATTRIBUTES
BA_ "GenMsgCycleTime" BO_ 540 100;
BA_ "GenSigCycleTime" SG_ 540 ENABLED 100;
BA_ "GenSigCycleTime" SG_ 540 OVERRIDE_ACTIVE 100;
BA_ "GenSigCycleTime" SG_ 540 COMMAND_OUTPUT_FAULT 100;
BA_ "GenSigCycleTime" SG_ 540 INPUT_OUTPUT_FAULT 100;
BA_ "GenSigCycleTime" SG_ 540 OUTPUT_REPORTED_FAULT 100;
BA_ "GenSigCycleTime" SG_ 540 PACMOD_FAULT 100;
BA_ "GenSigCycleTime" SG_ 540 VEHICLE_FAULT 100;
BA_ "GenSigCycleTime" SG_ 540 COMMAND_TIMEOUT 100;
BA_ "GenSigCycleTime" SG_ 540 MANUAL_INPUT 100;
BA_ "GenSigCycleTime" SG_ 540 COMMANDED_VALUE 100;
BA_ "GenSigCycleTime" SG_ 540 OUTPUT_VALUE 100;

// INTERIOR_LIGHTS_RPT ATTRIBUTES
BA_ "GenMsgCycleTime" BO_ 1046 250;
BA_ "GenSigCycleTime" SG_ 1046 FRONT_DOME_LIGHTS_ON 250;
BA_ "GenSigCycleTime" SG_ 1046 REAR_DOME_LIGHTS_ON 250;
BA_ "GenSigCycleTime" SG_ 1046 MOOD_LIGHTS_ON 250;
BA_ "GenSigCycleTime" SG_ 1046 AMBIENT_LIGHT_SENSOR 250;
BA_ "GenSigCycleTime" SG_ 1046 DIM_LEVEL 250;
BA_ "GenSigCycleTime" SG_ 1046 FRONT_DOME_LIGHTS_ON_AVAIL 250;
BA_ "GenSigCycleTime" SG_ 1046 REAR_DOME_LIGHTS_ON_AVAIL 250;
BA_ "GenSigCycleTime" SG_ 1046 MOOD_LIGHTS_ON_AVAIL 250;
BA_ "GenSigCycleTime" SG_ 1046 DIM_LEVEL_AVAIL 250;
BA_ "GenSigCycleTime" SG_ 1046 AMBIENT_LIGHT_SENSOR_AVAIL 250;

// MARKER_LAMP_CMD ATTRIBUTES
BA_ "GenMsgCycleTime" BO_ 328 100;
BA_ "GenSigCycleTime" SG_ 328 ENABLE 100;
BA_ "GenSigCycleTime" SG_ 328 IGNORE_OVERRIDES 100;
BA_ "GenSigCycleTime" SG_ 328 CLEAR_OVERRIDE 100;
BA_ "GenSigCycleTime" SG_ 328 MARKER_LAMP_CMD 100;

// MARKER_LAMP_RPT ATTRIBUTES
BA_ "GenMsgCycleTime" BO_ 584 100;
BA_ "GenSigCycleTime" SG_ 584 ENABLED 100;
BA_ "GenSigCycleTime" SG_ 584 OVERRIDE_ACTIVE 100;
BA_ "GenSigCycleTime" SG_ 584 COMMAND_OUTPUT_FAULT 100;
BA_ "GenSigCycleTime" SG_ 584 INPUT_OUTPUT_FAULT 100;
BA_ "GenSigCycleTime" SG_ 584 OUTPUT_REPORTED_FAULT 100;
BA_ "GenSigCycleTime" SG_ 584 PACMOD_FAULT 100;
BA_ "GenSigCycleTime" SG_ 584 VEHICLE_FAULT 100;
BA_ "GenSigCycleTime" SG_ 584 COMMAND_TIMEOUT 100;
BA_ "GenSigCycleTime" SG_ 584 MANUAL_INPUT 100;
BA_ "GenSigCycleTime" SG_ 584 COMMANDED_VALUE 100;
BA_ "GenSigCycleTime" SG_ 584 OUTPUT_VALUE 100;

// MEDIA_CONTROLS_CMD ATTRIBUTES
BA_ "GenMsgCycleTime" BO_ 288 100;
BA_ "GenSigCycleTime" SG_ 288 ENABLE 100;
BA_ "GenSigCycleTime" SG_ 288 IGNORE_OVERRIDES 100;
BA_ "GenSigCycleTime" SG_ 288 CLEAR_OVERRIDE 100;
BA_ "GenSigCycleTime" SG_ 288 MEDIA_CONTROLS_CMD 100;

// MEDIA_CONTROLS_RPT ATTRIBUTES
BA_ "GenMsgCycleTime" BO_ 544 100;
BA_ "GenSigCycleTime" SG_ 544 ENABLED 100;
BA_ "GenSigCycleTime" SG_ 544 OVERRIDE_ACTIVE 100;
BA_ "GenSigCycleTime" SG_ 544 COMMAND_OUTPUT_FAULT 100;
BA_ "GenSigCycleTime" SG_ 544 INPUT_OUTPUT_FAULT 100;
BA_ "GenSigCycleTime" SG_ 544 OUTPUT_REPORTED_FAULT 100;
BA_ "GenSigCycleTime" SG_ 544 PACMOD_FAULT 100;
BA_ "GenSigCycleTime" SG_ 544 VEHICLE_FAULT 100;
BA_ "GenSigCycleTime" SG_ 544 COMMAND_TIMEOUT 100;
BA_ "GenSigCycleTime" SG_ 544 MANUAL_INPUT 100;
BA_ "GenSigCycleTime" SG_ 544 COMMANDED_VALUE 100;
BA_ "GenSigCycleTime" SG_ 544 OUTPUT_VALUE 100;

// NOTIFICATION_CMD ATTRIBUTES
BA_ "GenMsgCycleTime" BO_ 1051 250;
BA_ "GenSigCycleTime" SG_ 1051 BUZZER_MUTE 250;
BA_ "GenSigCycleTime" SG_ 1051 UNDERDASH_LIGHTS_WHITE 250;

// NOTIFICATION_RPT ATTRIBUTES
BA_ "GenMsgCycleTime" BO_ 1059 250;
BA_ "GenSigCycleTime" SG_ 1059 BUZZER_STATUS 250;
BA_ "GenSigCycleTime" SG_ 1059 LIGHT_STATUS 250;
BA_ "GenSigCycleTime" SG_ 1059 LIGHT_COLOR 250;

// OCCUPANCY_RPT ATTRIBUTES
BA_ "GenMsgCycleTime" BO_ 1045 250;
BA_ "GenSigCycleTime" SG_ 1045 DRIVER_SEAT_OCCUPIED 250;
BA_ "GenSigCycleTime" SG_ 1045 PASS_SEAT_OCCUPIED 250;
BA_ "GenSigCycleTime" SG_ 1045 REAR_SEAT_OCCUPIED 250;
BA_ "GenSigCycleTime" SG_ 1045 DRIVER_SEATBELT_BUCKLED 250;
BA_ "GenSigCycleTime" SG_ 1045 PASS_SEATBELT_BUCKLED 250;
BA_ "GenSigCycleTime" SG_ 1045 DRVR_REAR_SEATBELT_BUCKLED 250;
BA_ "GenSigCycleTime" SG_ 1045 PASS_REAR_SEATBELT_BUCKLED 250;
BA_ "GenSigCycleTime" SG_ 1045 CTR_REAR_SEATBELT_BUCKLED 250;
BA_ "GenSigCycleTime" SG_ 1045 DRIVER_SEAT_OCCUPIED_AVAIL 250;
BA_ "GenSigCycleTime" SG_ 1045 PASS_SEAT_OCCUPIED_AVAIL 250;
BA_ "GenSigCycleTime" SG_ 1045 REAR_SEAT_OCCUPIED_AVAIL 250;
BA_ "GenSigCycleTime" SG_ 1045 DRIVER_SEATBELT_BUCKLED_AVAIL 250;
BA_ "GenSigCycleTime" SG_ 1045 PASS_SEATBELT_BUCKLED_AVAIL 250;
BA_ "GenSigCycleTime" SG_ 1045 DRVR_REAR_SEATBELT_BUCKLED_AVAIL 250;
BA_ "GenSigCycleTime" SG_ 1045 PASS_REAR_SEATBELT_BUCKLED_AVAIL 250;
BA_ "GenSigCycleTime" SG_ 1045 CTR_REAR_SEATBELT_BUCKLED_AVAIL 250;

// PARKING_BRAKE_AUX_RPT ATTRIBUTES
BA_ "GenMsgCycleTime" BO_ 804 100;
BA_ "GenSigCycleTime" SG_ 804 PARKING_BRAKE_STATUS 100;
BA_ "GenSigCycleTime" SG_ 804 PARKING_BRAKE_STATUS_AVAIL 100;

// PARKING_BRAKE_CMD ATTRIBUTES
BA_ "GenMsgCycleTime" BO_ 292 100;
BA_ "GenSigCycleTime" SG_ 292 ENABLE 100;
BA_ "GenSigCycleTime" SG_ 292 IGNORE_OVERRIDES 100;
BA_ "GenSigCycleTime" SG_ 292 CLEAR_OVERRIDE 100;
BA_ "GenSigCycleTime" SG_ 292 PARKING_BRAKE_CMD 100;

// PARKING_BRAKE_RPT ATTRIBUTES
BA_ "GenMsgCycleTime" BO_ 548 100;
BA_ "GenSigCycleTime" SG_ 548 ENABLED 100;
BA_ "GenSigCycleTime" SG_ 548 OVERRIDE_ACTIVE 100;
BA_ "GenSigCycleTime" SG_ 548 COMMAND_OUTPUT_FAULT 100;
BA_ "GenSigCycleTime" SG_ 548 INPUT_OUTPUT_FAULT 100;
BA_ "GenSigCycleTime" SG_ 548 OUTPUT_REPORTED_FAULT 100;
BA_ "GenSigCycleTime" SG_ 548 PACMOD_FAULT 100;
BA_ "GenSigCycleTime" SG_ 548 VEHICLE_FAULT 100;
BA_ "GenSigCycleTime" SG_ 548 COMMAND_TIMEOUT 100;
BA_ "GenSigCycleTime" SG_ 548 MANUAL_INPUT 100;
BA_ "GenSigCycleTime" SG_ 548 COMMANDED_VALUE 100;
BA_ "GenSigCycleTime" SG_ 548 OUTPUT_VALUE 100;
BA_ "GenSigCycleTime" SG_ 548 CONTROL_STATUS 100;
BA_ "GenSigCycleTime" SG_ 548 CONTROLLING_SYSTEMS 100;
BA_ "GenSigCycleTime" SG_ 548 PERFORMANCE_STATUS 100;
BA_ "GenSigCycleTime" SG_ 548 SELF_TEST_STATUS 100;

// PARKING_BRAKE_RPT_2 ATTRIBUTES
BA_ "GenMsgCycleTime" BO_ 550 100;
BA_ "GenSigCycleTime" SG_ 550 ENABLED 100;
BA_ "GenSigCycleTime" SG_ 550 OVERRIDE_ACTIVE 100;
BA_ "GenSigCycleTime" SG_ 550 COMMAND_OUTPUT_FAULT 100;
BA_ "GenSigCycleTime" SG_ 550 INPUT_OUTPUT_FAULT 100;
BA_ "GenSigCycleTime" SG_ 550 OUTPUT_REPORTED_FAULT 100;
BA_ "GenSigCycleTime" SG_ 550 PACMOD_FAULT 100;
BA_ "GenSigCycleTime" SG_ 550 VEHICLE_FAULT 100;
BA_ "GenSigCycleTime" SG_ 550 COMMAND_TIMEOUT 100;
BA_ "GenSigCycleTime" SG_ 550 MANUAL_INPUT 100;
BA_ "GenSigCycleTime" SG_ 550 COMMANDED_VALUE 100;
BA_ "GenSigCycleTime" SG_ 550 OUTPUT_VALUE 100;
BA_ "GenSigCycleTime" SG_ 550 CONTROL_STATUS 100;
BA_ "GenSigCycleTime" SG_ 550 CONTROLLING_SYSTEMS 100;
BA_ "GenSigCycleTime" SG_ 550 PERFORMANCE_STATUS 100;
BA_ "GenSigCycleTime" SG_ 550 SELF_TEST_STATUS 100;

// POWER_TAKE_OFF_CMD ATTRIBUTES
BA_ "GenMsgCycleTime" BO_ 348 100;
BA_ "GenSigCycleTime" SG_ 348 ENABLE 100;
BA_ "GenSigCycleTime" SG_ 348 IGNORE_OVERRIDES 100;
BA_ "GenSigCycleTime" SG_ 348 CLEAR_OVERRIDE 100;
BA_ "GenSigCycleTime" SG_ 348 POWER_TAKE_OFF_CMD 100;

// POWER_TAKE_OFF_RPT ATTRIBUTES
BA_ "GenMsgCycleTime" BO_ 604 100;
BA_ "GenSigCycleTime" SG_ 604 ENABLED 100;
BA_ "GenSigCycleTime" SG_ 604 OVERRIDE_ACTIVE 100;
BA_ "GenSigCycleTime" SG_ 604 COMMAND_OUTPUT_FAULT 100;
BA_ "GenSigCycleTime" SG_ 604 INPUT_OUTPUT_FAULT 100;
BA_ "GenSigCycleTime" SG_ 604 OUTPUT_REPORTED_FAULT 100;
BA_ "GenSigCycleTime" SG_ 604 PACMOD_FAULT 100;
BA_ "GenSigCycleTime" SG_ 604 VEHICLE_FAULT 100;
BA_ "GenSigCycleTime" SG_ 604 COMMAND_TIMEOUT 100;
BA_ "GenSigCycleTime" SG_ 604 MANUAL_INPUT 100;
BA_ "GenSigCycleTime" SG_ 604 COMMANDED_VALUE 100;
BA_ "GenSigCycleTime" SG_ 604 OUTPUT_VALUE 100;

// REAR_LIGHTS_RPT ATTRIBUTES
BA_ "GenMsgCycleTime" BO_ 1048 250;
BA_ "GenSigCycleTime" SG_ 1048 BRAKE_LIGHTS_ON 250;
BA_ "GenSigCycleTime" SG_ 1048 REVERSE_LIGHTS_ON 250;
BA_ "GenSigCycleTime" SG_ 1048 BRAKE_LIGHTS_ON_AVAIL 250;
BA_ "GenSigCycleTime" SG_ 1048 REVERSE_LIGHTS_ON_AVAIL 250;

// REAR_PASS_DOOR_CMD ATTRIBUTES
BA_ "GenMsgCycleTime" BO_ 320 100;
BA_ "GenSigCycleTime" SG_ 320 ENABLE 100;
BA_ "GenSigCycleTime" SG_ 320 IGNORE_OVERRIDES 100;
BA_ "GenSigCycleTime" SG_ 320 CLEAR_OVERRIDE 100;
BA_ "GenSigCycleTime" SG_ 320 REAR_PASS_DOOR_CMD 100;

// REAR_PASS_DOOR_RPT ATTRIBUTES
BA_ "GenMsgCycleTime" BO_ 576 100;
BA_ "GenSigCycleTime" SG_ 576 ENABLED 100;
BA_ "GenSigCycleTime" SG_ 576 OVERRIDE_ACTIVE 100;
BA_ "GenSigCycleTime" SG_ 576 COMMAND_OUTPUT_FAULT 100;
BA_ "GenSigCycleTime" SG_ 576 INPUT_OUTPUT_FAULT 100;
BA_ "GenSigCycleTime" SG_ 576 OUTPUT_REPORTED_FAULT 100;
BA_ "GenSigCycleTime" SG_ 576 PACMOD_FAULT 100;
BA_ "GenSigCycleTime" SG_ 576 VEHICLE_FAULT 100;
BA_ "GenSigCycleTime" SG_ 576 COMMAND_TIMEOUT 100;
BA_ "GenSigCycleTime" SG_ 576 MANUAL_INPUT 100;
BA_ "GenSigCycleTime" SG_ 576 COMMANDED_VALUE 100;
BA_ "GenSigCycleTime" SG_ 576 OUTPUT_VALUE 100;

// SAFETY_FUNC_CRITICAL_STOP_RPT ATTRIBUTES
BA_ "GenMsgCycleTime" BO_ 1056 1000;
BA_ "GenSigCycleTime" SG_ 1056 AUTOMS_MAN_OPCTRL_FAULT 1000;
BA_ "GenSigCycleTime" SG_ 1056 REMOTE_STOP_FAULT 1000;
BA_ "GenSigCycleTime" SG_ 1056 SAFETY_BRAKE_OPCTRL_OFF 1000;
BA_ "GenSigCycleTime" SG_ 1056 SAFETY_BRAKE_CMD_TIMEOUT 1000;
BA_ "GenSigCycleTime" SG_ 1056 SAFETY_FUNC_CMD_TIMEOUT 1000;
BA_ "GenSigCycleTime" SG_ 1056 SAFETY_FUNC_CRITICAL_STOP_1_CMD 1000;
BA_ "GenSigCycleTime" SG_ 1056 SAFETY_FUNC_CRITICAL_STOP_2_CMD 1000;
BA_ "GenSigCycleTime" SG_ 1056 SAFETY_FUNC_NONE_CMD 1000;
BA_ "GenSigCycleTime" SG_ 1056 PACMOD_SYSTEM_TIMEOUT 1000;
BA_ "GenSigCycleTime" SG_ 1056 PACMOD_SYSTEM_FAULT 1000;
BA_ "GenSigCycleTime" SG_ 1056 PACMOD_SYSTEM_NOT_ACTIVE 1000;
BA_ "GenSigCycleTime" SG_ 1056 VEHICLE_REPORT_TIMEOUT 1000;
BA_ "GenSigCycleTime" SG_ 1056 VEHICLE_REPORT_FAULT 1000;
BA_ "GenSigCycleTime" SG_ 1056 LOW_ENGINE_RPM 1000;
BA_ "GenSigCycleTime" SG_ 1056 PRI_SAFETY_BRAKE_SIGNAL_1_FAULT 1000;
BA_ "GenSigCycleTime" SG_ 1056 PRI_SAFETY_BRAKE_SIGNAL_2_FAULT 1000;
BA_ "GenSigCycleTime" SG_ 1056 SEC_SAFETY_BRAKE_SIGNAL_1_FAULT 1000;
BA_ "GenSigCycleTime" SG_ 1056 SEC_SAFETY_BRAKE_SIGNAL_2_FAULT 1000;
BA_ "GenSigCycleTime" SG_ 1056 PRIMARY_PROCESSOR_FAULT 1000;
BA_ "GenSigCycleTime" SG_ 1056 SECONDARY_PROCESSOR_FAULT 1000;
BA_ "GenSigCycleTime" SG_ 1056 REMOTE_STOP_CMD 1000;
BA_ "GenSigCycleTime" SG_ 1056 PRI_SAFETY_BRAKE_PRESSURE_FAULT 1000;

///////////////////////////////
//                           //
//   Signal Values Section   //
//                           //
///////////////////////////////
// ACCEL_AUX_RPT VALUES
VAL_ 768 OPERATOR_INTERACTION 0 "NO_INTERACTION" 1 "INTERACTION";
VAL_ 768 ACCEL_LIMITING_ACTIVE 0 "NOT_ACTIVE" 1 "ACTIVE";
VAL_ 768 PRK_BRK_INTERLOCK_ACTIVE 0 "NOT_ACTIVE" 1 "ACTIVE";
VAL_ 768 BRAKE_INTERLOCK_ACTIVE 0 "NOT_ACTIVE" 1 "ACTIVE";
VAL_ 768 CALIBRATION_STATUS 0 "INACTIVE" 1 "ACTIVE" 2 "COMPLETE" 3 "ERROR" ;
VAL_ 768 OPERATOR_INTERACTION_AVAIL 0 "NOT_AVAILABLE" 1 "AVAILABLE" ;
VAL_ 768 ACCEL_LIMITING_ACTIVE_AVAIL 0 "NOT_AVAILABLE" 1 "AVAILABLE" ;
VAL_ 768 PRK_BRK_INTERLOCK_ACTIVE_AVAIL 0 "NOT_AVAILABLE" 1 "AVAILABLE" ;
VAL_ 768 BRAKE_INTERLOCK_ACTIVE_AVAIL 0 "NOT_AVAILABLE" 1 "AVAILABLE" ;

// ACCEL_CMD VALUES
VAL_ 256 ENABLE 0 "DISABLE" 1 "ENABLE" ;
VAL_ 256 IGNORE_OVERRIDES 0 "FALSE" 1 "TRUE" ;
VAL_ 256 CLEAR_OVERRIDE 0 "FALSE" 1 "TRUE" ;

// ACCEL_RPT VALUES
VAL_ 512 ENABLED 0 "FALSE" 1 "TRUE" ;
VAL_ 512 OVERRIDE_ACTIVE 0 "FALSE" 1 "TRUE" ;
VAL_ 512 COMMAND_OUTPUT_FAULT 0 "NO_FAULT" 1 "FAULT" ;
VAL_ 512 INPUT_OUTPUT_FAULT 0 "NO_FAULT" 1 "FAULT" ;
VAL_ 512 OUTPUT_REPORTED_FAULT 0 "NO_FAULT" 1 "FAULT" ;
VAL_ 512 PACMOD_FAULT 0 "NO_FAULT" 1 "FAULT" ;
VAL_ 512 VEHICLE_FAULT 0 "NO_FAULT" 1 "FAULT" ;
VAL_ 512 COMMAND_TIMEOUT 0 "NO_TIMEOUT" 1 "TIMEOUT" ;
VAL_ 512 MANUAL_INPUT 65531 "RESERVED" 65532 "RESERVED" 65533 "RESERVED" 65534 "ERROR" 65535 "NOT_AVAIL" ;
VAL_ 512 COMMANDED_VALUE 65531 "RESERVED" 65532 "RESERVED" 65533 "RESERVED" 65534 "ERROR" 65535 "NOT_AVAIL" ;
VAL_ 512 OUTPUT_VALUE 65531 "RESERVED" 65532 "RESERVED" 65533 "RESERVED" 65534 "ERROR" 65535 "NOT_AVAIL" ;
VAL_ 512 CONTROL_STATUS 0 "SAFE" 1 "AVAILABLE" ;
VAL_ 512 PERFORMANCE_STATUS 0 "NONE" 1 "CMD_TRACKING_FAILURE" 2 "APPOACHING_OPERATIONAL_LIMITS" 3 "LIMITING_ACTIVE" 4 "LIMITING_IMMINENT" ;

// AMBIENT_CONDITION_RPT VALUES
VAL_ 1094 INTERIOR_AMBIENT_TEMP 251 "RESERVED" 252 "RESERVED" 253 "RESERVED" 254 "ERROR" 255 "NOT_AVAIL" ;
VAL_ 1094 INTERIOR_AMBIENT_TEMP_WARNING 0 "NONE" 1 "EXCESSIVE_TEMP" 2 "ERROR" 3 "NOT_AVAIL" ;

// AIR_PRESSURE_RPT VALUES
VAL_ 1060 PNEUMATIC_SUPPLY_PRESSURE 251 "RESERVED" 252 "RESERVED" 253 "RESERVED" 254 "ERROR" 255 "NOT_AVAIL";
VAL_ 1060 BRAKE_CIRCUIT_1_PRESSURE 251 "RESERVED" 252 "RESERVED" 253 "RESERVED" 254 "ERROR" 255 "NOT_AVAIL";
VAL_ 1060 BRAKE_CIRCUIT_2_PRESSURE 251 "RESERVED" 252 "RESERVED" 253 "RESERVED" 254 "ERROR" 255 "NOT_AVAIL";
VAL_ 1060 PARK_TRAILER_AIR_PRESSURE 251 "RESERVED" 252 "RESERVED" 253 "RESERVED" 254 "ERROR" 255 "NOT_AVAIL";
VAL_ 1060 POWERTRAIN_AIR_PRESSURE 251 "RESERVED" 252 "RESERVED" 253 "RESERVED" 254 "ERROR" 255 "NOT_AVAIL";
VAL_ 1060 AIR_COMPRESSOR_STATUS 0 "NOT_ACTIVE" 1 "ACTIVE" 2 "ERROR" 3 "NOT_AVAIL";
VAL_ 1060 PNEUMATIC_SUPPLY_PRESSURE_AVAIL 0 "NOT_AVAILABLE" 1 "AVAILABLE";
VAL_ 1060 BRAKE_CIRCUIT_1_PRESSURE_AVAIL 0 "NOT_AVAILABLE" 1 "AVAILABLE";
VAL_ 1060 BRAKE_CIRCUIT_2_PRESSURE_AVAIL 0 "NOT_AVAILABLE" 1 "AVAILABLE";
VAL_ 1060 PARK_TRAILER_AIR_PRESSURE_AVAIL 0 "NOT_AVAILABLE" 1 "AVAILABLE";
VAL_ 1060 POWERTRAIN_AIR_PRESSURE_AVAIL 0 "NOT_AVAILABLE" 1 "AVAILABLE";
VAL_ 1060 AIR_COMPRESSOR_STATUS_AVAIL 0 "NOT_AVAILABLE" 1 "AVAILABLE";

// ANG_VEL_RPT VALUES
VAL_ 1050 PITCH_NEW_DATA_RX 0 "NEW_DATA_NOT_RX" 1 "NEW_DATA_RX" ;
VAL_ 1050 ROLL_NEW_DATA_RX 0 "NEW_DATA_NOT_RX" 1 "NEW_DATA_RX" ;
VAL_ 1050 YAW_NEW_DATA_RX 0 "NEW_DATA_NOT_RX" 1 "NEW_DATA_RX" ;
VAL_ 1050 PITCH_VALID 0 "NOT_VALID" 1 "VALID" ;
VAL_ 1050 ROLL_VALID 0 "NOT_VALID" 1 "VALID" ;
VAL_ 1050 YAW_VALID 0 "NOT_VALID" 1 "VALID" ;

// AUTOMS_MAN_SWITCH_RPT VALUES
VAL_ 1077 AUTOMS_MAN_OPCTRL 0 "INVALID" 1 "MANUAL" 2 "AUTOMS" ;
VAL_ 1077 AUTOMS_MAN_EXTCTRL 0 "INVALID" 1 "MANUAL" 2 "AUTOMS" ;
VAL_ 1077 AUTOMS_MAN_OPCTRL_AVAIL 0 "NOT_AVAILABLE" 1 "AVAILABLE" ;
VAL_ 1077 AUTOMS_MAN_EXTCTRL_AVAIL 0 "NOT_AVAILABLE" 1 "AVAILABLE" ;

//BATTERY_VOLTAGE_LEVEL_RPT_1 VALUES
VAL_ 1070 BATTERY_VOLTAGE_1 251 "RESERVED" 252 "RESERVED" 253 "RESERVED" 254 "ERROR" 255 "NOT_AVAIL" ;
VAL_ 1070 BATTERY_VOLTAGE_2 251 "RESERVED" 252 "RESERVED" 253 "RESERVED" 254 "ERROR" 255 "NOT_AVAIL" ;

//BATTERY_VOLTAGE_LEVEL_RPT_2 VALUES
VAL_ 1081 BATTERY_VOLTAGE_1 251 "RESERVED" 252 "RESERVED" 253 "RESERVED" 254 "ERROR" 255 "NOT_AVAIL" ;
VAL_ 1081 BATTERY_VOLTAGE_2 251 "RESERVED" 252 "RESERVED" 253 "RESERVED" 254 "ERROR" 255 "NOT_AVAIL" ;

// BRAKE_AUX_RPT VALUES
VAL_ 772 BRAKE_PRESSURE_2 65531 "RESERVED" 65532 "RESERVED" 65533 "RESERVED" 65534 "ERROR" 65535 "NOT_AVAIL";
VAL_ 772 BRAKE_PRESSURE 65531 "RESERVED" 65532 "RESERVED" 65533 "RESERVED" 65534 "ERROR" 65535 "NOT_AVAIL";
VAL_ 772 OPERATOR_INTERACTION 0 "NO_INTERACTION" 1 "INTERACTION";
VAL_ 772 BRAKE_ON_OFF 0 "OFF" 1 "ON" ;
VAL_ 772 BRAKE_LIMITING_ACTIVE 0 "NOT_ACTIVE" 1 "ACTIVE" ;
VAL_ 772 BRAKE_REDUCED_ASSIST 0 "NOT_REDUCED" 1 "REDUCED" ;
VAL_ 772 CALIBRATION_STATUS 0 "INACTIVE" 1 "ACTIVE" 2 "COMPLETE" 3 "ERROR" ;
VAL_ 772 BRAKE_PRESSURE_2_AVAIL 0 "NOT_AVAILABLE" 1 "AVAILABLE" ;
VAL_ 772 BRAKE_PRESSURE_AVAIL 0 "NOT_AVAILABLE" 1 "AVAILABLE" ;
VAL_ 772 OPERATOR_INTERACTION_AVAIL 0 "NOT_AVAILABLE" 1 "AVAILABLE" ;
VAL_ 772 BRAKE_ON_OFF_AVAIL 0 "NOT_AVAILABLE" 1 "AVAILABLE" ;
VAL_ 772 BRAKE_LIMITING_ACTIVE_AVAIL 0 "NOT_AVAILABLE" 1 "AVAILABLE" ;
VAL_ 772 BRAKE_REDUCED_ASSIST_AVAIL 0 "NOT_AVAILABLE" 1 "AVAILABLE" ;

// BRAKE_AUX_RPT_2 VALUES
VAL_ 774 BRAKE_PRESSURE_2 65531 "RESERVED" 65532 "RESERVED" 65533 "RESERVED" 65534 "ERROR" 65535 "NOT_AVAIL";
VAL_ 774 BRAKE_PRESSURE 65531 "RESERVED" 65532 "RESERVED" 65533 "RESERVED" 65534 "ERROR" 65535 "NOT_AVAIL";
VAL_ 774 OPERATOR_INTERACTION 0 "NO_INTERACTION" 1 "INTERACTION";
VAL_ 774 BRAKE_ON_OFF 0 "OFF" 1 "ON" ;
VAL_ 774 BRAKE_LIMITING_ACTIVE 0 "NOT_ACTIVE" 1 "ACTIVE" ;
VAL_ 774 BRAKE_REDUCED_ASSIST 0 "NOT_REDUCED" 1 "REDUCED" ;
VAL_ 774 CALIBRATION_STATUS 0 "INACTIVE" 1 "ACTIVE" 2 "COMPLETE" 3 "ERROR" ;
VAL_ 774 BRAKE_PRESSURE_2_AVAIL 0 "NOT_AVAILABLE" 1 "AVAILABLE" ;
VAL_ 774 BRAKE_PRESSURE_AVAIL 0 "NOT_AVAILABLE" 1 "AVAILABLE" ;
VAL_ 774 OPERATOR_INTERACTION_AVAIL 0 "NOT_AVAILABLE" 1 "AVAILABLE" ;
VAL_ 774 BRAKE_ON_OFF_AVAIL 0 "NOT_AVAILABLE" 1 "AVAILABLE" ;
VAL_ 774 BRAKE_LIMITING_ACTIVE_AVAIL 0 "NOT_AVAILABLE" 1 "AVAILABLE" ;
VAL_ 774 BRAKE_REDUCED_ASSIST_AVAIL 0 "NOT_AVAILABLE" 1 "AVAILABLE" ;

// BRAKE_CMD VALUES
VAL_ 260 ENABLE 0 "DISABLE" 1 "ENABLE" ;
VAL_ 260 IGNORE_OVERRIDES 0 "FALSE" 1 "TRUE" ;
VAL_ 260 CLEAR_OVERRIDE 0 "FALSE" 1 "TRUE" ;

// BRAKE_DECEL_AUX_RPT VALUES
VAL_ 824 XBR_ACTIVE_CONTROL_MODE 0 "NO_BRAKE_DEMAND" 1 "DRIVERS_BRAKE_DEMAND" 2 "ADDITION_MODE_OF_XBR_ACCEL_CTRL" 3 "MAXIMUM_MODE_OF_XBR_ACCEL_CTRL";
VAL_ 824 XBR_SYSTEM_STATE 0 "ANY_EXT_BRK_DEMAND_WILL_BE_ACPTD" 2 "NO_EXT_BRK_DEMAND_WILL_BE_ACPTD";
VAL_ 824 FOUNDATION_BRAKE_USE 0 "FOUNDATION_BRAKES_NOT_IN_USE" 1 "FOUNDATION_BRAKES_IN_USE";
VAL_ 824 HILL_HOLDER_MODE 0 "INACTIVE" 1 "ACTIVE" 2 "ACTIVE_BUT_INACTIVE_SOON" 6 "ERROR";
VAL_ 824 XBR_ACTIVE_CONTROL_MODE_AVAIL 0 "NOT_AVAILABLE" 1 "AVAILABLE" ;
VAL_ 824 XBR_SYSTEM_STATE_AVAIL 0 "NOT_AVAILABLE" 1 "AVAILABLE" ;
VAL_ 824 FOUNDATION_BRAKE_USE_AVAIL 0 "NOT_AVAILABLE" 1 "AVAILABLE" ;
VAL_ 824 HILL_HOLDER_MODE_AVAIL 0 "NOT_AVAILABLE" 1 "AVAILABLE" ;

// BRAKE_DECEL_CMD VALUES
VAL_ 316 ENABLE 0 "DISABLE" 1 "ENABLE" ;
VAL_ 316 IGNORE_OVERRIDES 0 "FALSE" 1 "TRUE" ;
VAL_ 316 CLEAR_OVERRIDE 0 "FALSE" 1 "TRUE" ;
VAL_ 316 XBR_EBI_MODE 0 "NO_ENDURANCE_BRK_INTGN_ALLOWED" 1 "ONLY_ENDURANCE_BRAKES_ALLOWED" 2 "ENDURANCE_BRK_INTGRN_ALLOWED";
VAL_ 316 XBR_PRIORITY 0 "HIGHEST_PRIORITY" 1 "HIGH_PRIORITY" 2 "MEDIUM_PRIORITY" 3 "LOW_PRIORITY";
VAL_ 316 XBR_CONTROL_MODE 0 "OVERRIDE_DISABLE" 1 "ACCEL_CONTROL_WITH_ADDITION_MODE" 2 "ACCEL_CONTROL_WITH_MAXIMUM_MODE";

// BRAKE_DECEL_RPT VALUES
VAL_ 572 ENABLED 0 "FALSE" 1 "TRUE" ;
VAL_ 572 OVERRIDE_ACTIVE 0 "FALSE" 1 "TRUE" ;
VAL_ 572 COMMAND_OUTPUT_FAULT 0 "NO_FAULT" 1 "FAULT" ;
VAL_ 572 INPUT_OUTPUT_FAULT 0 "NO_FAULT" 1 "FAULT" ;
VAL_ 572 OUTPUT_REPORTED_FAULT 0 "NO_FAULT" 1 "FAULT" ;
VAL_ 572 PACMOD_FAULT 0 "NO_FAULT" 1 "FAULT" ;
VAL_ 572 VEHICLE_FAULT 0 "NO_FAULT" 1 "FAULT" ;
VAL_ 572 COMMAND_TIMEOUT 0 "NO_TIMEOUT" 1 "TIMEOUT" ;

// BRAKE_RPT VALUES
VAL_ 516 ENABLED 0 "FALSE" 1 "TRUE" ;
VAL_ 516 OVERRIDE_ACTIVE 0 "FALSE" 1 "TRUE" ;
VAL_ 516 COMMAND_OUTPUT_FAULT 0 "NO_FAULT" 1 "FAULT" ;
VAL_ 516 INPUT_OUTPUT_FAULT 0 "NO_FAULT" 1 "FAULT" ;
VAL_ 516 OUTPUT_REPORTED_FAULT 0 "NO_FAULT" 1 "FAULT" ;
VAL_ 516 PACMOD_FAULT 0 "NO_FAULT" 1 "FAULT" ;
VAL_ 516 VEHICLE_FAULT 0 "NO_FAULT" 1 "FAULT" ;
VAL_ 516 COMMAND_TIMEOUT 0 "NO_TIMEOUT" 1 "TIMEOUT" ;
VAL_ 516 MANUAL_INPUT 65531 "RESERVED" 65532 "RESERVED" 65533 "RESERVED" 65534 "ERROR" 65535 "NOT_AVAIL" ;
VAL_ 516 COMMANDED_VALUE 65531 "RESERVED" 65532 "RESERVED" 65533 "RESERVED" 65534 "ERROR" 65535 "NOT_AVAIL" ;
VAL_ 516 OUTPUT_VALUE 65531 "RESERVED" 65532 "RESERVED" 65533 "RESERVED" 65534 "ERROR" 65535 "NOT_AVAIL" ;
VAL_ 516 CONTROL_STATUS 0 "SAFE" 1 "AVAILABLE" ;
VAL_ 516 PERFORMANCE_STATUS 0 "NONE" 1 "CMD_TRACKING_FAILURE" 2 "APPOACHING_OPERATIONAL_LIMITS" 3 "LIMITING_ACTIVE" 4 "LIMITING_IMMINENT" ;
VAL_ 516 SELF_TEST_STATUS 0 "NOT_RUNNING" 1 "IN_PROGRESS" 2 "ERROR" 3 "NOT_AVAIL" ;

// BRAKE_RPT_2 VALUES
VAL_ 518 ENABLED 0 "FALSE" 1 "TRUE" ;
VAL_ 518 OVERRIDE_ACTIVE 0 "FALSE" 1 "TRUE" ;
VAL_ 518 COMMAND_OUTPUT_FAULT 0 "NO_FAULT" 1 "FAULT" ;
VAL_ 518 INPUT_OUTPUT_FAULT 0 "NO_FAULT" 1 "FAULT" ;
VAL_ 518 OUTPUT_REPORTED_FAULT 0 "NO_FAULT" 1 "FAULT" ;
VAL_ 518 PACMOD_FAULT 0 "NO_FAULT" 1 "FAULT" ;
VAL_ 518 VEHICLE_FAULT 0 "NO_FAULT" 1 "FAULT" ;
VAL_ 518 COMMAND_TIMEOUT 0 "NO_TIMEOUT" 1 "TIMEOUT" ;
VAL_ 518 MANUAL_INPUT 65531 "RESERVED" 65532 "RESERVED" 65533 "RESERVED" 65534 "ERROR" 65535 "NOT_AVAIL" ;
VAL_ 518 COMMANDED_VALUE 65531 "RESERVED" 65532 "RESERVED" 65533 "RESERVED" 65534 "ERROR" 65535 "NOT_AVAIL" ;
VAL_ 518 OUTPUT_VALUE 65531 "RESERVED" 65532 "RESERVED" 65533 "RESERVED" 65534 "ERROR" 65535 "NOT_AVAIL" ;
VAL_ 518 CONTROL_STATUS 0 "SAFE" 1 "AVAILABLE" ;
VAL_ 518 PERFORMANCE_STATUS 0 "NONE" 1 "CMD_TRACKING_FAILURE" 2 "APPOACHING_OPERATIONAL_LIMITS" 3 "LIMITING_ACTIVE" 4 "LIMITING_IMMINENT" ;
VAL_ 518 SELF_TEST_STATUS 0 "NOT_RUNNING" 1 "IN_PROGRESS" 2 "ERROR" 3 "NOT_AVAIL" ;

// CABIN_CLIMATE_CMD VALUES
VAL_ 340 ENABLE 0 "DISABLE" 1 "ENABLE" ;
VAL_ 340 IGNORE_OVERRIDES 0 "FALSE" 1 "TRUE" ;
VAL_ 340 CLEAR_OVERRIDE 0 "FALSE" 1 "TRUE" ;
VAL_ 340 CMD_AC_OFF_ON 0 "OFF" 1 "ON" ;
VAL_ 340 CMD_MAX_AC_OFF_ON 0 "OFF" 1 "ON" ;
VAL_ 340 CMD_DEFROST_OFF_ON 0 "OFF" 1 "ON" ;
VAL_ 340 CMD_MAX_DEFROST_OFF_ON 0 "OFF" 1 "ON" ;
VAL_ 340 CMD_DIR_UP_OFF_ON 0 "OFF" 1 "ON" ;
VAL_ 340 CMD_DIR_DOWN_OFF_ON 0 "OFF" 1 "ON" ;

// CABIN_CLIMATE_RPT VALUES
VAL_ 596 ENABLED 0 "FALSE" 1 "TRUE" ;
VAL_ 596 OVERRIDE_ACTIVE 0 "FALSE" 1 "TRUE" ;
VAL_ 596 COMMAND_OUTPUT_FAULT 0 "NO_FAULT" 1 "FAULT" ;
VAL_ 596 INPUT_OUTPUT_FAULT 0 "NO_FAULT" 1 "FAULT" ;
VAL_ 596 OUTPUT_REPORTED_FAULT 0 "NO_FAULT" 1 "FAULT" ;
VAL_ 596 PACMOD_FAULT 0 "NO_FAULT" 1 "FAULT" ;
VAL_ 596 VEHICLE_FAULT 0 "NO_FAULT" 1 "FAULT" ;
VAL_ 596 COMMAND_TIMEOUT 0 "NO_TIMEOUT" 1 "TIMEOUT" ;
VAL_ 596 MAN_AC_OFF_ON 0 "OFF" 1 "ON" 2 "ERROR" 3 "NOT_AVAIL" ;
VAL_ 596 MAN_MAX_AC_OFF_ON 0 "OFF" 1 "ON" 2 "ERROR" 3 "NOT_AVAIL" ;
VAL_ 596 MAN_DEFROST_OFF_ON 0 "OFF" 1 "ON" 2 "ERROR" 3 "NOT_AVAIL" ;
VAL_ 596 MAN_MAX_DEFROST_OFF_ON 0 "OFF" 1 "ON" 2 "ERROR" 3 "NOT_AVAIL" ;
VAL_ 596 MAN_DIR_UP_OFF_ON 0 "OFF" 1 "ON" 2 "ERROR" 3 "NOT_AVAIL" ;
VAL_ 596 MAN_DIR_DOWN_OFF_ON 0 "OFF" 1 "ON" 2 "ERROR" 3 "NOT_AVAIL" ;
VAL_ 596 CMD_AC_OFF_ON 0 "OFF" 1 "ON" 2 "ERROR" 3 "NOT_AVAIL" ;
VAL_ 596 CMD_MAX_AC_OFF_ON 0 "OFF" 1 "ON" 2 "ERROR" 3 "NOT_AVAIL" ;
VAL_ 596 CMD_DEFROST_OFF_ON 0 "OFF" 1 "ON" 2 "ERROR" 3 "NOT_AVAIL" ;
VAL_ 596 CMD_MAX_DEFROST_OFF_ON 0 "OFF" 1 "ON" 2 "ERROR" 3 "NOT_AVAIL" ;
VAL_ 596 CMD_DIR_UP_OFF_ON 0 "OFF" 1 "ON" 2 "ERROR" 3 "NOT_AVAIL" ;
VAL_ 596 CMD_DIR_DOWN_OFF_ON 0 "OFF" 1 "ON" 2 "ERROR" 3 "NOT_AVAIL" ;
VAL_ 596 OUT_AC_OFF_ON 0 "OFF" 1 "ON" 2 "ERROR" 3 "NOT_AVAIL" ;
VAL_ 596 OUT_MAX_AC_OFF_ON 0 "OFF" 1 "ON" 2 "ERROR" 3 "NOT_AVAIL" ;
VAL_ 596 OUT_DEFROST_OFF_ON 0 "OFF" 1 "ON" 2 "ERROR" 3 "NOT_AVAIL" ;
VAL_ 596 OUT_MAX_DEFROST_OFF_ON 0 "OFF" 1 "ON" 2 "ERROR" 3 "NOT_AVAIL" ;
VAL_ 596 OUT_DIR_UP_OFF_ON 0 "OFF" 1 "ON" 2 "ERROR" 3 "NOT_AVAIL" ;
VAL_ 596 OUT_DIR_DOWN_OFF_ON 0 "OFF" 1 "ON" 2 "ERROR" 3 "NOT_AVAIL" ;

// CABIN_FAN_SPEED_CMD VALUES
VAL_ 336 ENABLE 0 "DISABLE" 1 "ENABLE" ;
VAL_ 336 IGNORE_OVERRIDES 0 "FALSE" 1 "TRUE" ;
VAL_ 336 CLEAR_OVERRIDE 0 "FALSE" 1 "TRUE" ;
VAL_ 336 CABIN_FAN_SPEED_CMD 0 "FAN_OFF" 1 "FAN_SPEED_1" 2 "FAN_SPEED_2" 3 "FAN_SPEED_3" 4 "FAN_SPEED_4" 5 "FAN_SPEED_5" 6 "FAN_SPEED_6" 7 "FAN_SPEED_7" 8 "FAN_SPEED_8" 9 "FAN_SPEED_9" 10 "FAN_SPEED_10" ;

// CABIN_FAN_SPEED_RPT VALUES
VAL_ 592 ENABLED 0 "FALSE" 1 "TRUE" ;
VAL_ 592 OVERRIDE_ACTIVE 0 "FALSE" 1 "TRUE" ;
VAL_ 592 COMMAND_OUTPUT_FAULT 0 "NO_FAULT" 1 "FAULT" ;
VAL_ 592 INPUT_OUTPUT_FAULT 0 "NO_FAULT" 1 "FAULT" ;
VAL_ 592 OUTPUT_REPORTED_FAULT 0 "NO_FAULT" 1 "FAULT" ;
VAL_ 592 PACMOD_FAULT 0 "NO_FAULT" 1 "FAULT" ;
VAL_ 592 VEHICLE_FAULT 0 "NO_FAULT" 1 "FAULT" ;
VAL_ 592 COMMAND_TIMEOUT 0 "NO_TIMEOUT" 1 "TIMEOUT" ;
VAL_ 592 MANUAL_INPUT 0 "FAN_OFF" 1 "FAN_SPEED_1" 2 "FAN_SPEED_2" 3 "FAN_SPEED_3" 4 "FAN_SPEED_4" 5 "FAN_SPEED_5" 6 "FAN_SPEED_6" 7 "FAN_SPEED_7" 8 "FAN_SPEED_8" 9 "FAN_SPEED_9" 10 "FAN_SPEED_10" 251 "RESERVED" 252 "RESERVED" 253 "RESERVED" 254 "ERROR" 255 "NOT_AVAIL" ;
VAL_ 592 COMMANDED_VALUE 0 "FAN_OFF" 1 "FAN_SPEED_1" 2 "FAN_SPEED_2" 3 "FAN_SPEED_3" 4 "FAN_SPEED_4" 5 "FAN_SPEED_5" 6 "FAN_SPEED_6" 7 "FAN_SPEED_7" 8 "FAN_SPEED_8" 9 "FAN_SPEED_9" 10 "FAN_SPEED_10" 251 "RESERVED" 252 "RESERVED" 253 "RESERVED" 254 "ERROR" 255 "NOT_AVAIL" ;
VAL_ 592 OUTPUT_VALUE 0 "FAN_OFF" 1 "FAN_SPEED_1" 2 "FAN_SPEED_2" 3 "FAN_SPEED_3" 4 "FAN_SPEED_4" 5 "FAN_SPEED_5" 6 "FAN_SPEED_6" 7 "FAN_SPEED_7" 8 "FAN_SPEED_8" 9 "FAN_SPEED_9" 10 "FAN_SPEED_10" 251 "RESERVED" 252 "RESERVED" 253 "RESERVED" 254 "ERROR" 255 "NOT_AVAIL" ;

// CABIN_TEMP_CMD VALUES
VAL_ 332 ENABLE 0 "DISABLE" 1 "ENABLE" ;
VAL_ 332 IGNORE_OVERRIDES 0 "FALSE" 1 "TRUE" ;
VAL_ 332 CLEAR_OVERRIDE 0 "FALSE" 1 "TRUE" ;

// CABIN_TEMP_RPT VALUES
VAL_ 588 ENABLED 0 "FALSE" 1 "TRUE" ;
VAL_ 588 OVERRIDE_ACTIVE 0 "FALSE" 1 "TRUE" ;
VAL_ 588 COMMAND_OUTPUT_FAULT 0 "NO_FAULT" 1 "FAULT" ;
VAL_ 588 INPUT_OUTPUT_FAULT 0 "NO_FAULT" 1 "FAULT" ;
VAL_ 588 OUTPUT_REPORTED_FAULT 0 "NO_FAULT" 1 "FAULT" ;
VAL_ 588 PACMOD_FAULT 0 "NO_FAULT" 1 "FAULT" ;
VAL_ 588 VEHICLE_FAULT 0 "NO_FAULT" 1 "FAULT" ;
VAL_ 588 COMMAND_TIMEOUT 0 "NO_TIMEOUT" 1 "TIMEOUT" ;
VAL_ 588 MANUAL_INPUT 254 "ERROR" 255 "NOT_AVAIL" ;
VAL_ 588 COMMANDED_VALUE 254 "ERROR" 255 "NOT_AVAIL" ;
VAL_ 588 OUTPUT_VALUE 254 "ERROR" 255 "NOT_AVAIL" ;

// COMPONENT_AUX_RPT_00 VALUES
VAL_ 1100 LOCATION_CODE 0 "LOCATION_0" 1 "LOCATION_1" 2 "LOCATION_2" 3 "LOCATION_3" 4 "LOCATION_4" 5 "LOCATION_5" 6 "LOCATION_6" 7 "LOCATION_7" 14 "ERROR" 15 "NOT_AVAIL" ;
VAL_ 1100 KEY_SWITCH_STATUS 0 "OFF" 1 "ON" 2 "ERROR" 3 "NOT_AVAIL" ;

// COMPONENT_AUX_RPT_00 VALUES
VAL_ 1101 LOCATION_CODE 0 "LOCATION_0" 1 "LOCATION_1" 2 "LOCATION_2" 3 "LOCATION_3" 4 "LOCATION_4" 5 "LOCATION_5" 6 "LOCATION_6" 7 "LOCATION_7" 14 "ERROR" 15 "NOT_AVAIL" ;
VAL_ 1101 KEY_SWITCH_STATUS 0 "OFF" 1 "ON" 2 "ERROR" 3 "NOT_AVAIL" ;

// COMPONENT_AUX_RPT_00 VALUES
VAL_ 1102 LOCATION_CODE 0 "LOCATION_0" 1 "LOCATION_1" 2 "LOCATION_2" 3 "LOCATION_3" 4 "LOCATION_4" 5 "LOCATION_5" 6 "LOCATION_6" 7 "LOCATION_7" 14 "ERROR" 15 "NOT_AVAIL" ;
VAL_ 1102 KEY_SWITCH_STATUS 0 "OFF" 1 "ON" 2 "ERROR" 3 "NOT_AVAIL" ;

// COMPONENT_AUX_RPT_00 VALUES
VAL_ 1103 LOCATION_CODE 0 "LOCATION_0" 1 "LOCATION_1" 2 "LOCATION_2" 3 "LOCATION_3" 4 "LOCATION_4" 5 "LOCATION_5" 6 "LOCATION_6" 7 "LOCATION_7" 14 "ERROR" 15 "NOT_AVAIL" ;
VAL_ 1103 KEY_SWITCH_STATUS 0 "OFF" 1 "ON" 2 "ERROR" 3 "NOT_AVAIL" ;

// COMPONENT_AUX_RPT_00 VALUES
VAL_ 1104 LOCATION_CODE 0 "LOCATION_0" 1 "LOCATION_1" 2 "LOCATION_2" 3 "LOCATION_3" 4 "LOCATION_4" 5 "LOCATION_5" 6 "LOCATION_6" 7 "LOCATION_7" 14 "ERROR" 15 "NOT_AVAIL" ;
VAL_ 1104 KEY_SWITCH_STATUS 0 "OFF" 1 "ON" 2 "ERROR" 3 "NOT_AVAIL" ;

// COMPONENT_AUX_RPT_00 VALUES
VAL_ 1105 LOCATION_CODE 0 "LOCATION_0" 1 "LOCATION_1" 2 "LOCATION_2" 3 "LOCATION_3" 4 "LOCATION_4" 5 "LOCATION_5" 6 "LOCATION_6" 7 "LOCATION_7" 14 "ERROR" 15 "NOT_AVAIL" ;
VAL_ 1105 KEY_SWITCH_STATUS 0 "OFF" 1 "ON" 2 "ERROR" 3 "NOT_AVAIL" ;

// COMPONENT_RPT_00 VALUES
VAL_ 32 CONFIG_FAULT 0 "NO_FAULT" 1 "FAULT" 2 "NOT_USED" 3 "NOT_AVAIL";
VAL_ 32 INTERNAL_SUPPLY_VOLTAGE_FAULT 0 "NO_FAULT" 1 "FAULT" 2 "NOT_USED" 3 "NOT_AVAIL";
VAL_ 32 WATCHDOG_SANITY_FAULT 0 "NO_FAULT" 1 "FAULT" 2 "NOT_USED" 3 "NOT_AVAIL";
VAL_ 32 COMPONENT_READY 0 "NOT_READY" 1 "READY" 2 "ERROR" 3 "NOT_AVAIL";
VAL_ 32 SYSTEM_ENABLED  0 "DISABLED" 1 "ENABLED" 2 "ERROR" 3 "NOT_AVAIL";
VAL_ 32 SYSTEM_OVERRIDE_ACTIVE 0 "NOT_OVERRIDDEN" 1 "OVERRIDDEN" 2 "ERROR" 3 "NOT_AVAIL";
VAL_ 32 SYSTEM_FAULT_ACTIVE 0 "NO_FAULT" 1 "FAULT" 2 "NOT_USED" 3 "NOT_AVAIL";
VAL_ 32 USER_PC_HEALTH_FAULT_00 0 "OKAY" 1 "FAULT" 2 "NOT_USED" 3 "NOT_AVAIL" ;
VAL_ 32 USER_PC_HEALTH_FAULT_01 0 "OKAY" 1 "FAULT" 2 "NOT_USED" 3 "NOT_AVAIL" ;
VAL_ 32 STATE 0 "NONE" 1 "AUTOMS_READY" 2 "AUTOMS" 3 "MANUAL_READY" 4 "MANUAL" 5 "STARTUP" ;

// COMPONENT_RPT_01 VALUES
VAL_ 33 CONFIG_FAULT 0 "NO_FAULT" 1 "FAULT" 2 "NOT_USED" 3 "NOT_AVAIL";
VAL_ 33 INTERNAL_SUPPLY_VOLTAGE_FAULT 0 "NO_FAULT" 1 "FAULT" 2 "NOT_USED" 3 "NOT_AVAIL";
VAL_ 33 WATCHDOG_SANITY_FAULT 0 "NO_FAULT" 1 "FAULT" 2 "NOT_USED" 3 "NOT_AVAIL";
VAL_ 33 COMPONENT_READY 0 "NOT_READY" 1 "READY" 2 "ERROR" 3 "NOT_AVAIL";
VAL_ 33 SYSTEM_ENABLED  0 "DISABLED" 1 "ENABLED" 2 "ERROR" 3 "NOT_AVAIL";
VAL_ 33 SYSTEM_OVERRIDE_ACTIVE 0 "NOT_OVERRIDDEN" 1 "OVERRIDDEN" 2 "ERROR" 3 "NOT_AVAIL";
VAL_ 33 SYSTEM_FAULT_ACTIVE 0 "NO_FAULT" 1 "FAULT" 2 "NOT_USED" 3 "NOT_AVAIL";
VAL_ 33 USER_PC_HEALTH_FAULT_00 0 "OKAY" 1 "FAULT" 2 "NOT_USED" 3 "NOT_AVAIL" ;
VAL_ 33 USER_PC_HEALTH_FAULT_01 0 "OKAY" 1 "FAULT" 2 "NOT_USED" 3 "NOT_AVAIL" ;
VAL_ 33 STATE 0 "NONE" 1 "AUTOMS_READY" 2 "AUTOMS" 3 "MANUAL_READY" 4 "MANUAL" 5 "STARTUP" ;

// COMPONENT_RPT_02 VALUES
VAL_ 34 CONFIG_FAULT 0 "NO_FAULT" 1 "FAULT" 2 "NOT_USED" 3 "NOT_AVAIL";
VAL_ 34 INTERNAL_SUPPLY_VOLTAGE_FAULT 0 "NO_FAULT" 1 "FAULT" 2 "NOT_USED" 3 "NOT_AVAIL";
VAL_ 34 WATCHDOG_SANITY_FAULT 0 "NO_FAULT" 1 "FAULT" 2 "NOT_USED" 3 "NOT_AVAIL";
VAL_ 34 COMPONENT_READY 0 "NOT_READY" 1 "READY" 2 "ERROR" 3 "NOT_AVAIL";
VAL_ 34 SYSTEM_ENABLED  0 "DISABLED" 1 "ENABLED" 2 "ERROR" 3 "NOT_AVAIL";
VAL_ 34 SYSTEM_OVERRIDE_ACTIVE 0 "NOT_OVERRIDDEN" 1 "OVERRIDDEN" 2 "ERROR" 3 "NOT_AVAIL";
VAL_ 34 SYSTEM_FAULT_ACTIVE 0 "NO_FAULT" 1 "FAULT" 2 "NOT_USED" 3 "NOT_AVAIL";
VAL_ 34 USER_PC_HEALTH_FAULT_00 0 "OKAY" 1 "FAULT" 2 "NOT_USED" 3 "NOT_AVAIL" ;
VAL_ 34 USER_PC_HEALTH_FAULT_01 0 "OKAY" 1 "FAULT" 2 "NOT_USED" 3 "NOT_AVAIL" ;
VAL_ 34 STATE 0 "NONE" 1 "AUTOMS_READY" 2 "AUTOMS" 3 "MANUAL_READY" 4 "MANUAL" 5 "STARTUP"  ;

// COMPONENT_RPT_03 VALUES
VAL_ 35 CONFIG_FAULT 0 "NO_FAULT" 1 "FAULT" 2 "NOT_USED" 3 "NOT_AVAIL";
VAL_ 35 INTERNAL_SUPPLY_VOLTAGE_FAULT 0 "NO_FAULT" 1 "FAULT" 2 "NOT_USED" 3 "NOT_AVAIL";
VAL_ 35 WATCHDOG_SANITY_FAULT 0 "NO_FAULT" 1 "FAULT" 2 "NOT_USED" 3 "NOT_AVAIL";
VAL_ 35 COMPONENT_READY 0 "NOT_READY" 1 "READY" 2 "ERROR" 3 "NOT_AVAIL";
VAL_ 35 SYSTEM_ENABLED  0 "DISABLED" 1 "ENABLED" 2 "ERROR" 3 "NOT_AVAIL";
VAL_ 35 SYSTEM_OVERRIDE_ACTIVE 0 "NOT_OVERRIDDEN" 1 "OVERRIDDEN" 2 "ERROR" 3 "NOT_AVAIL";
VAL_ 35 SYSTEM_FAULT_ACTIVE 0 "NO_FAULT" 1 "FAULT" 2 "NOT_USED" 3 "NOT_AVAIL";
VAL_ 35 USER_PC_HEALTH_FAULT_00 0 "OKAY" 1 "FAULT" 2 "NOT_USED" 3 "NOT_AVAIL" ;
VAL_ 35 USER_PC_HEALTH_FAULT_01 0 "OKAY" 1 "FAULT" 2 "NOT_USED" 3 "NOT_AVAIL" ;
VAL_ 35 STATE 0 "NONE" 1 "AUTOMS_READY" 2 "AUTOMS" 3 "MANUAL_READY" 4 "MANUAL" 5 "STARTUP" ;

// COMPONENT_RPT_04 VALUES
VAL_ 36 CONFIG_FAULT 0 "NO_FAULT" 1 "FAULT" 2 "NOT_USED" 3 "NOT_AVAIL";
VAL_ 36 INTERNAL_SUPPLY_VOLTAGE_FAULT 0 "NO_FAULT" 1 "FAULT" 2 "NOT_USED" 3 "NOT_AVAIL";
VAL_ 36 WATCHDOG_SANITY_FAULT 0 "NO_FAULT" 1 "FAULT" 2 "NOT_USED" 3 "NOT_AVAIL";
VAL_ 36 COMPONENT_READY 0 "NOT_READY" 1 "READY" 2 "ERROR" 3 "NOT_AVAIL";
VAL_ 36 SYSTEM_ENABLED  0 "DISABLED" 1 "ENABLED" 2 "ERROR" 3 "NOT_AVAIL";
VAL_ 36 SYSTEM_OVERRIDE_ACTIVE 0 "NOT_OVERRIDDEN" 1 "OVERRIDDEN" 2 "ERROR" 3 "NOT_AVAIL";
VAL_ 36 SYSTEM_FAULT_ACTIVE 0 "NO_FAULT" 1 "FAULT" 2 "NOT_USED" 3 "NOT_AVAIL";
VAL_ 36 USER_PC_HEALTH_FAULT_00 0 "OKAY" 1 "FAULT" 2 "NOT_USED" 3 "NOT_AVAIL" ;
VAL_ 36 USER_PC_HEALTH_FAULT_01 0 "OKAY" 1 "FAULT" 2 "NOT_USED" 3 "NOT_AVAIL" ;
VAL_ 36 STATE 0 "NONE" 1 "AUTOMS_READY" 2 "AUTOMS" 3 "MANUAL_READY" 4 "MANUAL" 5 "STARTUP" ;

// COMPONENT_RPT_05 VALUES
VAL_ 39 CONFIG_FAULT 0 "NO_FAULT" 1 "FAULT" 2 "NOT_USED" 3 "NOT_AVAIL";
VAL_ 39 INTERNAL_SUPPLY_VOLTAGE_FAULT 0 "NO_FAULT" 1 "FAULT" 2 "NOT_USED" 3 "NOT_AVAIL";
VAL_ 39 WATCHDOG_SANITY_FAULT 0 "NO_FAULT" 1 "FAULT" 2 "NOT_USED" 3 "NOT_AVAIL";
VAL_ 39 COMPONENT_READY 0 "NOT_READY" 1 "READY" 2 "ERROR" 3 "NOT_AVAIL";
VAL_ 39 SYSTEM_ENABLED  0 "DISABLED" 1 "ENABLED" 2 "ERROR" 3 "NOT_AVAIL";
VAL_ 39 SYSTEM_OVERRIDE_ACTIVE 0 "NOT_OVERRIDDEN" 1 "OVERRIDDEN" 2 "ERROR" 3 "NOT_AVAIL";
VAL_ 39 SYSTEM_FAULT_ACTIVE 0 "NO_FAULT" 1 "FAULT" 2 "NOT_USED" 3 "NOT_AVAIL";
VAL_ 39 USER_PC_HEALTH_FAULT_00 0 "OKAY" 1 "FAULT" 2 "NOT_USED" 3 "NOT_AVAIL" ;
VAL_ 39 USER_PC_HEALTH_FAULT_01 0 "OKAY" 1 "FAULT" 2 "NOT_USED" 3 "NOT_AVAIL" ;
VAL_ 39 STATE 0 "NONE" 1 "AUTOMS_READY" 2 "AUTOMS" 3 "MANUAL_READY" 4 "MANUAL" 5 "STARTUP" ;

// CRUISE_CONTROL_BUTTONS_CMD
VAL_ 264 ENABLE 0 "DISABLE" 1 "ENABLE" ;
VAL_ 264 IGNORE_OVERRIDES 0 "FALSE" 1 "TRUE" ;
VAL_ 264 CLEAR_OVERRIDE 0 "FALSE" 1 "TRUE" ;
VAL_ 264 CRUISE_CONTROL_BUTTON 7 "CRUISE_CONTROL_LIM" 6 "CRUISE_CONTROL_ON_OFF" 5 "CRUISE_CONTROL_RES_INC" 4 "CRUISE_CONTROL_SET_DEC" 3 "CRUISE_CONTROL_ACC_CLOSER" 2 "CRUISE_CONTROL_ACC_FURTHER" 1 "CRUISE_CONTROL_CNCL" 0 "CRUISE_CONTROL_NONE" ;

// CRUISE_CONTROL_BUTTONS_RPT
VAL_ 520 ENABLED 0 "FALSE" 1 "TRUE" ;
VAL_ 520 OVERRIDE_ACTIVE 0 "FALSE" 1 "TRUE" ;
VAL_ 520 COMMAND_OUTPUT_FAULT 0 "NO_FAULT" 1 "FAULT" ;
VAL_ 520 INPUT_OUTPUT_FAULT 0 "NO_FAULT" 1 "FAULT" ;
VAL_ 520 OUTPUT_REPORTED_FAULT 0 "NO_FAULT" 1 "FAULT" ;
VAL_ 520 PACMOD_FAULT 0 "NO_FAULT" 1 "FAULT" ;
VAL_ 520 VEHICLE_FAULT 0 "NO_FAULT" 1 "FAULT" ;
VAL_ 520 COMMAND_TIMEOUT 0 "NO_TIMEOUT" 1 "TIMEOUT" ;
VAL_ 520 MANUAL_INPUT 0 "CRUISE_CONTROL_NONE" 1 "CRUISE_CONTROL_CNCL" 2 "CRUISE_CONTROL_ACC_FURTHER" 3 "CRUISE_CONTROL_ACC_CLOSER" 4 "CRUISE_CONTROL_SET_DEC" 5 "CRUISE_CONTROL_RES_INC" 6 "CRUISE_CONTROL_ON_OFF" 7 "CRUISE_CONTROL_LIM" 251 "RESERVED" 252 "RESERVED" 253 "RESERVED" 254 "ERROR" 255 "NOT_AVAIL" ;
VAL_ 520 COMMANDED_VALUE 0 "CRUISE_CONTROL_NONE" 1 "CRUISE_CONTROL_CNCL" 2 "CRUISE_CONTROL_ACC_FURTHER" 3 "CRUISE_CONTROL_ACC_CLOSER" 4 "CRUISE_CONTROL_SET_DEC" 5 "CRUISE_CONTROL_RES_INC" 6 "CRUISE_CONTROL_ON_OFF" 7 "CRUISE_CONTROL_LIM" 251 "RESERVED" 252 "RESERVED" 253 "RESERVED" 254 "ERROR" 255 "NOT_AVAIL" ;
VAL_ 520 OUTPUT_VALUE 0 "CRUISE_CONTROL_NONE" 1 "CRUISE_CONTROL_CNCL" 2 "CRUISE_CONTROL_ACC_FURTHER" 3 "CRUISE_CONTROL_ACC_CLOSER" 4 "CRUISE_CONTROL_SET_DEC" 5 "CRUISE_CONTROL_RES_INC" 6 "CRUISE_CONTROL_ON_OFF" 7 "CRUISE_CONTROL_LIM" 251 "RESERVED" 252 "RESERVED" 253 "RESERVED" 254 "ERROR" 255 "NOT_AVAIL" ;

// DASH_CONTROLS_LEFT_CMD VALUES
VAL_ 268 ENABLE 0 "DISABLE" 1 "ENABLE" ;
VAL_ 268 IGNORE_OVERRIDES 0 "FALSE" 1 "TRUE" ;
VAL_ 268 CLEAR_OVERRIDE 0 "FALSE" 1 "TRUE" ;
VAL_ 268 DASH_CONTROLS_BUTTON 5 "DASH_CONTROL_DOWN" 4 "DASH_CONTROL_UP" 3 "DASH_CONTROL_RIGHT" 2 "DASH_CONTROL_LEFT" 1 "DASH_CONTROL_OK" 0 "DASH_CONTROL_NONE" ;

// DASH_CONTROLS_LEFT_RPT VALUES
VAL_ 524 ENABLED 0 "FALSE" 1 "TRUE" ;
VAL_ 524 OVERRIDE_ACTIVE 0 "FALSE" 1 "TRUE" ;
VAL_ 524 COMMAND_OUTPUT_FAULT 0 "NO_FAULT" 1 "FAULT" ;
VAL_ 524 INPUT_OUTPUT_FAULT 0 "NO_FAULT" 1 "FAULT" ;
VAL_ 524 OUTPUT_REPORTED_FAULT 0 "NO_FAULT" 1 "FAULT" ;
VAL_ 524 PACMOD_FAULT 0 "NO_FAULT" 1 "FAULT" ;
VAL_ 524 VEHICLE_FAULT 0 "NO_FAULT" 1 "FAULT" ;
VAL_ 524 COMMAND_TIMEOUT 0 "NO_TIMEOUT" 1 "TIMEOUT" ;
VAL_ 524 MANUAL_INPUT 0 "DASH_CONTROL_NONE" 1 "DASH_CONTROL_OK" 2 "DASH_CONTROL_LEFT" 3 "DASH_CONTROL_RIGHT" 4 "DASH_CONTROL_UP" 5 "DASH_CONTROL_DOWN" 251 "RESERVED" 252 "RESERVED" 253 "RESERVED" 254 "ERROR" 255 "NOT_AVAIL" ;
VAL_ 524 COMMANDED_VALUE 0 "DASH_CONTROL_NONE" 1 "DASH_CONTROL_OK" 2 "DASH_CONTROL_LEFT" 3 "DASH_CONTROL_RIGHT" 4 "DASH_CONTROL_UP" 5 "DASH_CONTROL_DOWN" 251 "RESERVED" 252 "RESERVED" 253 "RESERVED" 254 "ERROR" 255 "NOT_AVAIL" ;
VAL_ 524 OUTPUT_VALUE 0 "DASH_CONTROL_NONE" 1 "DASH_CONTROL_OK" 2 "DASH_CONTROL_LEFT" 3 "DASH_CONTROL_RIGHT" 4 "DASH_CONTROL_UP" 5 "DASH_CONTROL_DOWN" 251 "RESERVED" 252 "RESERVED" 253 "RESERVED" 254 "ERROR" 255 "NOT_AVAIL" ;

// DASH_CONTROLS_RIGHT_CMD VALUES
VAL_ 272 ENABLE 0 "DISABLE" 1 "ENABLE" ;
VAL_ 272 IGNORE_OVERRIDES 0 "FALSE" 1 "TRUE" ;
VAL_ 272 CLEAR_OVERRIDE 0 "FALSE" 1 "TRUE" ;
VAL_ 272 DASH_CONTROLS_BUTTON 5 "DASH_CONTROL_DOWN" 4 "DASH_CONTROL_UP" 3 "DASH_CONTROL_RIGHT" 2 "DASH_CONTROL_LEFT" 1 "DASH_CONTROL_OK" 0 "DASH_CONTROL_NONE" ;

// DASH_CONTROLS_RIGHT_RPT VALUES
VAL_ 528 ENABLED 0 "FALSE" 1 "TRUE" ;
VAL_ 528 OVERRIDE_ACTIVE 0 "FALSE" 1 "TRUE" ;
VAL_ 528 COMMAND_OUTPUT_FAULT 0 "NO_FAULT" 1 "FAULT" ;
VAL_ 528 INPUT_OUTPUT_FAULT 0 "NO_FAULT" 1 "FAULT" ;
VAL_ 528 OUTPUT_REPORTED_FAULT 0 "NO_FAULT" 1 "FAULT" ;
VAL_ 528 PACMOD_FAULT 0 "NO_FAULT" 1 "FAULT" ;
VAL_ 528 VEHICLE_FAULT 0 "NO_FAULT" 1 "FAULT" ;
VAL_ 528 COMMAND_TIMEOUT 0 "NO_TIMEOUT" 1 "TIMEOUT" ;
VAL_ 528 MANUAL_INPUT 0 "DASH_CONTROL_NONE" 1 "DASH_CONTROL_OK" 2 "DASH_CONTROL_LEFT" 3 "DASH_CONTROL_RIGHT" 4 "DASH_CONTROL_UP" 5 "DASH_CONTROL_DOWN" 251 "RESERVED" 252 "RESERVED" 253 "RESERVED" 254 "ERROR" 255 "NOT_AVAIL" ;
VAL_ 528 COMMANDED_VALUE 0 "DASH_CONTROL_NONE" 1 "DASH_CONTROL_OK" 2 "DASH_CONTROL_LEFT" 3 "DASH_CONTROL_RIGHT" 4 "DASH_CONTROL_UP" 5 "DASH_CONTROL_DOWN" 251 "RESERVED" 252 "RESERVED" 253 "RESERVED" 254 "ERROR" 255 "NOT_AVAIL" ;
VAL_ 528 OUTPUT_VALUE 0 "DASH_CONTROL_NONE" 1 "DASH_CONTROL_OK" 2 "DASH_CONTROL_LEFT" 3 "DASH_CONTROL_RIGHT" 4 "DASH_CONTROL_UP" 5 "DASH_CONTROL_DOWN" 251 "RESERVED" 252 "RESERVED" 253 "RESERVED" 254 "ERROR" 255 "NOT_AVAIL" ;

// DBW_HEALTH_RPT_00 VALUES
VAL_ 40 USER_CAN_NTWRK_INTEGRITY_FAULT 0 "OK" 1 "FAULT" 2 "NOT_USED" 3 "NOT_AVAIL" ;
VAL_ 40 SELF_TEST_STATUS 0 "NOT_RUNNING" 1 "IN_PROGRESS" 2 "SUCCESS" 3 "RESERVED" 4 "RESERVED" 5 "RESERVED" 6 "ERROR" 7 "NOT_AVAIL" ;

// DBW_HEALTH_RPT_01 VALUES
VAL_ 41 BACKUP_CAN_NTWRK_INTEGRITY_FAULT 0 "OK" 1 "FAULT" 2 "NOT_USED" 3 "NOT_AVAIL" ;
VAL_ 41 SELF_TEST_STATUS 0 "NOT_RUNNING" 1 "IN_PROGRESS" 2 "SUCCESS" 3 "RESERVED" 4 "RESERVED" 5 "RESERVED" 6 "ERROR" 7 "NOT_AVAIL" ;

// DIFFERENTIAL_LOCKS_CMD VALUES
VAL_ 372 ENABLE 0 "DISABLE" 1 "ENABLE" ;
VAL_ 372 IGNORE_OVERRIDES 0 "FALSE" 1 "TRUE" ;
VAL_ 372 CLEAR_OVERRIDE 0 "FALSE" 1 "TRUE" ;
VAL_ 372 FRONT_LOCK_CMD 0 "LOCK_OFF"  1 "LOCK_ON" 2 "ERROR" 3 "NOT_AVAIL" ;
VAL_ 372 CENTER_LOCK_CMD 0 "LOCK_OFF"  1 "LOCK_ON" 2 "ERROR" 3 "NOT_AVAIL" ;
VAL_ 372 REAR_LOCK_CMD 0 "LOCK_OFF"  1 "LOCK_ON" 2 "ERROR" 3 "NOT_AVAIL" ;

// DIFFERENTIAL_LOCKS_RPT VALUES
VAL_ 628 ENABLED 0 "FALSE" 1 "TRUE" ;
VAL_ 628 OVERRIDE_ACTIVE 0 "FALSE" 1 "TRUE" ;
VAL_ 628 COMMAND_OUTPUT_FAULT 0 "NO_FAULT" 1 "FAULT" ;
VAL_ 628 INPUT_OUTPUT_FAULT 0 "NO_FAULT" 1 "FAULT" ;
VAL_ 628 OUTPUT_REPORTED_FAULT 0 "NO_FAULT" 1 "FAULT" ;
VAL_ 628 PACMOD_FAULT 0 "NO_FAULT" 1 "FAULT" ;
VAL_ 628 VEHICLE_FAULT 0 "NO_FAULT" 1 "FAULT" ;
VAL_ 628 COMMAND_TIMEOUT 0 "NO_TIMEOUT" 1 "TIMEOUT" ;
VAL_ 628 MAN_FRONT_LOCK 0 "LOCK_OFF"  1 "LOCK_ON" 2 "ERROR" 3 "NOT_AVAIL" ;
VAL_ 628 MAN_CENTER_LOCK 0 "LOCK_OFF"  1 "LOCK_ON" 2 "ERROR" 3 "NOT_AVAIL" ;
VAL_ 628 MAN_REAR_LOCK 0 "LOCK_OFF"  1 "LOCK_ON" 2 "ERROR" 3 "NOT_AVAIL" ;
VAL_ 628 CMD_FRONT_LOCK 0 "LOCK_OFF"  1 "LOCK_ON" 2 "ERROR" 3 "NOT_AVAIL" ;
VAL_ 628 CMD_CENTER_LOCK 0 "LOCK_OFF"  1 "LOCK_ON" 2 "ERROR" 3 "NOT_AVAIL" ;
VAL_ 628 CMD_REAR_LOCK 0 "LOCK_OFF"  1 "LOCK_ON" 2 "ERROR" 3 "NOT_AVAIL" ;
VAL_ 628 OUT_FRONT_LOCK 0 "LOCK_OFF"  1 "LOCK_ON" 2 "ERROR" 3 "NOT_AVAIL" ;
VAL_ 628 OUT_CENTER_LOCK 0 "LOCK_OFF"  1 "LOCK_ON" 2 "ERROR" 3 "NOT_AVAIL" ;
VAL_ 628 OUT_REAR_LOCK 0 "LOCK_OFF"  1 "LOCK_ON" 2 "ERROR" 3 "NOT_AVAIL" ;

// DOOR_RPT VALUES
VAL_ 1047 DRIVER_DOOR_OPEN 0 "CLOSED" 1 "OPEN" ;
VAL_ 1047 PASS_DOOR_OPEN 0 "CLOSED" 1 "OPEN" ;
VAL_ 1047 REAR_DRIVER_DOOR_OPEN 0 "CLOSED" 1 "OPEN" ;
VAL_ 1047 REAR_PASS_DOOR_OPEN 0 "CLOSED" 1 "OPEN" ;
VAL_ 1047 HOOD_OPEN 0 "CLOSED" 1 "OPEN" ;
VAL_ 1047 TRUNK_OPEN 0 "CLOSED" 1 "OPEN" ;
VAL_ 1047 FUEL_DOOR_OPEN 0 "CLOSED" 1 "OPEN" ;
VAL_ 1047 CARGO_DOOR_OPEN 0 "CLOSED" 1 "OPEN" ;
VAL_ 1047 DRIVER_DOOR_OPEN_AVAIL 0 "NOT_AVAILABLE" 1 "AVAILABLE" ;
VAL_ 1047 PASS_DOOR_OPEN_AVAIL 0 "NOT_AVAILABLE" 1 "AVAILABLE" ;
VAL_ 1047 REAR_DRIVER_DOOR_OPEN_AVAIL 0 "NOT_AVAILABLE" 1 "AVAILABLE" ;
VAL_ 1047 REAR_PASS_DOOR_OPEN_AVAIL 0 "NOT_AVAILABLE" 1 "AVAILABLE" ;
VAL_ 1047 HOOD_OPEN_AVAIL 0 "NOT_AVAILABLE" 1 "AVAILABLE" ;
VAL_ 1047 TRUNK_OPEN_AVAIL 0 "NOT_AVAILABLE" 1 "AVAILABLE" ;
VAL_ 1047 FUEL_DOOR_OPEN_AVAIL 0 "NOT_AVAILABLE" 1 "AVAILABLE" ;
VAL_ 1047 CARGO_DOOR_OPEN_AVAIL 0 "NOT_AVAILABLE" 1 "AVAILABLE" ;

// DRIVE_TRAIN_FEATURE_RPT VALUES
VAL_ 1055 ANTILOCK_BRAKE_ACTIVE 0 "NOT_ACTIVE" 1 "ACTIVE" ;
VAL_ 1055 TRACTION_CONTROL_ACTIVE 0 "NOT_ACTIVE" 1 "ACTIVE" ;
VAL_ 1055 FOUR_WHEEL_DRIVE_ACTIVE 0 "NOT_ACTIVE" 1 "ACTIVE" ;
VAL_ 1055 ANTILOCK_BRAKE_DISABLED  0 "NOT_DISABLED" 1 "DISABLED";
VAL_ 1055 ANTILOCK_BRAKE_ACTIVE_AVAIL 0 "NOT_AVAILABLE" 1 "AVAILABLE" ;
VAL_ 1055 TRACTION_CONTROL_ACTIVE_AVAIL 0 "NOT_AVAILABLE" 1 "AVAILABLE" ;
VAL_ 1055 FOUR_WHEEL_DRIVE_ACTIVE_AVAIL 0 "NOT_AVAILABLE" 1 "AVAILABLE" ;
VAL_ 1055 ANTILOCK_BRAKE_DISABLED_AVAIL 0 "NOT_AVAILABLE" 1 "AVAILABLE";
VAL_ 1055 DRIVE_MODE 0 "NORMAL" 1 "ECO" 2 "SPORT" ;
VAL_ 1055 DRIVE_MODE_AVAIL 0 "NOT_AVAILABLE" 1 "AVAILABLE" ;
VAL_ 1055 TRACTION_CONTROL_DISABLED  0 "NOT_DISABLED" 1 "DISABLED";
VAL_ 1055 TRACTION_CONTROL_DISABLED_AVAIL 0 "NOT_AVAILABLE" 1 "AVAILABLE";

// ENGINE_BRAKE_AUX_RPT VALUES
VAL_ 836 ENGINE_BRAKE_STATUS 0 "BRAKING_NOT_ACTIVE" 1 "BRAKING_ACTIVE" 2 "ERROR" 3 "NOT_AVAIL";
VAL_ 836 ACTUAL_ENGINE_BRK_TORQUE 251 "RESERVED" 252 "RESERVED" 253 "RESERVED" 254 "ERROR" 255 "NOT_AVAIL";
VAL_ 836 INTENDED_ENGINE_BRK_TORQUE 251 "RESERVED" 252 "RESERVED" 253 "RESERVED" 254 "ERROR" 255 "NOT_AVAIL";
VAL_ 836 ENGINE_BRAKE_STATUS_AVAIL 0 "NOT_AVAILABLE" 1 "AVAILABLE";
VAL_ 836 ACTUAL_ENGINE_BRK_TORQUE_AVAIL 0 "NOT_AVAILABLE" 1 "AVAILABLE";
VAL_ 836 INTENDED_ENGINE_BRK_TORQUE_AVAIL 0 "NOT_AVAILABLE" 1 "AVAILABLE";

// ENGINE_BRAKE_CMD VALUES
VAL_ 324 ENABLE 0 "DISABLE" 1 "ENABLE" ;
VAL_ 324 IGNORE_OVERRIDES 0 "FALSE" 1 "TRUE" ;
VAL_ 324 CLEAR_OVERRIDE 0 "FALSE" 1 "TRUE" ;
VAL_ 324 ENGINE_BRAKE_CMD 0 "OFF" 1 "LEVEL_1" 2 "LEVEL_2" 3 "LEVEL_3" 4 "LEVEL_4" 5 "LEVEL_5" ;
VAL_ 324 AUTO_CMD 0 "AUTO_OFF" 1 "AUTO_ON" ;

// ENGINE_BRAKE_RPT VALUES
VAL_ 580 ENABLED 0 "FALSE" 1 "TRUE" ;
VAL_ 580 OVERRIDE_ACTIVE 0 "FALSE" 1 "TRUE" ;
VAL_ 580 COMMAND_OUTPUT_FAULT 0 "NO_FAULT" 1 "FAULT" ;
VAL_ 580 INPUT_OUTPUT_FAULT 0 "NO_FAULT" 1 "FAULT" ;
VAL_ 580 OUTPUT_REPORTED_FAULT 0 "NO_FAULT" 1 "FAULT" ;
VAL_ 580 PACMOD_FAULT 0 "NO_FAULT" 1 "FAULT" ;
VAL_ 580 VEHICLE_FAULT 0 "NO_FAULT" 1 "FAULT" ;
VAL_ 580 COMMAND_TIMEOUT 0 "NO_TIMEOUT" 1 "TIMEOUT" ;
VAL_ 580 MANUAL_INPUT 0 "OFF" 1 "LEVEL_1" 2 "LEVEL_2" 3 "LEVEL_3" 4 "LEVEL_4" 5 "LEVEL_5" 251 "RESERVED" 252 "RESERVED" 253 "RESERVED" 254 "ERROR" 255 "NOT_AVAIL" ;
VAL_ 580 COMMANDED_VALUE 0 "OFF" 1 "LEVEL_1" 2 "LEVEL_2" 3 "LEVEL_3" 4 "LEVEL_4" 5 "LEVEL_5" 251 "RESERVED" 252 "RESERVED" 253 "RESERVED" 254 "ERROR" 255 "NOT_AVAIL" ;
VAL_ 580 OUTPUT_VALUE 0 "OFF" 1 "LEVEL_1" 2 "LEVEL_2" 3 "LEVEL_3" 4 "LEVEL_4" 5 "LEVEL_5" 251 "RESERVED" 252 "RESERVED" 253 "RESERVED" 254 "ERROR" 255 "NOT_AVAIL" ;
VAL_ 580 MAN_AUTO 0 "AUTO_OFF" 1 "AUTO_ON" 2 "ERROR" 3 "NOT_AVAIL" ;
VAL_ 580 CMD_AUTO 0 "AUTO_OFF" 1 "AUTO_ON" 2 "ERROR" 3 "NOT_AVAIL" ;
VAL_ 580 OUT_AUTO 0 "AUTO_OFF" 1 "AUTO_ON" 2 "ERROR" 3 "NOT_AVAIL" ;

// ENGINE_CMD VALUES
VAL_ 360 ENABLE 0 "DISABLE" 1 "ENABLE" ;
VAL_ 360 IGNORE_OVERRIDES 0 "FALSE" 1 "TRUE" ;
VAL_ 360 CLEAR_OVERRIDE 0 "FALSE" 1 "TRUE" ;
VAL_ 360 ENGINE_CMD 0 "NO_ACTION" 1 "ENGINE_OFF" ;

// ENGINE_RPT VALUES
VAL_ 616 ENABLED 0 "FALSE" 1 "TRUE" ;
VAL_ 616 OVERRIDE_ACTIVE 0 "FALSE" 1 "TRUE" ;
VAL_ 616 COMMAND_OUTPUT_FAULT 0 "NO_FAULT" 1 "FAULT" ;
VAL_ 616 INPUT_OUTPUT_FAULT 0 "NO_FAULT" 1 "FAULT" ;
VAL_ 616 OUTPUT_REPORTED_FAULT 0 "NO_FAULT" 1 "FAULT" ;
VAL_ 616 PACMOD_FAULT 0 "NO_FAULT" 1 "FAULT" ;
VAL_ 616 VEHICLE_FAULT 0 "NO_FAULT" 1 "FAULT" ;
VAL_ 616 COMMAND_TIMEOUT 0 "NO_TIMEOUT" 1 "TIMEOUT" ;
VAL_ 616 MANUAL_INPUT 0 "OFF" 1 "ACC" 2 "ON" 3 "START" 4 "RUN" 251 "RESERVED" 252 "RESERVED" 253 "RESERVED" 254 "ERROR" 255 "NOT_AVAIL" ;
VAL_ 616 COMMANDED_VALUE 0 "NO_ACTION" 1 "ENGINE_OFF" 251 "RESERVED" 252 "RESERVED" 253 "RESERVED" 254 "ERROR" 255 "NOT_AVAIL" ;
VAL_ 616 OUTPUT_VALUE 1 "ENGINE_OFF" 2 "ENGINE_RUNNING" 251 "RESERVED" 252 "RESERVED" 253 "RESERVED" 254 "ERROR" 255 "NOT_AVAIL" ;

// ENGINE_AUX_RPT VALUES
VAL_ 1040 ENGINE_SPEED 65531 "RESERVED" 65532 "RESERVED" 65533 "RESERVED" 65534 "ERROR" 65535 "NOT_AVAIL";
VAL_ 1040 ENGINE_TORQUE 65531 "RESERVED" 65532 "RESERVED" 65533 "RESERVED" 65534 "ERROR" 65535 "NOT_AVAIL";
VAL_ 1040 ENGINE_COOLANT_TEMP 251 "RESERVED" 252 "RESERVED" 253 "RESERVED" 254 "ERROR" 255 "NOT_AVAIL";
VAL_ 1040 ENGINE_SPEED_AVAIL 0 "NOT_AVAILABLE" 1 "AVAILABLE" ;
VAL_ 1040 ENGINE_TORQUE_AVAIL 0 "NOT_AVAILABLE" 1 "AVAILABLE" ;
VAL_ 1040 ENGINE_COOLANT_TEMP_AVAIL 0 "NOT_AVAILABLE" 1 "AVAILABLE" ;
VAL_ 1040 FUEL_LEVEL_AVAIL 0 "NOT_AVAILABLE" 1 "AVAILABLE" ;
VAL_ 1040 DIESEL_EXHAUST_FLUID_LEVEL_AVAIL 0 "NOT_AVAILABLE" 1 "AVAILABLE" ;
VAL_ 1040 FUEL_LEVEL 251 "RESERVED" 252 "RESERVED" 253 "RESERVED" 254 "ERROR" 255 "NOT_AVAIL";
VAL_ 1040 DIESEL_EXHAUST_FLUID_LEVEL 251 "RESERVED" 252 "RESERVED" 253 "RESERVED" 254 "ERROR" 255 "NOT_AVAIL";

// ENGINE_AUX_RPT_2 VALUES
VAL_ 1061 FUEL_RATE 65531 "RESERVED" 65532 "RESERVED" 65533 "RESERVED" 65534 "ERROR" 65535 "NOT_AVAIL";
VAL_ 1061 FUEL_RATE_AVAIL 0 "NOT_AVAILABLE" 1 "AVAILABLE";
VAL_ 1061 OIL_LEVEL_AVAIL 0 "NOT_AVAILABLE" 1 "AVAILABLE";
VAL_ 1061 OIL_PRESSURE_AVAIL 0 "NOT_AVAILABLE" 1 "AVAILABLE";
VAL_ 1061 OIL_LEVEL 251 "RESERVED" 252 "RESERVED" 253 "RESERVED" 254 "ERROR" 255 "NOT_AVAIL";
VAL_ 1061 OIL_PRESSURE 251 "RESERVED" 252 "RESERVED" 253 "RESERVED" 254 "ERROR" 255 "NOT_AVAIL";

// ENGINE_LOAD_FACTOR_RPT VALUES
VAL_ 1063 DRVR_DEMANDED_ENG_TORQUE 251 "RESERVED" 252 "RESERVED" 253 "RESERVED" 254 "ERROR" 255 "NOT_AVAIL";
VAL_ 1063 ACTUAL_ENGINE_TORQUE 251 "RESERVED" 252 "RESERVED" 253 "RESERVED" 254 "ERROR" 255 "NOT_AVAIL";
VAL_ 1063 ENG_LOAD_AT_CURRENT_SPEED 251 "RESERVED" 252 "RESERVED" 253 "RESERVED" 254 "ERROR" 255 "NOT_AVAIL";
VAL_ 1063 REFERENCE_ENGINE_TORQUE 65531 "RESERVED" 65532 "RESERVED" 65533 "RESERVED" 65534 "ERROR" 65535 "NOT_AVAIL";
VAL_ 1063 DRVR_DEMANDED_ENG_TORQUE_AVAIL 0 "NOT_AVAILABLE" 1 "AVAILABLE";
VAL_ 1063 ACTUAL_ENGINE_TORQUE_AVAIL 0 "NOT_AVAILABLE" 1 "AVAILABLE";
VAL_ 1063 ENG_LOAD_AT_CURRENT_SPEED_AVAIL 0 "NOT_AVAILABLE" 1 "AVAILABLE";
VAL_ 1063 REFERENCE_ENGINE_TORQUE_AVAIL 0 "NOT_AVAILABLE" 1 "AVAILABLE";

// ESTOP_RPT VALUES
VAL_ 1052 ESTOP 0 "RELEASED" 1 "PRESSED" ;
VAL_ 1052 ESTOP_FAULT 0 "NO_FAULT" 1 "FAULT" ;

// EXHAUST_BRAKE_CMD VALUES
VAL_ 325 ENABLE 0 "DISABLE" 1 "ENABLE" ;
VAL_ 325 IGNORE_OVERRIDES 0 "FALSE" 1 "TRUE" ;
VAL_ 325 CLEAR_OVERRIDE 0 "FALSE" 1 "TRUE" ;
VAL_ 325 EXHAUST_BRAKE_CMD 0 "OFF" 1 "ON" ;

// EXHAUST_BRAKE_RPT VALUES
VAL_ 581 ENABLED 0 "FALSE" 1 "TRUE" ;
VAL_ 581 OVERRIDE_ACTIVE 0 "FALSE" 1 "TRUE" ;
VAL_ 581 COMMAND_OUTPUT_FAULT 0 "NO_FAULT" 1 "FAULT" ;
VAL_ 581 INPUT_OUTPUT_FAULT 0 "NO_FAULT" 1 "FAULT" ;
VAL_ 581 OUTPUT_REPORTED_FAULT 0 "NO_FAULT" 1 "FAULT" ;
VAL_ 581 PACMOD_FAULT 0 "NO_FAULT" 1 "FAULT" ;
VAL_ 581 VEHICLE_FAULT 0 "NO_FAULT" 1 "FAULT" ;
VAL_ 581 COMMAND_TIMEOUT 0 "NO_TIMEOUT" 1 "TIMEOUT" ;
VAL_ 581 MANUAL_INPUT 0 "OFF" 1 "ON" 251 "RESERVED" 252 "RESERVED" 253 "RESERVED" 254 "ERROR" 255 "NOT_AVAIL" ;
VAL_ 581 COMMANDED_VALUE 0 "OFF" 1 "ON" 251 "RESERVED" 252 "RESERVED" 253 "RESERVED" 254 "ERROR" 255 "NOT_AVAIL" ;
VAL_ 581 OUTPUT_VALUE 0 "OFF" 1 "ON" 251 "RESERVED" 252 "RESERVED" 253 "RESERVED" 254 "ERROR" 255 "NOT_AVAIL" ;

// FIRE_SUPPRESSION_RPT VALUES
VAL_ 1042 FIRE_SUPPRESSION_ALARM_STATUS 0 "NOT_ALARMING" 1 "ALARMING" 14 "ERROR" 15 "NOT_AVAIL" ;

// GLOBAL_CMD VALUES
VAL_ 128 CLEAR_FAULTS 0 "FALSE" 1 "TRUE" ;
VAL_ 128 CLEAR_OVERRIDES 0 "FALSE" 1 "TRUE" ;
VAL_ 128 SANITY_CHECK_REQUIRED 0 "NOT_REQUIRED" 1 "REQUIRED" ;
VAL_ 128 DEVELOPMENT_MODE_REQUEST 0 "FALSE" 1 "TRUE" ;

// GLOBAL_RPT VALUES
VAL_ 16 PACMOD_SYSTEM_ENABLED 0 "CONTROL_DISABLED" 1 "CONTROL_ENABLED" ;
VAL_ 16 PACMOD_SYSTEM_OVERRIDE_ACTIVE 0 "NOT_OVERRIDDEN" 1 "OVERRIDDEN" ;
VAL_ 16 USR_CAN_TIMEOUT 0 "FALSE" 1 "TRUE" ;
VAL_ 16 STR_CAN_TIMEOUT 0 "NO_ACTIVE_CAN_TIMEOUT" 1 "ACTIVE_CAN_TIMEOUT" ;
VAL_ 16 BRK_CAN_TIMEOUT 0 "NO_ACTIVE_CAN_TIMEOUT" 1 "ACTIVE_CAN_TIMEOUT" ;
VAL_ 16 PACMOD_SUBSYSTEM_TIMEOUT 0 "FALSE" 1 "TRUE" ;
VAL_ 16 VEH_CAN_TIMEOUT 0 "FALSE" 1 "TRUE" ;
VAL_ 16 PACMOD_SYSTEM_FAULT_ACTIVE 0 "FALSE" 1 "TRUE" ;
VAL_ 16 SUPERVISORY_ENABLE_REQUIRED 0 "NOT_REQUIRED" 1 "REQUIRED" ;
VAL_ 16 CONFIG_FAULT_ACTIVE 0 "FALSE" 1 "TRUE" ;

// GLOBAL_RPT_2 VALUES
VAL_ 17 SYSTEM_ENABLED 0 "CONTROL_DISABLED" 1 "CONTROL_ENABLED" ;
VAL_ 17 SYSTEM_OVERRIDE_ACTIVE 0 "NOT_OVERRIDDEN" 1 "OVERRIDDEN" ;
VAL_ 17 SYSTEM_FAULT_ACTIVE 0 "FALSE" 1 "TRUE" ;
VAL_ 17 SUPERVISORY_ENABLE_REQUIRED 0 "NOT_REQUIRED" 1 "REQUIRED" ;
VAL_ 17 DISABLE_ALL_SYSTEMS 0 "FALSE" 1 "TRUE" ;
VAL_ 17 SYSTEM_READY 0 "NOT_READY" 1 "READY" ;
VAL_ 17 ENABLE_METHOD 0 "INDIVIDUAL_SYSTEM_ENABLE" 1 "GLOBAL_SYSTEM_ENABLE" ;
VAL_ 17 OVERRIDE_MODE 0 "OVERRIDES_DISABLED" 1 "OVERRIDES_ENABLED" ;
VAL_ 17 DEVELOPMENT_MODE 0 "FALSE" 1 "TRUE" ;
VAL_ 17 DEVELOPMENT_MODE_ALLOWED 0 "FALSE" 1 "TRUE" ;

// GNSS_TIME VALUES
VAL_ 1082 GNSS_TIMESTAMP 281474976710651 "RESERVED" 281474976710652 "RESERVED" 281474976710653 "RESERVED" 281474976710654 "ERROR" 281474976710655 "NOT_AVAIL" ;

// HAZARD_LIGHTS_CMD VALUES
VAL_ 276 ENABLE 0 "DISABLE" 1 "ENABLE" ;
VAL_ 276 IGNORE_OVERRIDES 0 "FALSE" 1 "TRUE" ;
VAL_ 276 CLEAR_OVERRIDE 0 "FALSE" 1 "TRUE" ;
VAL_ 276 HAZARD_LIGHTS_CMD 0 "OFF" 1 "ON" ;

// HAZARD_LIGHTS_RPT VALUES
VAL_ 532 ENABLED 0 "FALSE" 1 "TRUE" ;
VAL_ 532 OVERRIDE_ACTIVE 0 "FALSE" 1 "TRUE" ;
VAL_ 532 COMMAND_OUTPUT_FAULT 0 "NO_FAULT" 1 "FAULT" ;
VAL_ 532 INPUT_OUTPUT_FAULT 0 "NO_FAULT" 1 "FAULT" ;
VAL_ 532 OUTPUT_REPORTED_FAULT 0 "NO_FAULT" 1 "FAULT" ;
VAL_ 532 PACMOD_FAULT 0 "NO_FAULT" 1 "FAULT" ;
VAL_ 532 VEHICLE_FAULT 0 "NO_FAULT" 1 "FAULT" ;
VAL_ 532 COMMAND_TIMEOUT 0 "NO_TIMEOUT" 1 "TIMEOUT" ;
VAL_ 532 MANUAL_INPUT 0 "OFF/NOT_PRESSED" 1 "ON/PRESSED" 251 "RESERVED" 252 "RESERVED" 253 "RESERVED" 254 "ERROR" 255 "NOT_AVAIL" ;
VAL_ 532 COMMANDED_VALUE 0 "OFF" 1 "ON" 251 "RESERVED" 252 "RESERVED" 253 "RESERVED" 254 "ERROR" 255 "NOT_AVAIL" ;
VAL_ 532 OUTPUT_VALUE 0 "OFF/NOT_PRESSED" 1 "ON/PRESSED" 251 "RESERVED" 252 "RESERVED" 253 "RESERVED" 254 "ERROR" 255 "NOT_AVAIL" ;

// HEADLIGHT_AUX_RPT VALUES
VAL_ 792 HEADLIGHTS_ON 0 "OFF" 1 "ON" ;
VAL_ 792 HEADLIGHTS_ON_BRIGHT 0 "OFF" 1 "ON" ;
VAL_ 792 FOG_LIGHTS_ON 0 "OFF" 1 "ON" ;
VAL_ 792 HEADLIGHTS_MODE 3 "HEADLIGHTS_ON_AUTO_MODE" 2 "HEADLIGHTS_ON_MANUAL_MODE" 1 "PARKING_LIGHTS_ONLY" 0 "HEADLIGHTS_OFF" ;
VAL_ 792 HEADLIGHTS_ON_AVAIL 0 "NOT_AVAILABLE" 1 "AVAILABLE" ;
VAL_ 792 HEADLIGHTS_ON_BRIGHT_AVAIL 0 "NOT_AVAILABLE" 1 "AVAILABLE" ;
VAL_ 792 FOG_LIGHTS_ON_AVAIL 0 "NOT_AVAILABLE" 1 "AVAILABLE" ;
VAL_ 792 HEADLIGHTS_MODE_AVAIL 0 "NOT_AVAILABLE" 1 "AVAILABLE" ;

// HEADLIGHT_CMD VALUES
VAL_ 280 ENABLE 0 "DISABLE" 1 "ENABLE" ;
VAL_ 280 IGNORE_OVERRIDES 0 "FALSE" 1 "TRUE" ;
VAL_ 280 CLEAR_OVERRIDE 0 "FALSE" 1 "TRUE" ;
VAL_ 280 HEADLIGHT_CMD 2 "HIGH_BEAMS" 1 "LOW_BEAMS" 0 "HEADLIGHTS_OFF" ;

// HEADLIGHT_RPT VALUES
VAL_ 536 ENABLED 0 "FALSE" 1 "TRUE" ;
VAL_ 536 OVERRIDE_ACTIVE 0 "FALSE" 1 "TRUE" ;
VAL_ 536 COMMAND_OUTPUT_FAULT 0 "NO_FAULT" 1 "FAULT" ;
VAL_ 536 INPUT_OUTPUT_FAULT 0 "NO_FAULT" 1 "FAULT" ;
VAL_ 536 OUTPUT_REPORTED_FAULT 0 "NO_FAULT" 1 "FAULT" ;
VAL_ 536 PACMOD_FAULT 0 "NO_FAULT" 1 "FAULT" ;
VAL_ 536 VEHICLE_FAULT 0 "NO_FAULT" 1 "FAULT" ;
VAL_ 536 COMMAND_TIMEOUT 0 "NO_TIMEOUT" 1 "TIMEOUT" ;
VAL_ 536 MANUAL_INPUT 2 "HIGH_BEAMS" 1 "LOW_BEAMS" 0 "HEADLIGHTS_OFF" 251 "RESERVED" 252 "RESERVED" 253 "RESERVED" 254 "ERROR" 255 "NOT_AVAIL" ;
VAL_ 536 COMMANDED_VALUE 2 "HIGH_BEAMS" 1 "LOW_BEAMS" 0 "HEADLIGHTS_OFF" 251 "RESERVED" 252 "RESERVED" 253 "RESERVED" 254 "ERROR" 255 "NOT_AVAIL" ;
VAL_ 536 OUTPUT_VALUE 2 "HIGH_BEAMS" 1 "LOW_BEAMS" 0 "HEADLIGHTS_OFF" 251 "RESERVED" 252 "RESERVED" 253 "RESERVED" 254 "ERROR" 255 "NOT_AVAIL" ;

// HORN_CMD VALUES
VAL_ 284 ENABLE 0 "DISABLE" 1 "ENABLE" ;
VAL_ 284 IGNORE_OVERRIDES 0 "FALSE" 1 "TRUE" ;
VAL_ 284 CLEAR_OVERRIDE 0 "FALSE" 1 "TRUE" ;
VAL_ 284 HORN_CMD 0 "OFF" 1 "ON" ;

// HORN_RPT VALUES
VAL_ 540 ENABLED 0 "FALSE" 1 "TRUE" ;
VAL_ 540 OVERRIDE_ACTIVE 0 "FALSE" 1 "TRUE" ;
VAL_ 540 COMMAND_OUTPUT_FAULT 0 "NO_FAULT" 1 "FAULT" ;
VAL_ 540 INPUT_OUTPUT_FAULT 0 "NO_FAULT" 1 "FAULT" ;
VAL_ 540 OUTPUT_REPORTED_FAULT 0 "NO_FAULT" 1 "FAULT" ;
VAL_ 540 PACMOD_FAULT 0 "NO_FAULT" 1 "FAULT" ;
VAL_ 540 VEHICLE_FAULT 0 "NO_FAULT" 1 "FAULT" ;
VAL_ 540 COMMAND_TIMEOUT 0 "NO_TIMEOUT" 1 "TIMEOUT" ;
VAL_ 540 MANUAL_INPUT 0 "OFF" 1 "ON" 251 "RESERVED" 252 "RESERVED" 253 "RESERVED" 254 "ERROR" 255 "NOT_AVAIL" ;
VAL_ 540 COMMANDED_VALUE 0 "OFF" 1 "ON" 251 "RESERVED" 252 "RESERVED" 253 "RESERVED" 254 "ERROR" 255 "NOT_AVAIL" ;
VAL_ 540 OUTPUT_VALUE 0 "OFF" 1 "ON" 251 "RESERVED" 252 "RESERVED" 253 "RESERVED" 254 "ERROR" 255 "NOT_AVAIL" ;

// INTERIOR_LIGHTS_RPT VALUES
VAL_ 1046 FRONT_DOME_LIGHTS_ON 0 "OFF" 1 "ON" ;
VAL_ 1046 REAR_DOME_LIGHTS_ON 0 "OFF" 1 "ON" ;
VAL_ 1046 MOOD_LIGHTS_ON 0 "OFF" 1 "ON" ;
VAL_ 1046 AMBIENT_LIGHT_SENSOR 0 "DARK" 1 "BRIGHT" ;
VAL_ 1046 DIM_LEVEL 24 "DIM_LEVEL_23" 23 "DIM_LEVEL_22" 22 "DIM_LEVEL_21" 21 "DIM_LEVEL_20" 20 "DIM_LEVEL_19" 19 "DIM_LEVEL_18" 18 "DIM_LEVEL_17" 17 "DIM_LEVEL_16" 16 "DIM_LEVEL_15" 15 "DIM_LEVEL_14" 14 "DIM_LEVEL_13" 13 "DIM_LEVEL_12" 12 "DIM_LEVEL_MAX" 11 "DIM_LEVEL_11" 10 "DIM_LEVEL_10" 9 "DIM_LEVEL_9" 8 "DIM_LEVEL_8" 7 "DIM_LEVEL_7" 6 "DIM_LEVEL_6" 5 "DIM_LEVEL_5" 4 "DIM_LEVEL_4" 3 "DIM_LEVEL_3" 2 "DIM_LEVEL_2" 1 "DIM_LEVEL_1" 0 "DIM_LEVEL_MIN" ;
VAL_ 1046 FRONT_DOME_LIGHTS_ON_AVAIL 0 "NOT_AVAILABLE" 1 "AVAILABLE" ;
VAL_ 1046 REAR_DOME_LIGHTS_ON_AVAIL 0 "NOT_AVAILABLE" 1 "AVAILABLE" ;
VAL_ 1046 MOOD_LIGHTS_ON_AVAIL 0 "NOT_AVAILABLE" 1 "AVAILABLE" ;
VAL_ 1046 DIM_LEVEL_AVAIL 0 "NOT_AVAILABLE" 1 "AVAILABLE" ;
VAL_ 1046 AMBIENT_LIGHT_SENSOR_AVAIL 0 "NOT_AVAILABLE" 1 "AVAILABLE" ;

// LINEAR_ACCEL_RPT VALUES
VAL_ 1049 LATERAL_NEW_DATA_RX 0 "NEW_DATA_NOT_RX" 1 "NEW_DATA_RX" ;
VAL_ 1049 LONGITUDINAL_NEW_DATA_RX 0 "NEW_DATA_NOT_RX" 1 "NEW_DATA_RX" ;
VAL_ 1049 VERTICAL_NEW_DATA_RX 0 "NEW_DATA_NOT_RX" 1 "NEW_DATA_RX" ;
VAL_ 1049 LATERAL_VALID 0 "NOT_VALID" 1 "VALID" ;
VAL_ 1049 LONGITUDINAL_VALID 0 "NOT_VALID" 1 "VALID" ;
VAL_ 1049 VERTICAL_VALID 0 "NOT_VALID" 1 "VALID" ;

// MARKER_LAMP_CMD VALUES
VAL_ 328 ENABLE 0 "DISABLE" 1 "ENABLE" ;
VAL_ 328 IGNORE_OVERRIDES 0 "FALSE" 1 "TRUE" ;
VAL_ 328 CLEAR_OVERRIDE 0 "FALSE" 1 "TRUE" ;
VAL_ 328 MARKER_LAMP_CMD 0 "OFF" 1 "ON" ;

// MARKER_LAMP_RPT VALUES
VAL_ 584 ENABLED 0 "FALSE" 1 "TRUE" ;
VAL_ 584 OVERRIDE_ACTIVE 0 "FALSE" 1 "TRUE" ;
VAL_ 584 COMMAND_OUTPUT_FAULT 0 "NO_FAULT" 1 "FAULT" ;
VAL_ 584 INPUT_OUTPUT_FAULT 0 "NO_FAULT" 1 "FAULT" ;
VAL_ 584 OUTPUT_REPORTED_FAULT 0 "NO_FAULT" 1 "FAULT" ;
VAL_ 584 PACMOD_FAULT 0 "NO_FAULT" 1 "FAULT" ;
VAL_ 584 VEHICLE_FAULT 0 "NO_FAULT" 1 "FAULT" ;
VAL_ 584 COMMAND_TIMEOUT 0 "NO_TIMEOUT" 1 "TIMEOUT" ;
VAL_ 584 MANUAL_INPUT 0 "OFF" 1 "ON" 251 "RESERVED" 252 "RESERVED" 253 "RESERVED" 254 "ERROR" 255 "NOT_AVAIL" ;
VAL_ 584 COMMANDED_VALUE 0 "OFF" 1 "ON" 251 "RESERVED" 252 "RESERVED" 253 "RESERVED" 254 "ERROR" 255 "NOT_AVAIL" ;
VAL_ 584 OUTPUT_VALUE 0 "OFF" 1 "ON" 251 "RESERVED" 252 "RESERVED" 253 "RESERVED" 254 "ERROR" 255 "NOT_AVAIL" ;

// MEDIA_CONTROLS_CMD VALUES
VAL_ 288 ENABLE 0 "DISABLE" 1 "ENABLE" ;
VAL_ 288 IGNORE_OVERRIDES 0 "FALSE" 1 "TRUE" ;
VAL_ 288 CLEAR_OVERRIDE 0 "FALSE" 1 "TRUE" ;
VAL_ 288 MEDIA_CONTROLS_CMD 6 "MEDIA_CONTROL_VOL_DOWN" 5 "MEDIA_CONTROL_VOL_UP" 4 "MEDIA_CONTROL_NEXT_TRACK_HANG_UP" 3 "MEDIA_CONTROL_PREV_TRACK_ANSWER" 2 "MEDIA_CONTROL_MUTE" 1 "MEDIA_CONTROL_VOICE_COMMAND" 0 "MEDIA_CONTROL_NONE" ;

// MEDIA_CONTROLS_RPT VALUES
VAL_ 544 ENABLED 0 "FALSE" 1 "TRUE" ;
VAL_ 544 OVERRIDE_ACTIVE 0 "FALSE" 1 "TRUE" ;
VAL_ 544 COMMAND_OUTPUT_FAULT 0 "NO_FAULT" 1 "FAULT" ;
VAL_ 544 INPUT_OUTPUT_FAULT 0 "NO_FAULT" 1 "FAULT" ;
VAL_ 544 OUTPUT_REPORTED_FAULT 0 "NO_FAULT" 1 "FAULT" ;
VAL_ 544 PACMOD_FAULT 0 "NO_FAULT" 1 "FAULT" ;
VAL_ 544 VEHICLE_FAULT 0 "NO_FAULT" 1 "FAULT" ;
VAL_ 544 COMMAND_TIMEOUT 0 "NO_TIMEOUT" 1 "TIMEOUT" ;
VAL_ 544 MANUAL_INPUT 0 "MEDIA_CONTROL_NONE" 1 "MEDIA_CONTROL_VOICE_COMMAND" 2 "MEDIA_CONTROL_MUTE" 3 "MEDIA_CONTROL_PREV_TRACK_ANSWER" 4 "MEDIA_CONTROL_NEXT_TRACK_HANG_UP" 5 "MEDIA_CONTROL_VOL_UP" 6 "MEDIA_CONTROL_VOL_DOWN" 251 "RESERVED" 252 "RESERVED" 253 "RESERVED" 254 "ERROR" 255 "NOT_AVAIL" ;
VAL_ 544 COMMANDED_VALUE 0 "MEDIA_CONTROL_NONE" 1 "MEDIA_CONTROL_VOICE_COMMAND" 2 "MEDIA_CONTROL_MUTE" 3 "MEDIA_CONTROL_PREV_TRACK_ANSWER" 4 "MEDIA_CONTROL_NEXT_TRACK_HANG_UP" 5 "MEDIA_CONTROL_VOL_UP" 6 "MEDIA_CONTROL_VOL_DOWN" 251 "RESERVED" 252 "RESERVED" 253 "RESERVED" 254 "ERROR" 255 "NOT_AVAIL" ;
VAL_ 544 OUTPUT_VALUE 0 "MEDIA_CONTROL_NONE" 1 "MEDIA_CONTROL_VOICE_COMMAND" 2 "MEDIA_CONTROL_MUTE" 3 "MEDIA_CONTROL_PREV_TRACK_ANSWER" 4 "MEDIA_CONTROL_NEXT_TRACK_HANG_UP" 5 "MEDIA_CONTROL_VOL_UP" 6 "MEDIA_CONTROL_VOL_DOWN" 251 "RESERVED" 252 "RESERVED" 253 "RESERVED" 254 "ERROR" 255 "NOT_AVAIL" ;

// NOTIFICATION_CMD VALUES
VAL_ 1051 BUZZER_MUTE 0 "NOT_MUTED" 1 "MUTED" ;
VAL_ 1051 UNDERDASH_LIGHTS_WHITE 0 "NO_ACTION" 1 "WHITE" ;

// NOTIFICATION_RPT VALUES
VAL_ 1059 BUZZER_STATUS 0 "OFF" 1 "ON" 2 "MUTED" ;
VAL_ 1059 LIGHT_STATUS 0 "NO_BLINK" 1 "BLINK" ;
VAL_ 1059 LIGHT_COLOR 1 "WHITE" 2 "RED" 3 "GREEN" 4 "BLUE" 5 "PURPLE" 6 "ORANGE" 7 "YELLOW" 8 "TEAL" 9 "PINK" 10 "OFF" ;

// OCCUPANCY_RPT VALUES
VAL_ 1045 DRIVER_SEAT_OCCUPIED 0 "NOT_OCCUPIED" 1 "OCCUPIED" ;
VAL_ 1045 PASS_SEAT_OCCUPIED 0 "NOT_OCCUPIED" 1 "OCCUPIED" ;
VAL_ 1045 REAR_SEAT_OCCUPIED 0 "NOT_OCCUPIED" 1 "OCCUPIED" ;
VAL_ 1045 DRIVER_SEATBELT_BUCKLED 0 "NOT_BUCKLED" 1 "BUCKLED" ;
VAL_ 1045 PASS_SEATBELT_BUCKLED 0 "NOT_BUCKLED" 1 "BUCKLED" ;
VAL_ 1045 DRVR_REAR_SEATBELT_BUCKLED 0 "NOT_BUCKLED" 1 "BUCKLED" ;
VAL_ 1045 CTR_REAR_SEATBELT_BUCKLED 0 "NOT_BUCKLED" 1 "BUCKLED" ;
VAL_ 1045 PASS_REAR_SEATBELT_BUCKLED 0 "NOT_BUCKLED" 1 "BUCKLED" ;
VAL_ 1045 DRIVER_SEAT_OCCUPIED_AVAIL 0 "NOT_AVAILABLE" 1 "AVAILABLE" ;
VAL_ 1045 PASS_SEAT_OCCUPIED_AVAIL 0 "NOT_AVAILABLE" 1 "AVAILABLE" ;
VAL_ 1045 REAR_SEAT_OCCUPIED_AVAIL 0 "NOT_AVAILABLE" 1 "AVAILABLE" ;
VAL_ 1045 DRIVER_SEATBELT_BUCKLED_AVAIL 0 "NOT_AVAILABLE" 1 "AVAILABLE" ;
VAL_ 1045 PASS_SEATBELT_BUCKLED_AVAIL 0 "NOT_AVAILABLE" 1 "AVAILABLE" ;
VAL_ 1045 DRVR_REAR_SEATBELT_BUCKLED_AVAIL 0 "NOT_AVAILABLE" 1 "AVAILABLE" ;
VAL_ 1045 CTR_REAR_SEATBELT_BUCKLED_AVAIL 0 "NOT_AVAILABLE" 1 "AVAILABLE" ;
VAL_ 1045 PASS_REAR_SEATBELT_BUCKLED_AVAIL 0 "NOT_AVAILABLE" 1 "AVAILABLE" ;

// PARKING_BRAKE_AUX_RPT VALUES
VAL_ 804 PARKING_BRAKE_STATUS 0 "RELEASED" 1 "APPLIED" 2 "BETWEEN" 3 "ERROR" ;
VAL_ 804 PARKING_BRAKE_STATUS_AVAIL 0 "NOT_AVAILABLE" 1 "AVAILABLE" ;

// PARKING_BRAKE_CMD VALUES
VAL_ 292 ENABLE 0 "DISABLE" 1 "ENABLE" ;
VAL_ 292 IGNORE_OVERRIDES 0 "FALSE" 1 "TRUE" ;
VAL_ 292 CLEAR_OVERRIDE 0 "FALSE" 1 "TRUE" ;
VAL_ 292 PARKING_BRAKE_CMD 0 "OFF" 1 "ON" ;

// PARKING_BRAKE_RPT VALUES
VAL_ 548 ENABLED 0 "FALSE" 1 "TRUE" ;
VAL_ 548 OVERRIDE_ACTIVE 0 "FALSE" 1 "TRUE" ;
VAL_ 548 COMMAND_OUTPUT_FAULT 0 "NO_FAULT" 1 "FAULT" ;
VAL_ 548 INPUT_OUTPUT_FAULT 0 "NO_FAULT" 1 "FAULT" ;
VAL_ 548 OUTPUT_REPORTED_FAULT 0 "NO_FAULT" 1 "FAULT" ;
VAL_ 548 PACMOD_FAULT 0 "NO_FAULT" 1 "FAULT" ;
VAL_ 548 VEHICLE_FAULT 0 "NO_FAULT" 1 "FAULT" ;
VAL_ 548 COMMAND_TIMEOUT 0 "NO_TIMEOUT" 1 "TIMEOUT" ;
VAL_ 548 MANUAL_INPUT 0 "OFF" 1 "ON" 251 "RESERVED" 252 "RESERVED" 253 "RESERVED" 254 "ERROR" 255 "NOT_AVAIL" ;
VAL_ 548 COMMANDED_VALUE 0 "OFF" 1 "ON" 251 "RESERVED" 252 "RESERVED" 253 "RESERVED" 254 "ERROR" 255 "NOT_AVAIL" ;
VAL_ 548 OUTPUT_VALUE 0 "OFF" 1 "ON" 251 "RESERVED" 252 "RESERVED" 253 "RESERVED" 254 "ERROR" 255 "NOT_AVAIL" ;
VAL_ 548 CONTROL_STATUS 0 "SAFE" 1 "AVAILABLE" ;
VAL_ 548 PERFORMANCE_STATUS 0 "NONE" 1 "CMD_TRACKING_FAILURE" 2 "APPOACHING_OPERATIONAL_LIMITS" 3 "LIMITING_ACTIVE" 4 "LIMITING_IMMINENT" ;
VAL_ 548 SELF_TEST_STATUS 0 "NOT_RUNNING" 1 "IN_PROGRESS" 2 "ERROR" 3 "NOT_AVAIL" ;

// PARKING_BRAKE_RPT_2 VALUES
VAL_ 550 ENABLED 0 "FALSE" 1 "TRUE" ;
VAL_ 550 OVERRIDE_ACTIVE 0 "FALSE" 1 "TRUE" ;
VAL_ 550 COMMAND_OUTPUT_FAULT 0 "NO_FAULT" 1 "FAULT" ;
VAL_ 550 INPUT_OUTPUT_FAULT 0 "NO_FAULT" 1 "FAULT" ;
VAL_ 550 OUTPUT_REPORTED_FAULT 0 "NO_FAULT" 1 "FAULT" ;
VAL_ 550 PACMOD_FAULT 0 "NO_FAULT" 1 "FAULT" ;
VAL_ 550 VEHICLE_FAULT 0 "NO_FAULT" 1 "FAULT" ;
VAL_ 550 COMMAND_TIMEOUT 0 "NO_TIMEOUT" 1 "TIMEOUT" ;
VAL_ 550 MANUAL_INPUT 0 "OFF" 1 "ON" 251 "RESERVED" 252 "RESERVED" 253 "RESERVED" 254 "ERROR" 255 "NOT_AVAIL" ;
VAL_ 550 COMMANDED_VALUE 0 "OFF" 1 "ON" 251 "RESERVED" 252 "RESERVED" 253 "RESERVED" 254 "ERROR" 255 "NOT_AVAIL" ;
VAL_ 550 OUTPUT_VALUE 0 "OFF" 1 "ON" 251 "RESERVED" 252 "RESERVED" 253 "RESERVED" 254 "ERROR" 255 "NOT_AVAIL" ;
VAL_ 550 CONTROL_STATUS 0 "SAFE" 1 "AVAILABLE" ;
VAL_ 550 PERFORMANCE_STATUS 0 "NONE" 1 "CMD_TRACKING_FAILURE" 2 "APPOACHING_OPERATIONAL_LIMITS" 3 "LIMITING_ACTIVE" 4 "LIMITING_IMMINENT" ;
VAL_ 550 SELF_TEST_STATUS 0 "NOT_RUNNING" 1 "IN_PROGRESS" 2 "ERROR" 3 "NOT_AVAIL" ;

// POWER_TAKE_OFF_CMD VALUES
VAL_ 348 ENABLE 0 "DISABLE" 1 "ENABLE" ;
VAL_ 348 IGNORE_OVERRIDES 0 "FALSE" 1 "TRUE" ;
VAL_ 348 CLEAR_OVERRIDE 0 "FALSE" 1 "TRUE" ;
VAL_ 348 POWER_TAKE_OFF_CMD 0 "OFF" 1 "ON" ;

// POWER_TAKE_OFF_RPT VALUES
VAL_ 604 ENABLED 0 "FALSE" 1 "TRUE" ;
VAL_ 604 OVERRIDE_ACTIVE 0 "FALSE" 1 "TRUE" ;
VAL_ 604 COMMAND_OUTPUT_FAULT 0 "NO_FAULT" 1 "FAULT" ;
VAL_ 604 INPUT_OUTPUT_FAULT 0 "NO_FAULT" 1 "FAULT" ;
VAL_ 604 OUTPUT_REPORTED_FAULT 0 "NO_FAULT" 1 "FAULT" ;
VAL_ 604 PACMOD_FAULT 0 "NO_FAULT" 1 "FAULT" ;
VAL_ 604 VEHICLE_FAULT 0 "NO_FAULT" 1 "FAULT" ;
VAL_ 604 COMMAND_TIMEOUT 0 "NO_TIMEOUT" 1 "TIMEOUT" ;
VAL_ 604 MANUAL_INPUT 0 "OFF" 1 "ON" 251 "RESERVED" 252 "RESERVED" 253 "RESERVED" 254 "ERROR" 255 "NOT_AVAIL" ;
VAL_ 604 COMMANDED_VALUE 0 "OFF" 1 "ON" 251 "RESERVED" 252 "RESERVED" 253 "RESERVED" 254 "ERROR" 255 "NOT_AVAIL" ;
VAL_ 604 OUTPUT_VALUE 0 "OFF" 1 "ON" 251 "RESERVED" 252 "RESERVED" 253 "RESERVED" 254 "ERROR" 255 "NOT_AVAIL" ;

// REAR_LIGHTS_RPT VALUES
VAL_ 1048 BRAKE_LIGHTS_ON 0 "OFF" 1 "ON" ;
VAL_ 1048 REVERSE_LIGHTS_ON 0 "OFF" 1 "ON" ;
VAL_ 1048 BRAKE_LIGHTS_ON_AVAIL 0 "NOT_AVAILABLE" 1 "AVAILABLE" ;
VAL_ 1048 REVERSE_LIGHTS_ON_AVAIL 0 "NOT_AVAILABLE" 1 "AVAILABLE" ;

// REAR_PASS_DOOR_CMD VALUES
VAL_ 320 ENABLE 0 "DISABLE" 1 "ENABLE" ;
VAL_ 320 IGNORE_OVERRIDES 0 "FALSE" 1 "TRUE" ;
VAL_ 320 CLEAR_OVERRIDE 0 "FALSE" 1 "TRUE" ;
VAL_ 320 REAR_PASS_DOOR_CMD 0 "NEUTRAL" 1 "OPEN" 2 "CLOSE" ;

// REAR_PASS_DOOR_RPT VALUES
VAL_ 576 ENABLED 0 "FALSE" 1 "TRUE" ;
VAL_ 576 OVERRIDE_ACTIVE 0 "FALSE" 1 "TRUE" ;
VAL_ 576 COMMAND_OUTPUT_FAULT 0 "NO_FAULT" 1 "FAULT" ;
VAL_ 576 INPUT_OUTPUT_FAULT 0 "NO_FAULT" 1 "FAULT" ;
VAL_ 576 OUTPUT_REPORTED_FAULT 0 "NO_FAULT" 1 "FAULT" ;
VAL_ 576 PACMOD_FAULT 0 "NO_FAULT" 1 "FAULT" ;
VAL_ 576 VEHICLE_FAULT 0 "NO_FAULT" 1 "FAULT" ;
VAL_ 576 COMMAND_TIMEOUT 0 "NO_TIMEOUT" 1 "TIMEOUT" ;
VAL_ 576 MANUAL_INPUT 0 "NEUTRAL" 1 "OPEN" 2 "CLOSE" 251 "RESERVED" 252 "RESERVED" 253 "RESERVED" 254 "ERROR" 255 "NOT_AVAIL" ;
VAL_ 576 COMMANDED_VALUE 0 "NEUTRAL" 1 "OPEN" 2 "CLOSE" 251 "RESERVED" 252 "RESERVED" 253 "RESERVED" 254 "ERROR" 255 "NOT_AVAIL" ;
VAL_ 576 OUTPUT_VALUE 0 "NEUTRAL" 1 "OPEN" 2 "CLOSE" 251 "RESERVED" 252 "RESERVED" 253 "RESERVED" 254 "ERROR" 255 "NOT_AVAIL" ;

// REMOTE_STOP_RPT VALUES
VAL_ 1076 REMOTE_STOP_COMMAND 0 "GO" 1 "STOP" 2 "TEST" 251 "RESERVED" 252 "RESERVED" 253 "RESERVED" 254 "ERROR" 255 "NOT_AVAIL";
VAL_ 1076 REMOTE_STOP_TIMEOUT 0 "NO_FAULT" 1 "FAULT" ;
VAL_ 1076 REMOTE_STOP_FAULT 0 "NO_FAULT" 1 "FAULT" ;
VAL_ 1076 REMOTE_STOP_MODE_CHANGE_ALLOWED 0 "NOT_ALLOWED" 1 "ALLOWED" ;

// SAFETY_BRAKE_CMD VALUE
VAL_ 193 SAFETY_BRAKE_CMD 0 "APPLY_BRAKE" 1 "RELEASE_BRAKE" ;

// SAFETY_BRAKE_RPT VALUE
VAL_ 65 COMMANDED_VALUE 0 "APPLY_BRAKE" 1 "RELEASE_BRAKE" ;
VAL_ 65 OUTPUT_VALUE 0 "BRAKE_APPLIED" 1 "BRAKE_RELEASED" 2 "BETWEEN"  3 "OUT_OF_RANGE";
VAL_ 65 COMMAND_REPORTED_FAULT 0 "NO_FAULT" 1 "FAULT" ;
VAL_ 65 COMMAND_TIMEOUT 0 "NO_TIMEOUT" 1 "TIMEOUT" ;
VAL_ 65 COMMAND_PERMITTED 0 "COMMAND_NOT_PERMITTED" 1 "COMMAND_PERMITTED" ;
VAL_ 65 REPORTED_FAULT 0 "NO_FAULT" 1 "FAULT" ;

// SAFETY_FUNC_CMD VALUES
VAL_ 192 COMMAND 0 "NONE" 1 "AUTOMS_READY" 2 "AUTOMS" 3 "MANUAL_READY" 4 "CRITICAL_STOP1" 5 "CRITICAL_STOP2" ;

// SAFETY_FUNC_CRITICAL_STOP_RPT VALUES
VAL_ 1056 AUTOMS_MAN_OPCTRL_FAULT 0 "FALSE" 1 "TRUE";
VAL_ 1056 REMOTE_STOP_FAULT 0 "FALSE" 1 "TRUE";
VAL_ 1056 SAFETY_BRAKE_OPCTRL_OFF 0 "FALSE" 1 "TRUE";
VAL_ 1056 SAFETY_BRAKE_CMD_TIMEOUT 0 "FALSE" 1 "TRUE";
VAL_ 1056 SAFETY_FUNC_CMD_TIMEOUT 0 "FALSE" 1 "TRUE";
VAL_ 1056 SAFETY_FUNC_CRITICAL_STOP_1_CMD 0 "FALSE" 1 "TRUE";
VAL_ 1056 SAFETY_FUNC_CRITICAL_STOP_2_CMD 0 "FALSE" 1 "TRUE";
VAL_ 1056 SAFETY_FUNC_NONE_CMD 0 "FALSE" 1 "TRUE";
VAL_ 1056 PACMOD_SYSTEM_TIMEOUT 0 "FALSE" 1 "TRUE";
VAL_ 1056 PACMOD_SYSTEM_FAULT 0 "FALSE" 1 "TRUE";
VAL_ 1056 PACMOD_SYSTEM_NOT_ACTIVE 0 "FALSE" 1 "TRUE";
VAL_ 1056 VEHICLE_REPORT_TIMEOUT 0 "FALSE" 1 "TRUE";
VAL_ 1056 VEHICLE_REPORT_FAULT 0 "FALSE" 1 "TRUE";
VAL_ 1056 LOW_ENGINE_RPM 0 "FALSE" 1 "TRUE";
VAL_ 1056 PRI_SAFETY_BRAKE_SIGNAL_1_FAULT 0 "FALSE" 1 "TRUE";
VAL_ 1056 PRI_SAFETY_BRAKE_SIGNAL_2_FAULT 0 "FALSE" 1 "TRUE";
VAL_ 1056 SEC_SAFETY_BRAKE_SIGNAL_1_FAULT 0 "FALSE" 1 "TRUE";
VAL_ 1056 SEC_SAFETY_BRAKE_SIGNAL_2_FAULT 0 "FALSE" 1 "TRUE";
VAL_ 1056 PRIMARY_PROCESSOR_FAULT 0 "FALSE" 1 "TRUE";
VAL_ 1056 SECONDARY_PROCESSOR_FAULT 0 "FALSE" 1 "TRUE";
VAL_ 1056 REMOTE_STOP_CMD 0 "FALSE" 1 "TRUE";
VAL_ 1056 PRI_SAFETY_BRAKE_PRESSURE_FAULT 0 "FALSE" 1 "TRUE";
